VERSION "HNNBNNNYNNNNNNNNNNNNNNNNNNNNNNNNNNNNNNNNNN/4/%%%/4/'%**4NNN///"

NS_ :

BS_:

BU_: AWC BAP_Tester BMC_MLBevo BMS_MV BMS_NV CBC DCDC_800V_PAG DCDC_HV DCDC_HV_02 DCDC_IHEV FCU_MLBevo_FCEV Gateway Gateway_PAG Ladegeraet_2 Ladegeraet_Konzern LE1 LE2 LE_MLBevo Sub_Gateway TME

BO_ 881 BMS_CMC_02: 8 BMC_MLBevo
 SG_ BMS_CMC_02_MUX M  : 0|4@1+ (1,0) [0|15] ""  Sub_Gateway
 SG_ BMS_CMC_Zellspannung_081 m0  : 4|12@1+ (1,1000) [1000|5091] "Unit_MilliVolt"  Sub_Gateway
 SG_ BMS_CMC_Zellspannung_086 m1  : 4|12@1+ (1,1000) [1000|5091] "Unit_MilliVolt"  Sub_Gateway
 SG_ BMS_CMC_Zellspannung_091 m2  : 4|12@1+ (1,1000) [1000|5091] "Unit_MilliVolt"  Sub_Gateway
 SG_ BMS_CMC_Zellspannung_096 m3  : 4|12@1+ (1,1000) [1000|5091] "Unit_MilliVolt"  Sub_Gateway
 SG_ BMS_CMC_Zellspannung_101 m4  : 4|12@1+ (1,1000) [1000|5091] "Unit_MilliVolt"  Sub_Gateway
 SG_ BMS_CMC_Zellspannung_106 m5  : 4|12@1+ (1,1000) [1000|5091] "Unit_MilliVolt"  Sub_Gateway
 SG_ BMS_CMC_Zellspannung_111 m6  : 4|12@1+ (1,1000) [1000|5091] "Unit_MilliVolt"  Sub_Gateway
 SG_ BMS_CMC_Zellspannung_116 m7  : 4|12@1+ (1,1000) [1000|5091] "Unit_MilliVolt"  Sub_Gateway
 SG_ BMS_CMC_Zellspannung_121 m8  : 4|12@1+ (1,1000) [1000|5091] "Unit_MilliVolt"  Sub_Gateway
 SG_ BMS_CMC_Zellspannung_126 m9  : 4|12@1+ (1,1000) [1000|5091] "Unit_MilliVolt"  Sub_Gateway
 SG_ BMS_CMC_Zellspannung_131 m10  : 4|12@1+ (1,1000) [1000|5091] "Unit_MilliVolt"  Sub_Gateway
 SG_ BMS_CMC_Zellspannung_136 m11  : 4|12@1+ (1,1000) [1000|5091] "Unit_MilliVolt"  Sub_Gateway
 SG_ BMS_CMC_Zellspannung_141 m12  : 4|12@1+ (1,1000) [1000|5091] "Unit_MilliVolt"  Sub_Gateway
 SG_ BMS_CMC_Zellspannung_146 m13  : 4|12@1+ (1,1000) [1000|5091] "Unit_MilliVolt"  Sub_Gateway
 SG_ BMS_CMC_Zellspannung_151 m14  : 4|12@1+ (1,1000) [1000|5091] "Unit_MilliVolt"  Sub_Gateway
 SG_ BMS_CMC_Zellspannung_156 m15  : 4|12@1+ (1,1000) [1000|5091] "Unit_MilliVolt"  Sub_Gateway
 SG_ BMS_CMC_Zellspannung_082 m0  : 16|12@1+ (1,1000) [1000|5091] "Unit_MilliVolt"  Sub_Gateway
 SG_ BMS_CMC_Zellspannung_087 m1  : 16|12@1+ (1,1000) [1000|5091] "Unit_MilliVolt"  Sub_Gateway
 SG_ BMS_CMC_Zellspannung_092 m2  : 16|12@1+ (1,1000) [1000|5091] "Unit_MilliVolt"  Sub_Gateway
 SG_ BMS_CMC_Zellspannung_097 m3  : 16|12@1+ (1,1000) [1000|5091] "Unit_MilliVolt"  Sub_Gateway
 SG_ BMS_CMC_Zellspannung_102 m4  : 16|12@1+ (1,1000) [1000|5091] "Unit_MilliVolt"  Sub_Gateway
 SG_ BMS_CMC_Zellspannung_107 m5  : 16|12@1+ (1,1000) [1000|5091] "Unit_MilliVolt"  Sub_Gateway
 SG_ BMS_CMC_Zellspannung_112 m6  : 16|12@1+ (1,1000) [1000|5091] "Unit_MilliVolt"  Sub_Gateway
 SG_ BMS_CMC_Zellspannung_117 m7  : 16|12@1+ (1,1000) [1000|5091] "Unit_MilliVolt"  Sub_Gateway
 SG_ BMS_CMC_Zellspannung_122 m8  : 16|12@1+ (1,1000) [1000|5091] "Unit_MilliVolt"  Sub_Gateway
 SG_ BMS_CMC_Zellspannung_127 m9  : 16|12@1+ (1,1000) [1000|5091] "Unit_MilliVolt"  Sub_Gateway
 SG_ BMS_CMC_Zellspannung_132 m10  : 16|12@1+ (1,1000) [1000|5091] "Unit_MilliVolt"  Sub_Gateway
 SG_ BMS_CMC_Zellspannung_137 m11  : 16|12@1+ (1,1000) [1000|5091] "Unit_MilliVolt"  Sub_Gateway
 SG_ BMS_CMC_Zellspannung_142 m12  : 16|12@1+ (1,1000) [1000|5091] "Unit_MilliVolt"  Sub_Gateway
 SG_ BMS_CMC_Zellspannung_147 m13  : 16|12@1+ (1,1000) [1000|5091] "Unit_MilliVolt"  Sub_Gateway
 SG_ BMS_CMC_Zellspannung_152 m14  : 16|12@1+ (1,1000) [1000|5091] "Unit_MilliVolt"  Sub_Gateway
 SG_ BMS_CMC_Zellspannung_157 m15  : 16|12@1+ (1,1000) [1000|5091] "Unit_MilliVolt"  Sub_Gateway
 SG_ BMS_CMC_Zellspannung_083 m0  : 28|12@1+ (1,1000) [1000|5091] "Unit_MilliVolt"  Sub_Gateway
 SG_ BMS_CMC_Zellspannung_088 m1  : 28|12@1+ (1,1000) [1000|5091] "Unit_MilliVolt"  Sub_Gateway
 SG_ BMS_CMC_Zellspannung_093 m2  : 28|12@1+ (1,1000) [1000|5091] "Unit_MilliVolt"  Sub_Gateway
 SG_ BMS_CMC_Zellspannung_098 m3  : 28|12@1+ (1,1000) [1000|5091] "Unit_MilliVolt"  Sub_Gateway
 SG_ BMS_CMC_Zellspannung_103 m4  : 28|12@1+ (1,1000) [1000|5091] "Unit_MilliVolt"  Sub_Gateway
 SG_ BMS_CMC_Zellspannung_108 m5  : 28|12@1+ (1,1000) [1000|5091] "Unit_MilliVolt"  Sub_Gateway
 SG_ BMS_CMC_Zellspannung_113 m6  : 28|12@1+ (1,1000) [1000|5091] "Unit_MilliVolt"  Sub_Gateway
 SG_ BMS_CMC_Zellspannung_118 m7  : 28|12@1+ (1,1000) [1000|5091] "Unit_MilliVolt"  Sub_Gateway
 SG_ BMS_CMC_Zellspannung_123 m8  : 28|12@1+ (1,1000) [1000|5091] "Unit_MilliVolt"  Sub_Gateway
 SG_ BMS_CMC_Zellspannung_128 m9  : 28|12@1+ (1,1000) [1000|5091] "Unit_MilliVolt"  Sub_Gateway
 SG_ BMS_CMC_Zellspannung_133 m10  : 28|12@1+ (1,1000) [1000|5091] "Unit_MilliVolt"  Sub_Gateway
 SG_ BMS_CMC_Zellspannung_138 m11  : 28|12@1+ (1,1000) [1000|5091] "Unit_MilliVolt"  Sub_Gateway
 SG_ BMS_CMC_Zellspannung_143 m12  : 28|12@1+ (1,1000) [1000|5091] "Unit_MilliVolt"  Sub_Gateway
 SG_ BMS_CMC_Zellspannung_148 m13  : 28|12@1+ (1,1000) [1000|5091] "Unit_MilliVolt"  Sub_Gateway
 SG_ BMS_CMC_Zellspannung_153 m14  : 28|12@1+ (1,1000) [1000|5091] "Unit_MilliVolt"  Sub_Gateway
 SG_ BMS_CMC_Zellspannung_158 m15  : 28|12@1+ (1,1000) [1000|5091] "Unit_MilliVolt"  Sub_Gateway
 SG_ BMS_CMC_Zellspannung_084 m0  : 40|12@1+ (1,1000) [1000|5091] "Unit_MilliVolt"  Sub_Gateway
 SG_ BMS_CMC_Zellspannung_089 m1  : 40|12@1+ (1,1000) [1000|5091] "Unit_MilliVolt"  Sub_Gateway
 SG_ BMS_CMC_Zellspannung_094 m2  : 40|12@1+ (1,1000) [1000|5091] "Unit_MilliVolt"  Sub_Gateway
 SG_ BMS_CMC_Zellspannung_099 m3  : 40|12@1+ (1,1000) [1000|5091] "Unit_MilliVolt"  Sub_Gateway
 SG_ BMS_CMC_Zellspannung_104 m4  : 40|12@1+ (1,1000) [1000|5091] "Unit_MilliVolt"  Sub_Gateway
 SG_ BMS_CMC_Zellspannung_109 m5  : 40|12@1+ (1,1000) [1000|5091] "Unit_MilliVolt"  Sub_Gateway
 SG_ BMS_CMC_Zellspannung_114 m6  : 40|12@1+ (1,1000) [1000|5091] "Unit_MilliVolt"  Sub_Gateway
 SG_ BMS_CMC_Zellspannung_119 m7  : 40|12@1+ (1,1000) [1000|5091] "Unit_MilliVolt"  Sub_Gateway
 SG_ BMS_CMC_Zellspannung_124 m8  : 40|12@1+ (1,1000) [1000|5091] "Unit_MilliVolt"  Sub_Gateway
 SG_ BMS_CMC_Zellspannung_129 m9  : 40|12@1+ (1,1000) [1000|5091] "Unit_MilliVolt"  Sub_Gateway
 SG_ BMS_CMC_Zellspannung_134 m10  : 40|12@1+ (1,1000) [1000|5091] "Unit_MilliVolt"  Sub_Gateway
 SG_ BMS_CMC_Zellspannung_139 m11  : 40|12@1+ (1,1000) [1000|5091] "Unit_MilliVolt"  Sub_Gateway
 SG_ BMS_CMC_Zellspannung_144 m12  : 40|12@1+ (1,1000) [1000|5091] "Unit_MilliVolt"  Sub_Gateway
 SG_ BMS_CMC_Zellspannung_149 m13  : 40|12@1+ (1,1000) [1000|5091] "Unit_MilliVolt"  Sub_Gateway
 SG_ BMS_CMC_Zellspannung_154 m14  : 40|12@1+ (1,1000) [1000|5091] "Unit_MilliVolt"  Sub_Gateway
 SG_ BMS_CMC_Zellspannung_159 m15  : 40|12@1+ (1,1000) [1000|5091] "Unit_MilliVolt"  Sub_Gateway
 SG_ BMS_CMC_Zellspannung_085 m0  : 52|12@1+ (1,1000) [1000|5091] "Unit_MilliVolt"  Sub_Gateway
 SG_ BMS_CMC_Zellspannung_090 m1  : 52|12@1+ (1,1000) [1000|5091] "Unit_MilliVolt"  Sub_Gateway
 SG_ BMS_CMC_Zellspannung_095 m2  : 52|12@1+ (1,1000) [1000|5091] "Unit_MilliVolt"  Sub_Gateway
 SG_ BMS_CMC_Zellspannung_100 m3  : 52|12@1+ (1,1000) [1000|5091] "Unit_MilliVolt"  Sub_Gateway
 SG_ BMS_CMC_Zellspannung_105 m4  : 52|12@1+ (1,1000) [1000|5091] "Unit_MilliVolt"  Sub_Gateway
 SG_ BMS_CMC_Zellspannung_110 m5  : 52|12@1+ (1,1000) [1000|5091] "Unit_MilliVolt"  Sub_Gateway
 SG_ BMS_CMC_Zellspannung_115 m6  : 52|12@1+ (1,1000) [1000|5091] "Unit_MilliVolt"  Sub_Gateway
 SG_ BMS_CMC_Zellspannung_120 m7  : 52|12@1+ (1,1000) [1000|5091] "Unit_MilliVolt"  Sub_Gateway
 SG_ BMS_CMC_Zellspannung_125 m8  : 52|12@1+ (1,1000) [1000|5091] "Unit_MilliVolt"  Sub_Gateway
 SG_ BMS_CMC_Zellspannung_130 m9  : 52|12@1+ (1,1000) [1000|5091] "Unit_MilliVolt"  Sub_Gateway
 SG_ BMS_CMC_Zellspannung_135 m10  : 52|12@1+ (1,1000) [1000|5091] "Unit_MilliVolt"  Sub_Gateway
 SG_ BMS_CMC_Zellspannung_140 m11  : 52|12@1+ (1,1000) [1000|5091] "Unit_MilliVolt"  Sub_Gateway
 SG_ BMS_CMC_Zellspannung_145 m12  : 52|12@1+ (1,1000) [1000|5091] "Unit_MilliVolt"  Sub_Gateway
 SG_ BMS_CMC_Zellspannung_150 m13  : 52|12@1+ (1,1000) [1000|5091] "Unit_MilliVolt"  Sub_Gateway
 SG_ BMS_CMC_Zellspannung_155 m14  : 52|12@1+ (1,1000) [1000|5091] "Unit_MilliVolt"  Sub_Gateway
 SG_ BMS_CMC_Zellspannung_160 m15  : 52|12@1+ (1,1000) [1000|5091] "Unit_MilliVolt"  Sub_Gateway

BO_ 2463978713 BMS_CMC_03: 8 BMC_MLBevo
 SG_ BMS_CMC_03_MUX M  : 0|3@1+ (1,0) [0|7] ""  Sub_Gateway
 SG_ BMS_CMC_Temperatur_001 m0  : 8|8@1+ (0.5,-40) [-40.0|86.0] "Unit_DegreCelsi"  Sub_Gateway
 SG_ BMS_CMC_Temperatur_008 m1  : 8|8@1+ (0.5,-40) [-40.0|86.0] "Unit_DegreCelsi"  Sub_Gateway
 SG_ BMS_CMC_Temperatur_015 m2  : 8|8@1+ (0.5,-40) [-40.0|86.0] "Unit_DegreCelsi"  Sub_Gateway
 SG_ BMS_CMC_Temperatur_022 m3  : 8|8@1+ (0.5,-40) [-40.0|86.0] "Unit_DegreCelsi"  Sub_Gateway
 SG_ BMS_CMC_Temperatur_029 m4  : 8|8@1+ (0.5,-40) [-40.0|86.0] "Unit_DegreCelsi"  Sub_Gateway
 SG_ BMS_CMC_Temperatur_036 m5  : 8|8@1+ (0.5,-40) [-40.0|86.0] "Unit_DegreCelsi"  Sub_Gateway
 SG_ BMS_CMC_Temperatur_043 m6  : 8|8@1+ (0.5,-40) [-40.0|86.0] "Unit_DegreCelsi"  Sub_Gateway
 SG_ BMS_CMC_Temperatur_050 m7  : 8|8@1+ (0.5,-40) [-40.0|86.0] "Unit_DegreCelsi"  Sub_Gateway
 SG_ BMS_CMC_Temperatur_002 m0  : 16|8@1+ (0.5,-40) [-40.0|86.0] "Unit_DegreCelsi"  Sub_Gateway
 SG_ BMS_CMC_Temperatur_009 m1  : 16|8@1+ (0.5,-40) [-40.0|86.0] "Unit_DegreCelsi"  Sub_Gateway
 SG_ BMS_CMC_Temperatur_016 m2  : 16|8@1+ (0.5,-40) [-40.0|86.0] "Unit_DegreCelsi"  Sub_Gateway
 SG_ BMS_CMC_Temperatur_023 m3  : 16|8@1+ (0.5,-40) [-40.0|86.0] "Unit_DegreCelsi"  Sub_Gateway
 SG_ BMS_CMC_Temperatur_030 m4  : 16|8@1+ (0.5,-40) [-40.0|86.0] "Unit_DegreCelsi"  Sub_Gateway
 SG_ BMS_CMC_Temperatur_037 m5  : 16|8@1+ (0.5,-40) [-40.0|86.0] "Unit_DegreCelsi"  Sub_Gateway
 SG_ BMS_CMC_Temperatur_044 m6  : 16|8@1+ (0.5,-40) [-40.0|86.0] "Unit_DegreCelsi"  Sub_Gateway
 SG_ BMS_CMC_Temperatur_051 m7  : 16|8@1+ (0.5,-40) [-40.0|86.0] "Unit_DegreCelsi"  Sub_Gateway
 SG_ BMS_CMC_Temperatur_003 m0  : 24|8@1+ (0.5,-40) [-40.0|86.0] "Unit_DegreCelsi"  Sub_Gateway
 SG_ BMS_CMC_Temperatur_010 m1  : 24|8@1+ (0.5,-40) [-40.0|86.0] "Unit_DegreCelsi"  Sub_Gateway
 SG_ BMS_CMC_Temperatur_017 m2  : 24|8@1+ (0.5,-40) [-40.0|86.0] "Unit_DegreCelsi"  Sub_Gateway
 SG_ BMS_CMC_Temperatur_024 m3  : 24|8@1+ (0.5,-40) [-40.0|86.0] "Unit_DegreCelsi"  Sub_Gateway
 SG_ BMS_CMC_Temperatur_031 m4  : 24|8@1+ (0.5,-40) [-40.0|86.0] "Unit_DegreCelsi"  Sub_Gateway
 SG_ BMS_CMC_Temperatur_038 m5  : 24|8@1+ (0.5,-40) [-40.0|86.0] "Unit_DegreCelsi"  Sub_Gateway
 SG_ BMS_CMC_Temperatur_045 m6  : 24|8@1+ (0.5,-40) [-40.0|86.0] "Unit_DegreCelsi"  Sub_Gateway
 SG_ BMS_CMC_Temperatur_052 m7  : 24|8@1+ (0.5,-40) [-40.0|86.0] "Unit_DegreCelsi"  Sub_Gateway
 SG_ BMS_CMC_Temperatur_004 m0  : 32|8@1+ (0.5,-40) [-40.0|86.0] "Unit_DegreCelsi"  Sub_Gateway
 SG_ BMS_CMC_Temperatur_011 m1  : 32|8@1+ (0.5,-40) [-40.0|86.0] "Unit_DegreCelsi"  Sub_Gateway
 SG_ BMS_CMC_Temperatur_018 m2  : 32|8@1+ (0.5,-40) [-40.0|86.0] "Unit_DegreCelsi"  Sub_Gateway
 SG_ BMS_CMC_Temperatur_025 m3  : 32|8@1+ (0.5,-40) [-40.0|86.0] "Unit_DegreCelsi"  Sub_Gateway
 SG_ BMS_CMC_Temperatur_032 m4  : 32|8@1+ (0.5,-40) [-40.0|86.0] "Unit_DegreCelsi"  Sub_Gateway
 SG_ BMS_CMC_Temperatur_039 m5  : 32|8@1+ (0.5,-40) [-40.0|86.0] "Unit_DegreCelsi"  Sub_Gateway
 SG_ BMS_CMC_Temperatur_046 m6  : 32|8@1+ (0.5,-40) [-40.0|86.0] "Unit_DegreCelsi"  Sub_Gateway
 SG_ BMS_CMC_Temperatur_053 m7  : 32|8@1+ (0.5,-40) [-40.0|86.0] "Unit_DegreCelsi"  Sub_Gateway
 SG_ BMS_CMC_Temperatur_005 m0  : 40|8@1+ (0.5,-40) [-40.0|86.0] "Unit_DegreCelsi"  Sub_Gateway
 SG_ BMS_CMC_Temperatur_012 m1  : 40|8@1+ (0.5,-40) [-40.0|86.0] "Unit_DegreCelsi"  Sub_Gateway
 SG_ BMS_CMC_Temperatur_019 m2  : 40|8@1+ (0.5,-40) [-40.0|86.0] "Unit_DegreCelsi"  Sub_Gateway
 SG_ BMS_CMC_Temperatur_026 m3  : 40|8@1+ (0.5,-40) [-40.0|86.0] "Unit_DegreCelsi"  Sub_Gateway
 SG_ BMS_CMC_Temperatur_033 m4  : 40|8@1+ (0.5,-40) [-40.0|86.0] "Unit_DegreCelsi"  Sub_Gateway
 SG_ BMS_CMC_Temperatur_040 m5  : 40|8@1+ (0.5,-40) [-40.0|86.0] "Unit_DegreCelsi"  Sub_Gateway
 SG_ BMS_CMC_Temperatur_047 m6  : 40|8@1+ (0.5,-40) [-40.0|86.0] "Unit_DegreCelsi"  Sub_Gateway
 SG_ BMS_CMC_Temperatur_054 m7  : 40|8@1+ (0.5,-40) [-40.0|86.0] "Unit_DegreCelsi"  Sub_Gateway
 SG_ BMS_CMC_Temperatur_006 m0  : 48|8@1+ (0.5,-40) [-40.0|86.0] "Unit_DegreCelsi"  Sub_Gateway
 SG_ BMS_CMC_Temperatur_013 m1  : 48|8@1+ (0.5,-40) [-40.0|86.0] "Unit_DegreCelsi"  Sub_Gateway
 SG_ BMS_CMC_Temperatur_020 m2  : 48|8@1+ (0.5,-40) [-40.0|86.0] "Unit_DegreCelsi"  Sub_Gateway
 SG_ BMS_CMC_Temperatur_027 m3  : 48|8@1+ (0.5,-40) [-40.0|86.0] "Unit_DegreCelsi"  Sub_Gateway
 SG_ BMS_CMC_Temperatur_034 m4  : 48|8@1+ (0.5,-40) [-40.0|86.0] "Unit_DegreCelsi"  Sub_Gateway
 SG_ BMS_CMC_Temperatur_041 m5  : 48|8@1+ (0.5,-40) [-40.0|86.0] "Unit_DegreCelsi"  Sub_Gateway
 SG_ BMS_CMC_Temperatur_048 m6  : 48|8@1+ (0.5,-40) [-40.0|86.0] "Unit_DegreCelsi"  Sub_Gateway
 SG_ BMS_CMC_Temperatur_055 m7  : 48|8@1+ (0.5,-40) [-40.0|86.0] "Unit_DegreCelsi"  Sub_Gateway
 SG_ BMS_CMC_Temperatur_007 m0  : 56|8@1+ (0.5,-40) [-40.0|86.0] "Unit_DegreCelsi"  Sub_Gateway
 SG_ BMS_CMC_Temperatur_014 m1  : 56|8@1+ (0.5,-40) [-40.0|86.0] "Unit_DegreCelsi"  Sub_Gateway
 SG_ BMS_CMC_Temperatur_021 m2  : 56|8@1+ (0.5,-40) [-40.0|86.0] "Unit_DegreCelsi"  Sub_Gateway
 SG_ BMS_CMC_Temperatur_028 m3  : 56|8@1+ (0.5,-40) [-40.0|86.0] "Unit_DegreCelsi"  Sub_Gateway
 SG_ BMS_CMC_Temperatur_035 m4  : 56|8@1+ (0.5,-40) [-40.0|86.0] "Unit_DegreCelsi"  Sub_Gateway
 SG_ BMS_CMC_Temperatur_042 m5  : 56|8@1+ (0.5,-40) [-40.0|86.0] "Unit_DegreCelsi"  Sub_Gateway
 SG_ BMS_CMC_Temperatur_049 m6  : 56|8@1+ (0.5,-40) [-40.0|86.0] "Unit_DegreCelsi"  Sub_Gateway
 SG_ BMS_CMC_Temperatur_056 m7  : 56|8@1+ (0.5,-40) [-40.0|86.0] "Unit_DegreCelsi"  Sub_Gateway

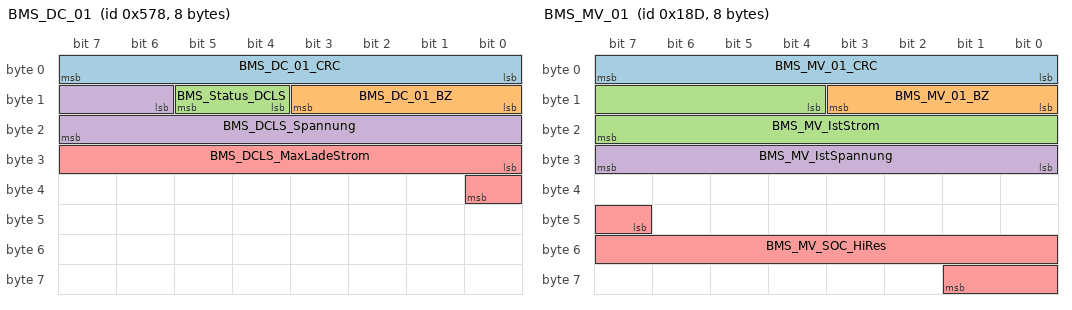
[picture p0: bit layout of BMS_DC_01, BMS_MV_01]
BO_ 1400 BMS_DC_01: 8 BMC_MLBevo
 SG_ BMS_DC_01_CRC : 0|8@1+ (1,0) [0|255] ""  Ladegeraet_Konzern
 SG_ BMS_DC_01_BZ : 8|4@1+ (1,0) [0|15] ""  Ladegeraet_Konzern
 SG_ BMS_Status_DCLS : 12|2@1+ (1.0,0.0) [0.0|3] ""  Ladegeraet_Konzern
 SG_ BMS_DCLS_Spannung : 14|10@1+ (1,0) [0|1021] "Unit_Volt"  Ladegeraet_Konzern
 SG_ BMS_DCLS_MaxLadeStrom : 24|9@1+ (1,0) [0|400] "Unit_Amper"  Ladegeraet_Konzern

BO_ 397 BMS_MV_01: 8 BMS_MV
 SG_ BMS_MV_01_CRC : 0|8@1+ (1,0) [0|255] ""  Gateway,Gateway_PAG
 SG_ BMS_MV_01_BZ : 8|4@1+ (1,0) [0|15] ""  Gateway,Gateway_PAG
 SG_ BMS_MV_IstStrom : 12|12@1+ (1,-2047) [-2047|2046] "Unit_Amper"  DCDC_IHEV,Gateway,Gateway_PAG
 SG_ BMS_MV_IstSpannung : 24|8@1+ (0.25,0) [0.00|63.25] "Unit_Volt"  DCDC_IHEV,Gateway,Gateway_PAG
 SG_ BMS_MV_SOC_HiRes : 47|11@1+ (0.05,0) [0.00|100.00] "Unit_PerCent"  Gateway,Gateway_PAG

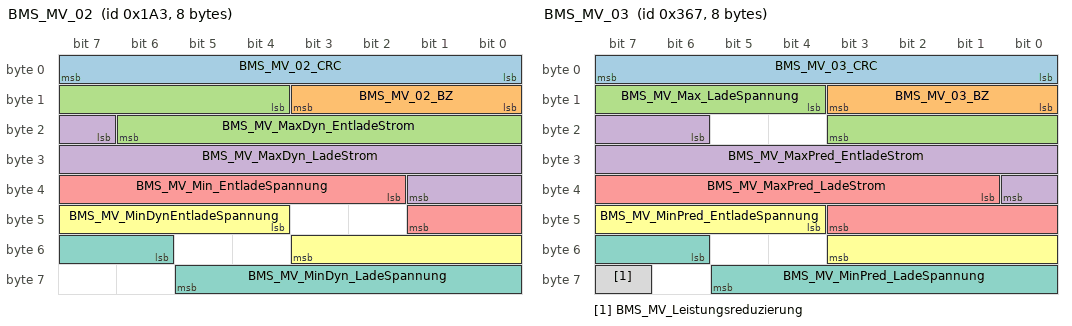
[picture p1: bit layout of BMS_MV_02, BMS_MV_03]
BO_ 419 BMS_MV_02: 8 BMS_MV
 SG_ BMS_MV_02_CRC : 0|8@1+ (1,0) [0|255] ""  Gateway,Gateway_PAG
 SG_ BMS_MV_02_BZ : 8|4@1+ (1,0) [0|15] ""  Gateway,Gateway_PAG
 SG_ BMS_MV_MaxDyn_EntladeStrom : 12|11@1+ (1,0) [0|2045] "Unit_Amper"  DCDC_IHEV,Gateway,Gateway_PAG
 SG_ BMS_MV_MaxDyn_LadeStrom : 23|11@1+ (1,0) [0|2045] "Unit_Amper"  Gateway,Gateway_PAG
 SG_ BMS_MV_Min_EntladeSpannung : 34|8@1+ (0.25,0) [0.00|63.25] "Unit_Volt"  Gateway,Gateway_PAG
 SG_ BMS_MV_MinDynEntladeSpannung : 44|8@1+ (0.25,0) [0.00|63.25] "Unit_Volt"  Gateway,Gateway_PAG
 SG_ BMS_MV_MinDyn_LadeSpannung : 54|8@1+ (0.25,0) [0.00|63.25] "Unit_Volt"  Gateway,Gateway_PAG

BO_ 871 BMS_MV_03: 8 BMS_MV
 SG_ BMS_MV_03_CRC : 0|8@1+ (1,0) [0|255] ""  Gateway,Gateway_PAG
 SG_ BMS_MV_03_BZ : 8|4@1+ (1,0) [0|15] ""  Gateway,Gateway_PAG
 SG_ BMS_MV_Max_LadeSpannung : 12|8@1+ (0.25,0) [0.00|63.25] "Unit_Volt"  Gateway,Gateway_PAG
 SG_ BMS_MV_MaxPred_EntladeStrom : 22|11@1+ (1,0) [0|2045] "Unit_Amper"  Gateway,Gateway_PAG
 SG_ BMS_MV_MaxPred_LadeStrom : 33|11@1+ (1,0) [0|2045] "Unit_Amper"  Gateway,Gateway_PAG
 SG_ BMS_MV_MinPred_EntladeSpannung : 44|8@1+ (0.25,0) [0.00|63.25] "Unit_Volt"  Gateway,Gateway_PAG
 SG_ BMS_MV_MinPred_LadeSpannung : 54|8@1+ (0.25,0) [0.00|63.25] "Unit_Volt"  Gateway,Gateway_PAG
 SG_ BMS_MV_Leistungsreduzierung : 63|1@1+ (1.0,0.0) [0.0|1] ""  Gateway,Gateway_PAG

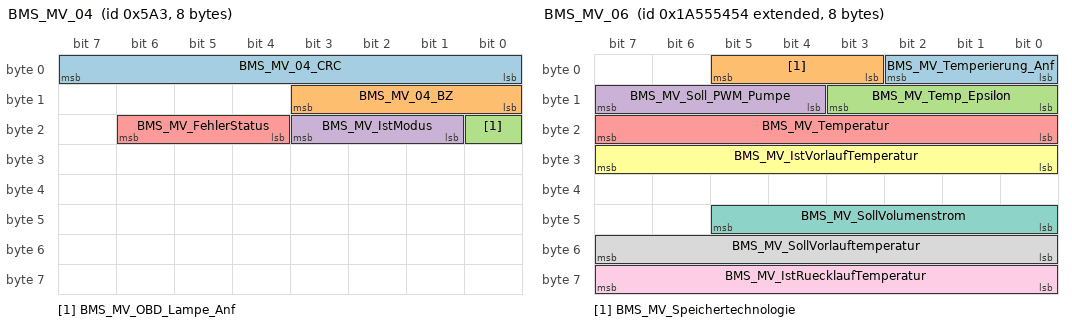
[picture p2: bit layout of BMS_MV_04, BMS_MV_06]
BO_ 1443 BMS_MV_04: 8 BMS_MV
 SG_ BMS_MV_04_CRC : 0|8@1+ (1,0) [0|255] ""  Gateway,Gateway_PAG
 SG_ BMS_MV_04_BZ : 8|4@1+ (1,0) [0|15] ""  Gateway,Gateway_PAG
 SG_ BMS_MV_OBD_Lampe_Anf : 16|1@1+ (1.0,0.0) [0.0|1] ""  Gateway,Gateway_PAG
 SG_ BMS_MV_IstModus : 17|3@1+ (1.0,0.0) [0.0|7] ""  DCDC_IHEV,Gateway,Gateway_PAG
 SG_ BMS_MV_FehlerStatus : 20|3@1+ (1.0,0.0) [0.0|7] ""  Gateway,Gateway_PAG

BO_ 2589283412 BMS_MV_06: 8 BMS_MV
 SG_ BMS_MV_Temperierung_Anf : 0|3@1+ (1.0,0.0) [0.0|7] ""  Gateway,Gateway_PAG,TME
 SG_ BMS_MV_Speichertechnologie : 3|3@1+ (1.0,0.0) [0.0|7] ""  Gateway,Gateway_PAG
 SG_ BMS_MV_Temp_Epsilon : 8|4@1+ (1,-15) [-15|0] "Unit_DegreCelsi"  Gateway,Gateway_PAG,TME
 SG_ BMS_MV_Soll_PWM_Pumpe : 12|4@1+ (10,0) [0|100] "Unit_PerCent"  Gateway,Gateway_PAG,TME
 SG_ BMS_MV_Temperatur : 16|8@1+ (0.5,-40) [-40.0|86.5] "Unit_DegreCelsi"  DCDC_IHEV,Gateway,Gateway_PAG,TME
 SG_ BMS_MV_IstVorlaufTemperatur : 24|8@1+ (0.5,-40) [-40.0|86.5] "Unit_DegreCelsi"  Gateway,Gateway_PAG,TME
 SG_ BMS_MV_SollVolumenstrom : 40|6@1+ (1,0) [0|61] ""  Gateway,Gateway_PAG,TME
 SG_ BMS_MV_SollVorlauftemperatur : 48|8@1+ (0.5,-40) [-40.0|86.5] "Unit_DegreCelsi"  Gateway,Gateway_PAG,TME
 SG_ BMS_MV_IstRuecklaufTemperatur : 56|8@1+ (0.5,-40) [-40.0|86.5] "Unit_DegreCelsi"  Gateway,Gateway_PAG,TME

BO_ 2589283608 BMS_MV_07: 8 BMS_MV
 SG_ BMS_MV_Energieinhalt : 12|11@1+ (1,0) [0|2045] "Unit_WattHour"  Gateway,Gateway_PAG
 SG_ BMS_MV_MaxEnergieinhalt : 32|11@1+ (1,0) [0|2045] "Unit_WattHour"  Gateway,Gateway_PAG

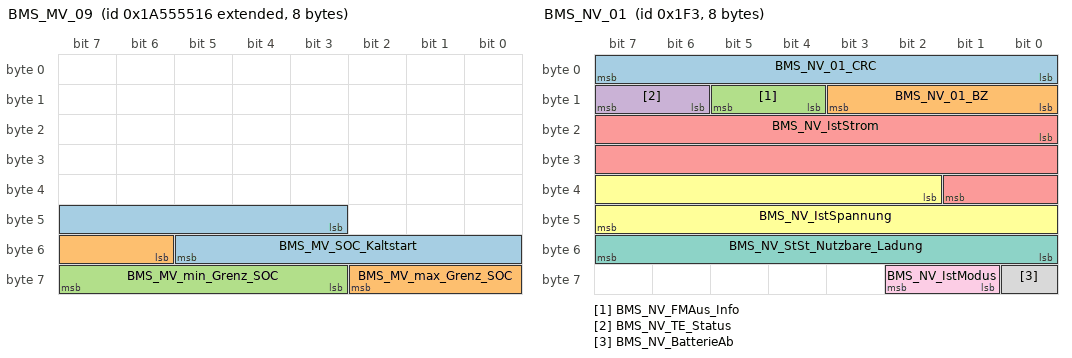
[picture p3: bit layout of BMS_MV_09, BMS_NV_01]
BO_ 2589283606 BMS_MV_09: 8 BMS_MV
 SG_ BMS_MV_SOC_Kaltstart : 43|11@1+ (0.05,0) [0.00|100.00] "Unit_PerCent"  Gateway,Gateway_PAG
 SG_ BMS_MV_max_Grenz_SOC : 54|5@1+ (1,70) [70|100] "Unit_PerCent"  Gateway,Gateway_PAG
 SG_ BMS_MV_min_Grenz_SOC : 59|5@1+ (1,0) [0|30] "Unit_PerCent"  Gateway,Gateway_PAG

BO_ 1021 BMS_MV_10: 8 BMS_MV
 SG_ BMS_MV_Pred_Entladeperformance : 50|7@1+ (1,0) [0|100] "Unit_PerCent"  Gateway,Gateway_PAG
 SG_ BMS_MV_Pred_Ladeperformance : 57|7@1+ (1,0) [0|100] "Unit_PerCent"  Gateway,Gateway_PAG

BO_ 499 BMS_NV_01: 8 BMS_NV
 SG_ BMS_NV_01_CRC : 0|8@1+ (1,0) [0|255] ""  Gateway,Gateway_PAG
 SG_ BMS_NV_01_BZ : 8|4@1+ (1,0) [0|15] ""  Gateway,Gateway_PAG
 SG_ BMS_NV_FMAus_Info : 12|2@1+ (1.0,0.0) [0.0|3] ""  Gateway,Gateway_PAG
 SG_ BMS_NV_TE_Status : 14|2@1+ (1.0,0.0) [0.0|3] ""  Gateway,Gateway_PAG
 SG_ BMS_NV_IstStrom : 16|18@1+ (0.01,-1300) [-1300.00|1300.00] "Unit_Amper"  Gateway,Gateway_PAG
 SG_ BMS_NV_IstSpannung : 34|14@1+ (0.001,4) [4.000|20.381] "Unit_Volt"  Gateway,Gateway_PAG
 SG_ BMS_NV_StSt_Nutzbare_Ladung : 48|8@1+ (50,0) [0|12650] "Unit_AmperSecon"  Gateway,Gateway_PAG
 SG_ BMS_NV_BatterieAb : 56|1@1+ (1.0,0.0) [0.0|1] ""  Gateway,Gateway_PAG
 SG_ BMS_NV_IstModus : 57|2@1+ (1.0,0.0) [0.0|3] ""  Gateway,Gateway_PAG

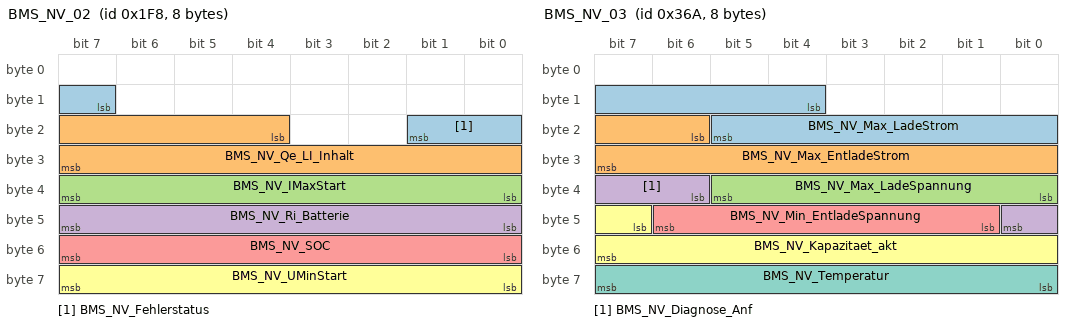
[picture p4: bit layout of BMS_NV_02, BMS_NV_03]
BO_ 504 BMS_NV_02: 8 BMS_NV
 SG_ BMS_NV_Fehlerstatus : 15|3@1+ (1.0,0.0) [0.0|7] ""  Gateway,Gateway_PAG
 SG_ BMS_NV_Qe_LI_Inhalt : 20|12@1+ (0.01,0) [0.00|40.00] "Unit_AmperHour"  Gateway,Gateway_PAG
 SG_ BMS_NV_IMaxStart : 32|8@1+ (4,1) [1|1013] "Unit_Amper"  Gateway,Gateway_PAG
 SG_ BMS_NV_Ri_Batterie : 40|8@1+ (0.2,0) [0.0|50.6] "Unit_MilliOhm"  Gateway,Gateway_PAG
 SG_ BMS_NV_SOC : 48|8@1+ (0.4,0) [0.0|100.0] "Unit_PerCent"  Gateway,Gateway_PAG
 SG_ BMS_NV_UMinStart : 56|8@1+ (0.05,2) [2.00|14.65] "Unit_Volt"  Gateway,Gateway_PAG

BO_ 874 BMS_NV_03: 8 BMS_NV
 SG_ BMS_NV_Max_LadeStrom : 12|10@1+ (1,0) [0|850] "Unit_Amper"  Gateway,Gateway_PAG
 SG_ BMS_NV_Max_EntladeStrom : 22|10@1+ (1,0) [0|850] "Unit_Amper"  Gateway,Gateway_PAG
 SG_ BMS_NV_Max_LadeSpannung : 32|6@1+ (0.1,11) [11.0|17.1] "Unit_Volt"  Gateway,Gateway_PAG
 SG_ BMS_NV_Diagnose_Anf : 38|3@1+ (1.0,0.0) [0.0|7] ""  Gateway,Gateway_PAG
 SG_ BMS_NV_Min_EntladeSpannung : 41|6@1+ (0.1,8) [8.0|14.1] "Unit_Volt"  Gateway,Gateway_PAG
 SG_ BMS_NV_Kapazitaet_akt : 47|9@1+ (0.1,0) [0.0|40.0] "Unit_AmperHour"  Gateway,Gateway_PAG
 SG_ BMS_NV_Temperatur : 56|8@1+ (1,-55) [-55|127] "Unit_DegreCelsi"  Gateway,Gateway_PAG

BO_ 2463978664 BMS_NV_04: 8 BMS_NV
 SG_ BMS_NV_Polspannung : 55|9@1+ (0.01,10.5) [10.50|15.59] "Unit_Volt"  Gateway,Gateway_PAG

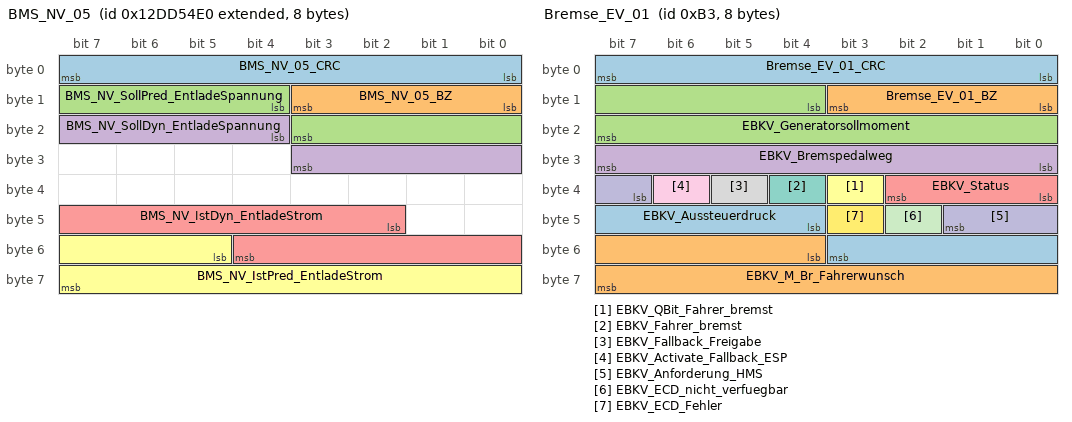
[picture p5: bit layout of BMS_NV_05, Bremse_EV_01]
BO_ 2463978720 BMS_NV_05: 8 BMS_NV
 SG_ BMS_NV_05_CRC : 0|8@1+ (1,0) [0|255] ""  Gateway,Gateway_PAG
 SG_ BMS_NV_05_BZ : 8|4@1+ (1,0) [0|15] ""  Gateway,Gateway_PAG
 SG_ BMS_NV_SollPred_EntladeSpannung : 12|8@1+ (0.05,4) [4.00|16.65] "Unit_Volt"  Gateway,Gateway_PAG
 SG_ BMS_NV_SollDyn_EntladeSpannung : 20|8@1+ (0.05,4) [4.00|16.65] "Unit_Volt"  Gateway,Gateway_PAG
 SG_ BMS_NV_IstDyn_EntladeStrom : 42|11@1+ (1,0) [0|2045] "Unit_Amper"  Gateway,Gateway_PAG
 SG_ BMS_NV_IstPred_EntladeStrom : 53|11@1+ (1,0) [0|2045] "Unit_Amper"  Gateway,Gateway_PAG

BO_ 179 Bremse_EV_01: 8 Gateway
 SG_ Bremse_EV_01_CRC : 0|8@1+ (1,0) [0|255] ""  Sub_Gateway
 SG_ Bremse_EV_01_BZ : 8|4@1+ (1,0) [0|15] ""  Sub_Gateway
 SG_ EBKV_Generatorsollmoment : 12|12@1+ (1.5,0) [0.0|6120.0] "Unit_NewtoMeter"  Sub_Gateway
 SG_ EBKV_Bremspedalweg : 24|8@1+ (0.4,-0.4) [0.0|101.2] "Unit_PerCent"  Sub_Gateway
 SG_ EBKV_Status : 32|3@1+ (1.0,0.0) [0.0|7] ""  Sub_Gateway
 SG_ EBKV_QBit_Fahrer_bremst : 35|1@1+ (1.0,0.0) [0.0|1] ""  Sub_Gateway
 SG_ EBKV_Fahrer_bremst : 36|1@1+ (1.0,0.0) [0.0|1] ""  Sub_Gateway
 SG_ EBKV_Fallback_Freigabe : 37|1@1+ (1.0,0.0) [0.0|1] ""  Sub_Gateway
 SG_ EBKV_Activate_Fallback_ESP : 38|1@1+ (1.0,0.0) [0.0|1] ""  Sub_Gateway
 SG_ EBKV_Anforderung_HMS : 39|3@1+ (1.0,0.0) [0.0|7] ""  Sub_Gateway
 SG_ EBKV_ECD_nicht_verfuegbar : 42|1@1+ (1.0,0.0) [0.0|1] ""  Sub_Gateway
 SG_ EBKV_ECD_Fehler : 43|1@1+ (1.0,0.0) [0.0|1] ""  Sub_Gateway
 SG_ EBKV_Aussteuerdruck : 44|8@1+ (1,0) [0|250] "Unit_Bar"  Sub_Gateway
 SG_ EBKV_M_Br_Fahrerwunsch : 52|12@1+ (4,0) [0|16372] "Unit_NewtoMeter"  Sub_Gateway

BO_ 2617236992 CCP_BMS_CRO_01: 8 Vector__XXX
 SG_ CCP_BMS_CRO_01_Data : 0|64@1+ (1,0) [0|1] ""  BMC_MLBevo

BO_ 2617236993 CCP_BMS_DTO_01: 8 BMC_MLBevo
 SG_ CCP_BMS_DTO_01_Data : 0|64@1+ (1,0) [0|1] ""  Vector__XXX

BO_ 2617130752 CCP_DCDC_HV_02_CRO_01: 8 Vector__XXX
 SG_ CCP_DCDC_HV_02_CRO_01_Data : 0|64@1+ (1.0,0.0) [0.0|18446744073709551615] ""  DCDC_HV_02

BO_ 2617130753 CCP_DCDC_HV_02_DTO_01: 8 DCDC_HV_02
 SG_ CCP_DCDC_HV_02_DTO_01_Data : 0|64@1+ (1.0,0.0) [0.0|18446744073709551615] ""  Vector__XXX

BO_ 2617194240 CCP_Ladegeraet_2_CRO_01: 8 Vector__XXX
 SG_ CCP_Ladegeraet_2_CRO_01_Data : 0|64@1+ (1.0,0.0) [0.0|18446744073709551615] ""  Ladegeraet_2

BO_ 2617194241 CCP_Ladegeraet_2_DTO_01: 8 Ladegeraet_2
 SG_ CCP_Ladegeraet_2_DTO_01_Data : 0|64@1+ (1.0,0.0) [0.0|18446744073709551615] ""  Vector__XXX

BO_ 2617124352 CCP_Ladegeraet_CRO_01: 8 Vector__XXX
 SG_ CCP_Ladegeraet_CRO_01_Data : 0|64@1+ (1.0,0.0) [0.0|18446744073709551615] ""  Ladegeraet_Konzern

BO_ 2617124353 CCP_Ladegeraet_DTO_01: 8 Ladegeraet_Konzern
 SG_ CCP_Ladegeraet_DTO_01_Data : 0|64@1+ (1.0,0.0) [0.0|18446744073709551615] ""  Vector__XXX

BO_ 901 Charisma_01: 8 Gateway
 SG_ CHA_Ziel_FahrPr_AGA : 0|4@1+ (1.0,0.0) [0.0|15] ""  Sub_Gateway
 SG_ CHA_Ziel_FahrPr_ESP : 4|4@1+ (1.0,0.0) [0.0|15] ""  Sub_Gateway
 SG_ CHA_Ziel_FahrPr_Freilauf : 8|4@1+ (1.0,0.0) [0.0|15] ""  Sub_Gateway
 SG_ CHA_Fahrer_Umschaltung : 14|1@1+ (1.0,0.0) [0.0|1] ""  Sub_Gateway
 SG_ CHA_Fahrer_Umschaltung_BMA : 15|1@1+ (1.0,0.0) [0.0|1] ""  Sub_Gateway
 SG_ CHA_Ziel_FahrPr_MO : 16|4@1+ (1.0,0.0) [0.0|15] ""  Sub_Gateway
 SG_ CHA_Ziel_FahrPr_GE : 20|4@1+ (1.0,0.0) [0.0|15] ""  Sub_Gateway
 SG_ CHA_Ziel_FahrPr_ALR : 24|4@1+ (1.0,0.0) [0.0|15] ""  Sub_Gateway
 SG_ CHA_Ziel_FahrPr_MO_BZS : 28|4@1+ (1.0,0.0) [0.0|15] ""  Sub_Gateway,TME
 SG_ CHA_Ziel_FahrPr_DR : 32|4@1+ (1.0,0.0) [0.0|15] ""  Sub_Gateway
 SG_ CHA_Ziel_FahrPr_VAQ : 36|4@1+ (1.0,0.0) [0.0|15] ""  Sub_Gateway
 SG_ CHA_Ziel_FahrPr_AFS : 40|4@1+ (1.0,0.0) [0.0|15] ""  Sub_Gateway
 SG_ CHA_Ziel_FahrPr_PreCrash : 44|4@1+ (1.0,0.0) [0.0|15] ""  Sub_Gateway
 SG_ CHA_Ziel_FahrPr_EPS : 48|4@1+ (1.0,0.0) [0.0|15] ""  Sub_Gateway
 SG_ CHA_Ziel_FahrPr_ACC : 52|4@1+ (1.0,0.0) [0.0|15] ""  Sub_Gateway
 SG_ CHA_Ziel_FahrPr_SAK : 56|4@1+ (1.0,0.0) [0.0|15] ""  Sub_Gateway
 SG_ CHA_Ziel_FahrPr_MO_StSt : 60|4@1+ (1.0,0.0) [0.0|15] ""  Sub_Gateway

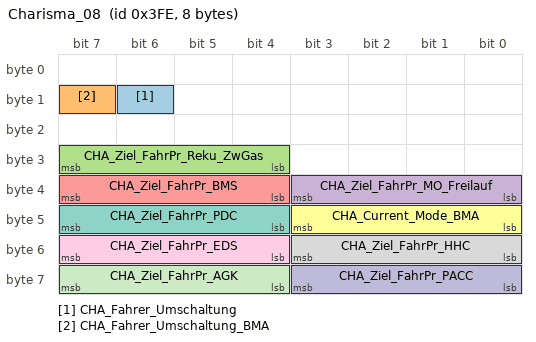
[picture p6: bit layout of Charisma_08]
BO_ 1022 Charisma_08: 8 Gateway
 SG_ CHA_Fahrer_Umschaltung : 14|1@1+ (1.0,0.0) [0.0|1] ""  Vector__XXX
 SG_ CHA_Fahrer_Umschaltung_BMA : 15|1@1+ (1.0,0.0) [0.0|1] ""  Vector__XXX
 SG_ CHA_Ziel_FahrPr_Reku_ZwGas : 28|4@1+ (1.0,0.0) [0.0|15] ""  Vector__XXX
 SG_ CHA_Ziel_FahrPr_MO_Freilauf : 32|4@1+ (1.0,0.0) [0.0|15] ""  Vector__XXX
 SG_ CHA_Ziel_FahrPr_BMS : 36|4@1+ (1.0,0.0) [0.0|15] ""  BMC_MLBevo
 SG_ CHA_Current_Mode_BMA : 40|4@1+ (1.0,0.0) [0.0|15] ""  Vector__XXX
 SG_ CHA_Ziel_FahrPr_PDC : 44|4@1+ (1.0,0.0) [0.0|15] ""  Vector__XXX
 SG_ CHA_Ziel_FahrPr_HHC : 48|4@1+ (1.0,0.0) [0.0|15] ""  Vector__XXX
 SG_ CHA_Ziel_FahrPr_EDS : 52|4@1+ (1.0,0.0) [0.0|15] ""  Vector__XXX
 SG_ CHA_Ziel_FahrPr_PACC : 56|4@1+ (1.0,0.0) [0.0|15] ""  Vector__XXX
 SG_ CHA_Ziel_FahrPr_AGK : 60|4@1+ (1.0,0.0) [0.0|15] ""  Vector__XXX

BO_ 2589283686 DC_MV_CALID_CVN: 8 DCDC_IHEV
 SG_ DC_MV_CALID_CVN_MUX M  : 0|2@1+ (1,0) [0|3] "Unit_None"  BMS_MV,Gateway,Gateway_PAG
 SG_ DC_MV_CVN_VLD : 7|1@1+ (1.0,0.0) [0.0|1] ""  BMS_MV,Gateway,Gateway_PAG
 SG_ DC_MV_CALID_Index_01 m0  : 8|8@1+ (1.0,0.0) [0.0|255] ""  BMS_MV,Gateway,Gateway_PAG
 SG_ DC_MV_CALID_Index_05 m1  : 8|8@1+ (1.0,0.0) [0.0|255] ""  BMS_MV,Gateway,Gateway_PAG
 SG_ DC_MV_CALID_Index_09 m2  : 8|8@1+ (1.0,0.0) [0.0|255] ""  BMS_MV,Gateway,Gateway_PAG
 SG_ DC_MV_CALID_Index_13 m3  : 8|8@1+ (1.0,0.0) [0.0|255] ""  BMS_MV,Gateway,Gateway_PAG
 SG_ DC_MV_CALID_Index_02 m0  : 16|8@1+ (1.0,0.0) [0.0|255] ""  BMS_MV,Gateway,Gateway_PAG
 SG_ DC_MV_CALID_Index_06 m1  : 16|8@1+ (1.0,0.0) [0.0|255] ""  BMS_MV,Gateway,Gateway_PAG
 SG_ DC_MV_CALID_Index_10 m2  : 16|8@1+ (1.0,0.0) [0.0|255] ""  BMS_MV,Gateway,Gateway_PAG
 SG_ DC_MV_CALID_Index_14 m3  : 16|8@1+ (1.0,0.0) [0.0|255] ""  BMS_MV,Gateway,Gateway_PAG
 SG_ DC_MV_CALID_Index_03 m0  : 24|8@1+ (1.0,0.0) [0.0|255] ""  BMS_MV,Gateway,Gateway_PAG
 SG_ DC_MV_CALID_Index_07 m1  : 24|8@1+ (1.0,0.0) [0.0|255] ""  BMS_MV,Gateway,Gateway_PAG
 SG_ DC_MV_CALID_Index_11 m2  : 24|8@1+ (1.0,0.0) [0.0|255] ""  BMS_MV,Gateway,Gateway_PAG
 SG_ DC_MV_CALID_Index_15 m3  : 24|8@1+ (1.0,0.0) [0.0|255] ""  BMS_MV,Gateway,Gateway_PAG
 SG_ DC_MV_CALID_Index_04 m0  : 32|8@1+ (1.0,0.0) [0.0|255] ""  BMS_MV,Gateway,Gateway_PAG
 SG_ DC_MV_CALID_Index_08 m1  : 32|8@1+ (1.0,0.0) [0.0|255] ""  BMS_MV,Gateway,Gateway_PAG
 SG_ DC_MV_CALID_Index_12 m2  : 32|8@1+ (1.0,0.0) [0.0|255] ""  BMS_MV,Gateway,Gateway_PAG
 SG_ DC_MV_CALID_Index_16 m3  : 32|8@1+ (1.0,0.0) [0.0|255] ""  BMS_MV,Gateway,Gateway_PAG
 SG_ DC_MV_CVN_Byte_1 m0  : 40|8@1+ (1.0,0.0) [0.0|255] ""  BMS_MV,Gateway,Gateway_PAG
 SG_ DC_MV_CVN_Byte_2 m1  : 40|8@1+ (1.0,0.0) [0.0|255] ""  BMS_MV,Gateway,Gateway_PAG
 SG_ DC_MV_CVN_Byte_3 m2  : 40|8@1+ (1.0,0.0) [0.0|255] ""  BMS_MV,Gateway,Gateway_PAG
 SG_ DC_MV_CVN_Byte_4 m3  : 40|8@1+ (1.0,0.0) [0.0|255] ""  BMS_MV,Gateway,Gateway_PAG

BO_ 2589283393 DC_MV_Komponentenfehler: 8 DCDC_IHEV
 SG_ DC_MV_Komponentenfehler_01 : 0|2@1+ (1.0,0.0) [0.0|3] ""  BMS_MV,Gateway,Gateway_PAG
 SG_ DC_MV_Komponentenfehler_02 : 2|2@1+ (1.0,0.0) [0.0|3] ""  BMS_MV,Gateway,Gateway_PAG
 SG_ DC_MV_Komponentenfehler_03 : 4|2@1+ (1.0,0.0) [0.0|3] ""  BMS_MV,Gateway,Gateway_PAG
 SG_ DC_MV_Komponentenfehler_04 : 6|2@1+ (1.0,0.0) [0.0|3] ""  BMS_MV,Gateway,Gateway_PAG
 SG_ DC_MV_Komponentenfehler_05 : 8|2@1+ (1.0,0.0) [0.0|3] ""  BMS_MV,Gateway,Gateway_PAG
 SG_ DC_MV_Komponentenfehler_06 : 10|2@1+ (1.0,0.0) [0.0|3] ""  BMS_MV,Gateway,Gateway_PAG
 SG_ DC_MV_Komponentenfehler_07 : 12|2@1+ (1.0,0.0) [0.0|3] ""  BMS_MV,Gateway,Gateway_PAG
 SG_ DC_MV_Komponentenfehler_08 : 14|2@1+ (1.0,0.0) [0.0|3] ""  BMS_MV,Gateway,Gateway_PAG
 SG_ DC_MV_Komponentenfehler_09 : 16|2@1+ (1.0,0.0) [0.0|3] ""  BMS_MV,Gateway,Gateway_PAG
 SG_ DC_MV_Komponentenfehler_10 : 18|2@1+ (1.0,0.0) [0.0|3] ""  BMS_MV,Gateway,Gateway_PAG
 SG_ DC_MV_Komponentenfehler_11 : 20|2@1+ (1.0,0.0) [0.0|3] ""  BMS_MV,Gateway,Gateway_PAG
 SG_ DC_MV_Komponentenfehler_12 : 22|2@1+ (1.0,0.0) [0.0|3] ""  BMS_MV,Gateway,Gateway_PAG
 SG_ DC_MV_Komponentenfehler_13 : 24|2@1+ (1.0,0.0) [0.0|3] ""  BMS_MV,Gateway,Gateway_PAG
 SG_ DC_MV_Komponentenfehler_14 : 26|2@1+ (1.0,0.0) [0.0|3] ""  BMS_MV,Gateway,Gateway_PAG
 SG_ DC_MV_Komponentenfehler_15 : 28|2@1+ (1.0,0.0) [0.0|3] ""  BMS_MV,Gateway,Gateway_PAG
 SG_ DC_MV_Komponentenfehler_16 : 30|2@1+ (1.0,0.0) [0.0|3] ""  BMS_MV,Gateway,Gateway_PAG
 SG_ DC_MV_Komponentenfehler_17 : 32|2@1+ (1.0,0.0) [0.0|3] ""  BMS_MV,Gateway,Gateway_PAG
 SG_ DC_MV_Komponentenfehler_18 : 34|2@1+ (1.0,0.0) [0.0|3] ""  BMS_MV,Gateway,Gateway_PAG
 SG_ DC_MV_Komponentenfehler_19 : 36|2@1+ (1.0,0.0) [0.0|3] ""  BMS_MV,Gateway,Gateway_PAG
 SG_ DC_MV_Komponentenfehler_20 : 38|2@1+ (1.0,0.0) [0.0|3] ""  BMS_MV,Gateway,Gateway_PAG
 SG_ DC_MV_Komponentenfehler_21 : 40|2@1+ (1.0,0.0) [0.0|3] ""  BMS_MV,Gateway,Gateway_PAG
 SG_ DC_MV_Komponentenfehler_22 : 42|2@1+ (1.0,0.0) [0.0|3] ""  BMS_MV,Gateway,Gateway_PAG
 SG_ DC_MV_Komponentenfehler_23 : 44|2@1+ (1.0,0.0) [0.0|3] ""  BMS_MV,Gateway,Gateway_PAG
 SG_ DC_MV_Komponentenfehler_24 : 46|2@1+ (1.0,0.0) [0.0|3] ""  BMS_MV,Gateway,Gateway_PAG
 SG_ DC_MV_Komponentenfehler_25 : 48|2@1+ (1.0,0.0) [0.0|3] ""  BMS_MV,Gateway,Gateway_PAG
 SG_ DC_MV_Komponentenfehler_26 : 50|2@1+ (1.0,0.0) [0.0|3] ""  BMS_MV,Gateway,Gateway_PAG
 SG_ DC_MV_Komponentenfehler_27 : 52|2@1+ (1.0,0.0) [0.0|3] ""  BMS_MV,Gateway,Gateway_PAG
 SG_ DC_MV_Komponentenfehler_28 : 54|2@1+ (1.0,0.0) [0.0|3] ""  BMS_MV,Gateway,Gateway_PAG
 SG_ DC_MV_Komponentenfehler_29 : 56|2@1+ (1.0,0.0) [0.0|3] ""  BMS_MV,Gateway,Gateway_PAG
 SG_ DC_MV_Komponentenfehler_30 : 58|2@1+ (1.0,0.0) [0.0|3] ""  BMS_MV,Gateway,Gateway_PAG
 SG_ DC_MV_Komponentenfehler_31 : 60|2@1+ (1.0,0.0) [0.0|3] ""  BMS_MV,Gateway,Gateway_PAG
 SG_ DC_MV_Komponentenfehler_VLD : 63|1@1+ (1.0,0.0) [0.0|1] ""  BMS_MV,Gateway,Gateway_PAG

BO_ 2589283855 DC_MV_Komponentenfehler_02: 8 DCDC_IHEV
 SG_ DC_MV_Komponentenfehler_32 : 0|2@1+ (1.0,0.0) [0.0|3] ""  BMS_MV
 SG_ DC_MV_Komponentenfehler_33 : 2|2@1+ (1.0,0.0) [0.0|3] ""  BMS_MV
 SG_ DC_MV_Komponentenfehler_34 : 4|2@1+ (1.0,0.0) [0.0|3] ""  BMS_MV
 SG_ DC_MV_Komponentenfehler_35 : 6|2@1+ (1.0,0.0) [0.0|3] ""  BMS_MV
 SG_ DC_MV_Komponentenfehler_36 : 8|2@1+ (1.0,0.0) [0.0|3] ""  BMS_MV
 SG_ DC_MV_Komponentenfehler_37 : 10|2@1+ (1.0,0.0) [0.0|3] ""  BMS_MV
 SG_ DC_MV_Komponentenfehler_38 : 12|2@1+ (1.0,0.0) [0.0|3] ""  BMS_MV
 SG_ DC_MV_Komponentenfehler_39 : 14|2@1+ (1.0,0.0) [0.0|3] ""  BMS_MV
 SG_ DC_MV_Komponentenfehler_40 : 16|2@1+ (1.0,0.0) [0.0|3] ""  BMS_MV
 SG_ DC_MV_Komponentenfehler_41 : 18|2@1+ (1.0,0.0) [0.0|3] ""  BMS_MV
 SG_ DC_MV_Komponentenfehler_42 : 20|2@1+ (1.0,0.0) [0.0|3] ""  BMS_MV
 SG_ DC_MV_Komponentenfehler_43 : 22|2@1+ (1.0,0.0) [0.0|3] ""  BMS_MV
 SG_ DC_MV_Komponentenfehler_44 : 24|2@1+ (1.0,0.0) [0.0|3] ""  BMS_MV
 SG_ DC_MV_Komponentenfehler_45 : 26|2@1+ (1.0,0.0) [0.0|3] ""  BMS_MV
 SG_ DC_MV_Komponentenfehler_46 : 28|2@1+ (1.0,0.0) [0.0|3] ""  BMS_MV
 SG_ DC_MV_Komponentenfehler_47 : 30|2@1+ (1.0,0.0) [0.0|3] ""  BMS_MV
 SG_ DC_MV_Komponentenfehler_48 : 32|2@1+ (1.0,0.0) [0.0|3] ""  BMS_MV
 SG_ DC_MV_Komponentenfehler_49 : 34|2@1+ (1.0,0.0) [0.0|3] ""  BMS_MV
 SG_ DC_MV_Komponentenfehler_50 : 36|2@1+ (1.0,0.0) [0.0|3] ""  BMS_MV
 SG_ DC_MV_Komponentenfehler_51 : 38|2@1+ (1.0,0.0) [0.0|3] ""  BMS_MV
 SG_ DC_MV_Komponentenfehler_52 : 40|2@1+ (1.0,0.0) [0.0|3] ""  BMS_MV
 SG_ DC_MV_Komponentenfehler_53 : 42|2@1+ (1.0,0.0) [0.0|3] ""  BMS_MV
 SG_ DC_MV_Komponentenfehler_54 : 44|2@1+ (1.0,0.0) [0.0|3] ""  BMS_MV
 SG_ DC_MV_Komponentenfehler_55 : 46|2@1+ (1.0,0.0) [0.0|3] ""  BMS_MV
 SG_ DC_MV_Komponentenfehler_56 : 48|2@1+ (1.0,0.0) [0.0|3] ""  BMS_MV
 SG_ DC_MV_Komponentenfehler_57 : 50|2@1+ (1.0,0.0) [0.0|3] ""  BMS_MV
 SG_ DC_MV_Komponentenfehler_58 : 52|2@1+ (1.0,0.0) [0.0|3] ""  BMS_MV
 SG_ DC_MV_Komponentenfehler_59 : 54|2@1+ (1.0,0.0) [0.0|3] ""  BMS_MV
 SG_ DC_MV_Komponentenfehler_60 : 56|2@1+ (1.0,0.0) [0.0|3] ""  BMS_MV
 SG_ DC_MV_Komponentenfehler_61 : 58|2@1+ (1.0,0.0) [0.0|3] ""  BMS_MV
 SG_ DC_MV_Komponentenfehler_62 : 60|2@1+ (1.0,0.0) [0.0|3] ""  BMS_MV

BO_ 2589283856 DC_MV_Komponentenfehler_03: 8 DCDC_IHEV
 SG_ DC_MV_Komponentenfehler_63 : 0|2@1+ (1.0,0.0) [0.0|3] ""  BMS_MV
 SG_ DC_MV_Komponentenfehler_64 : 2|2@1+ (1.0,0.0) [0.0|3] ""  BMS_MV
 SG_ DC_MV_Komponentenfehler_65 : 4|2@1+ (1.0,0.0) [0.0|3] ""  BMS_MV
 SG_ DC_MV_Komponentenfehler_66 : 6|2@1+ (1.0,0.0) [0.0|3] ""  BMS_MV
 SG_ DC_MV_Komponentenfehler_67 : 8|2@1+ (1.0,0.0) [0.0|3] ""  BMS_MV
 SG_ DC_MV_Komponentenfehler_68 : 10|2@1+ (1.0,0.0) [0.0|3] ""  BMS_MV
 SG_ DC_MV_Komponentenfehler_69 : 12|2@1+ (1.0,0.0) [0.0|3] ""  BMS_MV
 SG_ DC_MV_Komponentenfehler_70 : 14|2@1+ (1.0,0.0) [0.0|3] ""  BMS_MV
 SG_ DC_MV_Komponentenfehler_71 : 16|2@1+ (1.0,0.0) [0.0|3] ""  BMS_MV
 SG_ DC_MV_Komponentenfehler_72 : 18|2@1+ (1.0,0.0) [0.0|3] ""  BMS_MV
 SG_ DC_MV_Komponentenfehler_73 : 20|2@1+ (1.0,0.0) [0.0|3] ""  BMS_MV
 SG_ DC_MV_Komponentenfehler_74 : 22|2@1+ (1.0,0.0) [0.0|3] ""  BMS_MV
 SG_ DC_MV_Komponentenfehler_75 : 24|2@1+ (1.0,0.0) [0.0|3] ""  BMS_MV
 SG_ DC_MV_Komponentenfehler_76 : 26|2@1+ (1.0,0.0) [0.0|3] ""  BMS_MV
 SG_ DC_MV_Komponentenfehler_77 : 28|2@1+ (1.0,0.0) [0.0|3] ""  BMS_MV
 SG_ DC_MV_Komponentenfehler_78 : 30|2@1+ (1.0,0.0) [0.0|3] ""  BMS_MV
 SG_ DC_MV_Komponentenfehler_79 : 32|2@1+ (1.0,0.0) [0.0|3] ""  BMS_MV
 SG_ DC_MV_Komponentenfehler_80 : 34|2@1+ (1.0,0.0) [0.0|3] ""  BMS_MV
 SG_ DC_MV_Komponentenfehler_81 : 36|2@1+ (1.0,0.0) [0.0|3] ""  BMS_MV
 SG_ DC_MV_Komponentenfehler_82 : 38|2@1+ (1.0,0.0) [0.0|3] ""  BMS_MV
 SG_ DC_MV_Komponentenfehler_83 : 40|2@1+ (1.0,0.0) [0.0|3] ""  BMS_MV
 SG_ DC_MV_Komponentenfehler_84 : 42|2@1+ (1.0,0.0) [0.0|3] ""  BMS_MV
 SG_ DC_MV_Komponentenfehler_85 : 44|2@1+ (1.0,0.0) [0.0|3] ""  BMS_MV
 SG_ DC_MV_Komponentenfehler_86 : 46|2@1+ (1.0,0.0) [0.0|3] ""  BMS_MV
 SG_ DC_MV_Komponentenfehler_87 : 48|2@1+ (1.0,0.0) [0.0|3] ""  BMS_MV
 SG_ DC_MV_Komponentenfehler_88 : 50|2@1+ (1.0,0.0) [0.0|3] ""  BMS_MV
 SG_ DC_MV_Komponentenfehler_89 : 52|2@1+ (1.0,0.0) [0.0|3] ""  BMS_MV
 SG_ DC_MV_Komponentenfehler_90 : 54|2@1+ (1.0,0.0) [0.0|3] ""  BMS_MV
 SG_ DC_MV_Komponentenfehler_91 : 56|2@1+ (1.0,0.0) [0.0|3] ""  BMS_MV
 SG_ DC_MV_Komponentenfehler_92 : 58|2@1+ (1.0,0.0) [0.0|3] ""  BMS_MV
 SG_ DC_MV_Komponentenfehler_93 : 60|2@1+ (1.0,0.0) [0.0|3] ""  BMS_MV

BO_ 2589283857 DC_MV_Komponentenfehler_04: 8 DCDC_IHEV
 SG_ DC_MV_Komponentenfehler_94 : 0|2@1+ (1.0,0.0) [0.0|3] ""  BMS_MV
 SG_ DC_MV_Komponentenfehler_95 : 2|2@1+ (1.0,0.0) [0.0|3] ""  BMS_MV
 SG_ DC_MV_Komponentenfehler_96 : 4|2@1+ (1.0,0.0) [0.0|3] ""  BMS_MV
 SG_ DC_MV_Komponentenfehler_97 : 6|2@1+ (1.0,0.0) [0.0|3] ""  BMS_MV
 SG_ DC_MV_Komponentenfehler_98 : 8|2@1+ (1.0,0.0) [0.0|3] ""  BMS_MV
 SG_ DC_MV_Komponentenfehler_99 : 10|2@1+ (1.0,0.0) [0.0|3] ""  BMS_MV
 SG_ DC_MV_Komponentenfehler_100 : 12|2@1+ (1.0,0.0) [0.0|3] ""  BMS_MV
 SG_ DC_MV_Komponentenfehler_101 : 14|2@1+ (1.0,0.0) [0.0|3] ""  BMS_MV
 SG_ DC_MV_Komponentenfehler_102 : 16|2@1+ (1.0,0.0) [0.0|3] ""  BMS_MV
 SG_ DC_MV_Komponentenfehler_103 : 18|2@1+ (1.0,0.0) [0.0|3] ""  BMS_MV
 SG_ DC_MV_Komponentenfehler_104 : 20|2@1+ (1.0,0.0) [0.0|3] ""  BMS_MV
 SG_ DC_MV_Komponentenfehler_105 : 22|2@1+ (1.0,0.0) [0.0|3] ""  BMS_MV
 SG_ DC_MV_Komponentenfehler_106 : 24|2@1+ (1.0,0.0) [0.0|3] ""  BMS_MV
 SG_ DC_MV_Komponentenfehler_107 : 26|2@1+ (1.0,0.0) [0.0|3] ""  BMS_MV
 SG_ DC_MV_Komponentenfehler_108 : 28|2@1+ (1.0,0.0) [0.0|3] ""  BMS_MV
 SG_ DC_MV_Komponentenfehler_109 : 30|2@1+ (1.0,0.0) [0.0|3] ""  BMS_MV
 SG_ DC_MV_Komponentenfehler_110 : 32|2@1+ (1.0,0.0) [0.0|3] ""  BMS_MV
 SG_ DC_MV_Komponentenfehler_111 : 34|2@1+ (1.0,0.0) [0.0|3] ""  BMS_MV
 SG_ DC_MV_Komponentenfehler_112 : 36|2@1+ (1.0,0.0) [0.0|3] ""  BMS_MV
 SG_ DC_MV_Komponentenfehler_113 : 38|2@1+ (1.0,0.0) [0.0|3] ""  BMS_MV
 SG_ DC_MV_Komponentenfehler_114 : 40|2@1+ (1.0,0.0) [0.0|3] ""  BMS_MV
 SG_ DC_MV_Komponentenfehler_115 : 42|2@1+ (1.0,0.0) [0.0|3] ""  BMS_MV
 SG_ DC_MV_Komponentenfehler_116 : 44|2@1+ (1.0,0.0) [0.0|3] ""  BMS_MV
 SG_ DC_MV_Komponentenfehler_117 : 46|2@1+ (1.0,0.0) [0.0|3] ""  BMS_MV
 SG_ DC_MV_Komponentenfehler_118 : 48|2@1+ (1.0,0.0) [0.0|3] ""  BMS_MV
 SG_ DC_MV_Komponentenfehler_119 : 50|2@1+ (1.0,0.0) [0.0|3] ""  BMS_MV
 SG_ DC_MV_Komponentenfehler_120 : 52|2@1+ (1.0,0.0) [0.0|3] ""  BMS_MV
 SG_ DC_MV_Komponentenfehler_121 : 54|2@1+ (1.0,0.0) [0.0|3] ""  BMS_MV
 SG_ DC_MV_Komponentenfehler_122 : 56|2@1+ (1.0,0.0) [0.0|3] ""  BMS_MV
 SG_ DC_MV_Komponentenfehler_123 : 58|2@1+ (1.0,0.0) [0.0|3] ""  BMS_MV
 SG_ DC_MV_Komponentenfehler_124 : 60|2@1+ (1.0,0.0) [0.0|3] ""  BMS_MV

BO_ 2589283858 DC_MV_Komponentenfehler_05: 8 DCDC_IHEV
 SG_ DC_MV_Komponentenfehler_125 : 0|2@1+ (1.0,0.0) [0.0|3] ""  BMS_MV
 SG_ DC_MV_Komponentenfehler_126 : 2|2@1+ (1.0,0.0) [0.0|3] ""  BMS_MV
 SG_ DC_MV_Komponentenfehler_127 : 4|2@1+ (1.0,0.0) [0.0|3] ""  BMS_MV
 SG_ DC_MV_Komponentenfehler_128 : 6|2@1+ (1.0,0.0) [0.0|3] ""  BMS_MV
 SG_ DC_MV_Komponentenfehler_129 : 8|2@1+ (1.0,0.0) [0.0|3] ""  BMS_MV
 SG_ DC_MV_Komponentenfehler_130 : 10|2@1+ (1.0,0.0) [0.0|3] ""  BMS_MV
 SG_ DC_MV_Komponentenfehler_131 : 12|2@1+ (1.0,0.0) [0.0|3] ""  BMS_MV
 SG_ DC_MV_Komponentenfehler_132 : 14|2@1+ (1.0,0.0) [0.0|3] ""  BMS_MV
 SG_ DC_MV_Komponentenfehler_133 : 16|2@1+ (1.0,0.0) [0.0|3] ""  BMS_MV
 SG_ DC_MV_Komponentenfehler_134 : 18|2@1+ (1.0,0.0) [0.0|3] ""  BMS_MV
 SG_ DC_MV_Komponentenfehler_135 : 20|2@1+ (1.0,0.0) [0.0|3] ""  BMS_MV
 SG_ DC_MV_Komponentenfehler_136 : 22|2@1+ (1.0,0.0) [0.0|3] ""  BMS_MV
 SG_ DC_MV_Komponentenfehler_137 : 24|2@1+ (1.0,0.0) [0.0|3] ""  BMS_MV
 SG_ DC_MV_Komponentenfehler_138 : 26|2@1+ (1.0,0.0) [0.0|3] ""  BMS_MV
 SG_ DC_MV_Komponentenfehler_139 : 28|2@1+ (1.0,0.0) [0.0|3] ""  BMS_MV
 SG_ DC_MV_Komponentenfehler_140 : 30|2@1+ (1.0,0.0) [0.0|3] ""  BMS_MV
 SG_ DC_MV_Komponentenfehler_141 : 32|2@1+ (1.0,0.0) [0.0|3] ""  BMS_MV
 SG_ DC_MV_Komponentenfehler_142 : 34|2@1+ (1.0,0.0) [0.0|3] ""  BMS_MV
 SG_ DC_MV_Komponentenfehler_143 : 36|2@1+ (1.0,0.0) [0.0|3] ""  BMS_MV
 SG_ DC_MV_Komponentenfehler_144 : 38|2@1+ (1.0,0.0) [0.0|3] ""  BMS_MV
 SG_ DC_MV_Komponentenfehler_145 : 40|2@1+ (1.0,0.0) [0.0|3] ""  BMS_MV

BO_TX_BU_ 179 :Gateway,Gateway_PAG;
BO_TX_BU_ 901 :Gateway,Gateway_PAG;
BO_TX_BU_ 1022 :Gateway,Gateway_PAG;

CM_ BO_ 179 "Schnittstelle EBKV - Motor";
CM_ BO_ 901 "ab MQB ohne CHK und mit geänderter Sendeart";

CM_ SG_ 881 BMS_CMC_02_MUX "Multiplexer der Botschaft BMS_CMC_02 zur Übertragung der Zellspannungen für RTM";
CM_ SG_ 881 BMS_CMC_Zellspannung_081 "Einzelzellspannung zur Übertragung per RTM";
CM_ SG_ 881 BMS_CMC_Zellspannung_082 "Einzelzellspannung zur Übertragung per RTM";
CM_ SG_ 881 BMS_CMC_Zellspannung_083 "Einzelzellspannung zur Übertragung per RTM";
CM_ SG_ 881 BMS_CMC_Zellspannung_084 "Einzelzellspannung zur Übertragung per RTM";
CM_ SG_ 881 BMS_CMC_Zellspannung_085 "Einzelzellspannung zur Übertragung per RTM";
CM_ SG_ 881 BMS_CMC_Zellspannung_086 "Einzelzellspannung zur Übertragung per RTM";
CM_ SG_ 881 BMS_CMC_Zellspannung_087 "Einzelzellspannung zur Übertragung per RTM";
CM_ SG_ 881 BMS_CMC_Zellspannung_088 "Einzelzellspannung zur Übertragung per RTM";
CM_ SG_ 881 BMS_CMC_Zellspannung_089 "Einzelzellspannung zur Übertragung per RTM";
CM_ SG_ 881 BMS_CMC_Zellspannung_090 "Einzelzellspannung zur Übertragung per RTM";
CM_ SG_ 881 BMS_CMC_Zellspannung_091 "Einzelzellspannung zur Übertragung per RTM";
CM_ SG_ 881 BMS_CMC_Zellspannung_092 "Einzelzellspannung zur Übertragung per RTM";
CM_ SG_ 881 BMS_CMC_Zellspannung_093 "Einzelzellspannung zur Übertragung per RTM";
CM_ SG_ 881 BMS_CMC_Zellspannung_094 "Einzelzellspannung zur Übertragung per RTM";
CM_ SG_ 881 BMS_CMC_Zellspannung_095 "Einzelzellspannung zur Übertragung per RTM";
CM_ SG_ 881 BMS_CMC_Zellspannung_096 "Einzelzellspannung zur Übertragung per RTM";
CM_ SG_ 881 BMS_CMC_Zellspannung_097 "Einzelzellspannung zur Übertragung per RTM";
CM_ SG_ 881 BMS_CMC_Zellspannung_098 "Einzelzellspannung zur Übertragung per RTM";
CM_ SG_ 881 BMS_CMC_Zellspannung_099 "Einzelzellspannung zur Übertragung per RTM";
CM_ SG_ 881 BMS_CMC_Zellspannung_100 "Einzelzellspannung zur Übertragung per RTM";
CM_ SG_ 881 BMS_CMC_Zellspannung_101 "Einzelzellspannung zur Übertragung per RTM";
CM_ SG_ 881 BMS_CMC_Zellspannung_102 "Einzelzellspannung zur Übertragung per RTM";
CM_ SG_ 881 BMS_CMC_Zellspannung_103 "Einzelzellspannung zur Übertragung per RTM";
CM_ SG_ 881 BMS_CMC_Zellspannung_104 "Einzelzellspannung zur Übertragung per RTM";
CM_ SG_ 881 BMS_CMC_Zellspannung_105 "Einzelzellspannung zur Übertragung per RTM";
CM_ SG_ 881 BMS_CMC_Zellspannung_106 "Einzelzellspannung zur Übertragung per RTM";
CM_ SG_ 881 BMS_CMC_Zellspannung_107 "Einzelzellspannung zur Übertragung per RTM";
CM_ SG_ 881 BMS_CMC_Zellspannung_108 "Einzelzellspannung zur Übertragung per RTM";
CM_ SG_ 881 BMS_CMC_Zellspannung_109 "Einzelzellspannung zur Übertragung per RTM";
CM_ SG_ 881 BMS_CMC_Zellspannung_110 "Einzelzellspannung zur Übertragung per RTM";
CM_ SG_ 881 BMS_CMC_Zellspannung_111 "Einzelzellspannung zur Übertragung per RTM";
CM_ SG_ 881 BMS_CMC_Zellspannung_112 "Einzelzellspannung zur Übertragung per RTM";
CM_ SG_ 881 BMS_CMC_Zellspannung_113 "Einzelzellspannung zur Übertragung per RTM";
CM_ SG_ 881 BMS_CMC_Zellspannung_114 "Einzelzellspannung zur Übertragung per RTM";
CM_ SG_ 881 BMS_CMC_Zellspannung_115 "Einzelzellspannung zur Übertragung per RTM";
CM_ SG_ 881 BMS_CMC_Zellspannung_116 "Einzelzellspannung zur Übertragung per RTM";
CM_ SG_ 881 BMS_CMC_Zellspannung_117 "Einzelzellspannung zur Übertragung per RTM";
CM_ SG_ 881 BMS_CMC_Zellspannung_118 "Einzelzellspannung zur Übertragung per RTM";
CM_ SG_ 881 BMS_CMC_Zellspannung_119 "Einzelzellspannung zur Übertragung per RTM";
CM_ SG_ 881 BMS_CMC_Zellspannung_120 "Einzelzellspannung zur Übertragung per RTM";
CM_ SG_ 881 BMS_CMC_Zellspannung_121 "Einzelzellspannung zur Übertragung per RTM";
CM_ SG_ 881 BMS_CMC_Zellspannung_122 "Einzelzellspannung zur Übertragung per RTM";
CM_ SG_ 881 BMS_CMC_Zellspannung_123 "Einzelzellspannung zur Übertragung per RTM";
CM_ SG_ 881 BMS_CMC_Zellspannung_124 "Einzelzellspannung zur Übertragung per RTM";
CM_ SG_ 881 BMS_CMC_Zellspannung_125 "Einzelzellspannung zur Übertragung per RTM";
CM_ SG_ 881 BMS_CMC_Zellspannung_126 "Einzelzellspannung zur Übertragung per RTM";
CM_ SG_ 881 BMS_CMC_Zellspannung_127 "Einzelzellspannung zur Übertragung per RTM";
CM_ SG_ 881 BMS_CMC_Zellspannung_128 "Einzelzellspannung zur Übertragung per RTM";
CM_ SG_ 881 BMS_CMC_Zellspannung_129 "Einzelzellspannung zur Übertragung per RTM";
CM_ SG_ 881 BMS_CMC_Zellspannung_130 "Einzelzellspannung zur Übertragung per RTM";
CM_ SG_ 881 BMS_CMC_Zellspannung_131 "Einzelzellspannung zur Übertragung per RTM";
CM_ SG_ 881 BMS_CMC_Zellspannung_132 "Einzelzellspannung zur Übertragung per RTM";
CM_ SG_ 881 BMS_CMC_Zellspannung_133 "Einzelzellspannung zur Übertragung per RTM";
CM_ SG_ 881 BMS_CMC_Zellspannung_134 "Einzelzellspannung zur Übertragung per RTM";
CM_ SG_ 881 BMS_CMC_Zellspannung_135 "Einzelzellspannung zur Übertragung per RTM";
CM_ SG_ 881 BMS_CMC_Zellspannung_136 "Einzelzellspannung zur Übertragung per RTM";
CM_ SG_ 881 BMS_CMC_Zellspannung_137 "Einzelzellspannung zur Übertragung per RTM";
CM_ SG_ 881 BMS_CMC_Zellspannung_138 "Einzelzellspannung zur Übertragung per RTM";
CM_ SG_ 881 BMS_CMC_Zellspannung_139 "Einzelzellspannung zur Übertragung per RTM";
CM_ SG_ 881 BMS_CMC_Zellspannung_140 "Einzelzellspannung zur Übertragung per RTM";
CM_ SG_ 881 BMS_CMC_Zellspannung_141 "Einzelzellspannung zur Übertragung per RTM";
CM_ SG_ 881 BMS_CMC_Zellspannung_142 "Einzelzellspannung zur Übertragung per RTM";
CM_ SG_ 881 BMS_CMC_Zellspannung_143 "Einzelzellspannung zur Übertragung per RTM";
CM_ SG_ 881 BMS_CMC_Zellspannung_144 "Einzelzellspannung zur Übertragung per RTM";
CM_ SG_ 881 BMS_CMC_Zellspannung_145 "Einzelzellspannung zur Übertragung per RTM";
CM_ SG_ 881 BMS_CMC_Zellspannung_146 "Einzelzellspannung zur Übertragung per RTM";
CM_ SG_ 881 BMS_CMC_Zellspannung_147 "Einzelzellspannung zur Übertragung per RTM";
CM_ SG_ 881 BMS_CMC_Zellspannung_148 "Einzelzellspannung zur Übertragung per RTM";
CM_ SG_ 881 BMS_CMC_Zellspannung_149 "Einzelzellspannung zur Übertragung per RTM";
CM_ SG_ 881 BMS_CMC_Zellspannung_150 "Einzelzellspannung zur Übertragung per RTM";
CM_ SG_ 881 BMS_CMC_Zellspannung_151 "Einzelzellspannung zur Übertragung per RTM";
CM_ SG_ 881 BMS_CMC_Zellspannung_152 "Einzelzellspannung zur Übertragung per RTM";
CM_ SG_ 881 BMS_CMC_Zellspannung_153 "Einzelzellspannung zur Übertragung per RTM";
CM_ SG_ 881 BMS_CMC_Zellspannung_154 "Einzelzellspannung zur Übertragung per RTM";
CM_ SG_ 881 BMS_CMC_Zellspannung_155 "Einzelzellspannung zur Übertragung per RTM";
CM_ SG_ 881 BMS_CMC_Zellspannung_156 "Einzelzellspannung zur Übertragung per RTM";
CM_ SG_ 881 BMS_CMC_Zellspannung_157 "Einzelzellspannung zur Übertragung per RTM";
CM_ SG_ 881 BMS_CMC_Zellspannung_158 "Einzelzellspannung zur Übertragung per RTM";
CM_ SG_ 881 BMS_CMC_Zellspannung_159 "Einzelzellspannung zur Übertragung per RTM";
CM_ SG_ 881 BMS_CMC_Zellspannung_160 "Einzelzellspannung zur Übertragung per RTM";

CM_ SG_ 2463978713 BMS_CMC_03_MUX "Multiplexer der Botschaft BMS_CMC_03 zur Übertragung der Zelltemperaturen für RTM";
CM_ SG_ 2463978713 BMS_CMC_Temperatur_001 "Temperatur Zellmodul für die Übertragung per RTM";
CM_ SG_ 2463978713 BMS_CMC_Temperatur_002 "Temperatur Zellmodul für die Übertragung per RTM";
CM_ SG_ 2463978713 BMS_CMC_Temperatur_003 "Temperatur Zellmodul für die Übertragung per RTM";
CM_ SG_ 2463978713 BMS_CMC_Temperatur_004 "Temperatur Zellmodul für die Übertragung per RTM";
CM_ SG_ 2463978713 BMS_CMC_Temperatur_005 "Temperatur Zellmodul für die Übertragung per RTM";
CM_ SG_ 2463978713 BMS_CMC_Temperatur_006 "Temperatur Zellmodul für die Übertragung per RTM";
CM_ SG_ 2463978713 BMS_CMC_Temperatur_007 "Temperatur Zellmodul für die Übertragung per RTM";
CM_ SG_ 2463978713 BMS_CMC_Temperatur_008 "Temperatur Zellmodul für die Übertragung per RTM";
CM_ SG_ 2463978713 BMS_CMC_Temperatur_009 "Temperatur Zellmodul für die Übertragung per RTM";
CM_ SG_ 2463978713 BMS_CMC_Temperatur_010 "Temperatur Zellmodul für die Übertragung per RTM";
CM_ SG_ 2463978713 BMS_CMC_Temperatur_011 "Temperatur Zellmodul für die Übertragung per RTM";
CM_ SG_ 2463978713 BMS_CMC_Temperatur_012 "Temperatur Zellmodul für die Übertragung per RTM";
CM_ SG_ 2463978713 BMS_CMC_Temperatur_013 "Temperatur Zellmodul für die Übertragung per RTM";
CM_ SG_ 2463978713 BMS_CMC_Temperatur_014 "Temperatur Zellmodul für die Übertragung per RTM";
CM_ SG_ 2463978713 BMS_CMC_Temperatur_015 "Temperatur Zellmodul für die Übertragung per RTM";
CM_ SG_ 2463978713 BMS_CMC_Temperatur_016 "Temperatur Zellmodul für die Übertragung per RTM";
CM_ SG_ 2463978713 BMS_CMC_Temperatur_017 "Temperatur Zellmodul für die Übertragung per RTM";
CM_ SG_ 2463978713 BMS_CMC_Temperatur_018 "Temperatur Zellmodul für die Übertragung per RTM";
CM_ SG_ 2463978713 BMS_CMC_Temperatur_019 "Temperatur Zellmodul für die Übertragung per RTM";
CM_ SG_ 2463978713 BMS_CMC_Temperatur_020 "Temperatur Zellmodul für die Übertragung per RTM";
CM_ SG_ 2463978713 BMS_CMC_Temperatur_021 "Temperatur Zellmodul für die Übertragung per RTM";
CM_ SG_ 2463978713 BMS_CMC_Temperatur_022 "Temperatur Zellmodul für die Übertragung per RTM";
CM_ SG_ 2463978713 BMS_CMC_Temperatur_023 "Temperatur Zellmodul für die Übertragung per RTM";
CM_ SG_ 2463978713 BMS_CMC_Temperatur_024 "Temperatur Zellmodul für die Übertragung per RTM";
CM_ SG_ 2463978713 BMS_CMC_Temperatur_025 "Temperatur Zellmodul für die Übertragung per RTM";
CM_ SG_ 2463978713 BMS_CMC_Temperatur_026 "Temperatur Zellmodul für die Übertragung per RTM";
CM_ SG_ 2463978713 BMS_CMC_Temperatur_027 "Temperatur Zellmodul für die Übertragung per RTM";
CM_ SG_ 2463978713 BMS_CMC_Temperatur_028 "Temperatur Zellmodul für die Übertragung per RTM";
CM_ SG_ 2463978713 BMS_CMC_Temperatur_029 "Temperatur Zellmodul für die Übertragung per RTM";
CM_ SG_ 2463978713 BMS_CMC_Temperatur_030 "Temperatur Zellmodul für die Übertragung per RTM";
CM_ SG_ 2463978713 BMS_CMC_Temperatur_031 "Temperatur Zellmodul für die Übertragung per RTM";
CM_ SG_ 2463978713 BMS_CMC_Temperatur_032 "Temperatur Zellmodul für die Übertragung per RTM";
CM_ SG_ 2463978713 BMS_CMC_Temperatur_033 "Temperatur Zellmodul für die Übertragung per RTM";
CM_ SG_ 2463978713 BMS_CMC_Temperatur_034 "Temperatur Zellmodul für die Übertragung per RTM";
CM_ SG_ 2463978713 BMS_CMC_Temperatur_035 "Temperatur Zellmodul für die Übertragung per RTM";
CM_ SG_ 2463978713 BMS_CMC_Temperatur_036 "Temperatur Zellmodul für die Übertragung per RTM";
CM_ SG_ 2463978713 BMS_CMC_Temperatur_037 "Temperatur Zellmodul für die Übertragung per RTM";
CM_ SG_ 2463978713 BMS_CMC_Temperatur_038 "Temperatur Zellmodul für die Übertragung per RTM";
CM_ SG_ 2463978713 BMS_CMC_Temperatur_039 "Temperatur Zellmodul für die Übertragung per RTM";
CM_ SG_ 2463978713 BMS_CMC_Temperatur_040 "Temperatur Zellmodul für die Übertragung per RTM";
CM_ SG_ 2463978713 BMS_CMC_Temperatur_041 "Temperatur Zellmodul für die Übertragung per RTM";
CM_ SG_ 2463978713 BMS_CMC_Temperatur_042 "Temperatur Zellmodul für die Übertragung per RTM";
CM_ SG_ 2463978713 BMS_CMC_Temperatur_043 "Temperatur Zellmodul für die Übertragung per RTM";
CM_ SG_ 2463978713 BMS_CMC_Temperatur_044 "Temperatur Zellmodul für die Übertragung per RTM";
CM_ SG_ 2463978713 BMS_CMC_Temperatur_045 "Temperatur Zellmodul für die Übertragung per RTM";
CM_ SG_ 2463978713 BMS_CMC_Temperatur_046 "Temperatur Zellmodul für die Übertragung per RTM";
CM_ SG_ 2463978713 BMS_CMC_Temperatur_047 "Temperatur Zellmodul für die Übertragung per RTM";
CM_ SG_ 2463978713 BMS_CMC_Temperatur_048 "Temperatur Zellmodul für die Übertragung per RTM";
CM_ SG_ 2463978713 BMS_CMC_Temperatur_049 "Temperatur Zellmodul für die Übertragung per RTM";
CM_ SG_ 2463978713 BMS_CMC_Temperatur_050 "Temperatur Zellmodul für die Übertragung per RTM";
CM_ SG_ 2463978713 BMS_CMC_Temperatur_051 "Temperatur Zellmodul für die Übertragung per RTM";
CM_ SG_ 2463978713 BMS_CMC_Temperatur_052 "Temperatur Zellmodul für die Übertragung per RTM";
CM_ SG_ 2463978713 BMS_CMC_Temperatur_053 "Temperatur Zellmodul für die Übertragung per RTM";
CM_ SG_ 2463978713 BMS_CMC_Temperatur_054 "Temperatur Zellmodul für die Übertragung per RTM";
CM_ SG_ 2463978713 BMS_CMC_Temperatur_055 "Temperatur Zellmodul für die Übertragung per RTM";
CM_ SG_ 2463978713 BMS_CMC_Temperatur_056 "Temperatur Zellmodul für die Übertragung per RTM";

CM_ SG_ 1400 BMS_DC_01_CRC "Für MLB:
'Berechnung siehe Lastenheft 'Kommunikationsabsicherung für FlexRay und CAN''

Ab MQB und MLBevo:
'Berechnung siehe Lastenheft 'End-to-End Kommunikationsabsicherung''

Endwerte siehe Begleitdokument 'S-PDU Kennungsfolgen'";
CM_ SG_ 1400 BMS_DCLS_MaxLadeStrom "maximaler zulässiger DC-Ladestrom";
CM_ SG_ 1400 BMS_DCLS_Spannung "DC-Spannung der Ladesäule.
Messung zwischen den DC HV-Leitungen.";
CM_ SG_ 1400 BMS_Status_DCLS "Status der Spannungsüberwachung an der DC-Ladeschnittstelle";

CM_ SG_ 397 BMS_MV_01_BZ "4bit Botschaftszähler, wird mit jeder Sendebotschaft inkrementiert";
CM_ SG_ 397 BMS_MV_01_CRC "Für MLB:
Berechnung siehe Lastenheft 'Kommunikationsabsicherung für FlexRay und CAN'
Ab MQB und MLBevo:
Berechnung siehe Lastenheft 'End-to-End Kommunikationsabsicherung'

Endwerte siehe Begleitdokument 'S-PDU Kennungsfolgen'";
CM_ SG_ 397 BMS_MV_IstSpannung "actual voltage of the battery / Momentanwert: Batteriespannung";
CM_ SG_ 397 BMS_MV_IstStrom "Momentanwert: Batteriestrom
Stromrichtung: ein Ladestrom wird mit positiven, ein Entladestrom mit negativen Werten angegeben";
CM_ SG_ 397 BMS_MV_SOC_HiRes "State of Charge / aktueller Ladezustand der Batterie (höhere Auflösung)";

CM_ SG_ 419 BMS_MV_02_BZ "4bit Botschaftszähler, wird mit jeder Sendebotschaft inkrementiert";
CM_ SG_ 419 BMS_MV_02_CRC "Für MLB:
Berechnung siehe Lastenheft 'Kommunikationsabsicherung für FlexRay und CAN'
Ab MQB und MLBevo:
Berechnung siehe Lastenheft 'End-to-End Kommunikationsabsicherung'

Endwerte siehe Begleitdokument 'S-PDU Kennungsfolgen'";
CM_ SG_ 419 BMS_MV_MaxDyn_EntladeStrom "max current (discharge)
maximal zulässiger Entladestrom (zwingend einzuhaltender Grenzwert); Wert ist für eine Dauer von z.B. 1s garantiert";
CM_ SG_ 419 BMS_MV_MaxDyn_LadeStrom "max current (charge)
maximal zulässiger Ladestrom (zwingend einzuhaltender Grenzwert); Wert ist für eine Dauer von z.B.  1s garantiert";
CM_ SG_ 419 BMS_MV_Min_EntladeSpannung "min. voltage / minimal erlaubte Batteriespannung (zwingend einzuhaltender Grenzwert)";
CM_ SG_ 419 BMS_MV_MinDyn_LadeSpannung "min. voltage during charge with current MaxDyn_LadeStrom resp. iChMax / rechnerischer Wert: minimales, für eine Dauer von z.B. 1s garantiertes Spannungsniveau, das unter Belastung mit MaxDyn_LadeStrom bzw. iChMax nicht unterschritten werden würde";
CM_ SG_ 419 BMS_MV_MinDynEntladeSpannung "min. voltage during discharge with current MaxDyn_EntladeStrom resp. iDisChMax / rechnerischer Wert: minimales, für eine Dauer von ~1s garantiertes Spannungsniveau, das unter Belastung mit MaxDyn_EntladeStrom bzw. iDisChMax nicht unterschritten werden wür";

CM_ SG_ 871 BMS_MV_03_BZ "4bit Botschaftszähler, wird mit jeder Sendebotschaft inkrementiert";
CM_ SG_ 871 BMS_MV_03_CRC "Für MLB:
Berechnung siehe Lastenheft 'Kommunikationsabsicherung für FlexRay und CAN'
Ab MQB und MLBevo:
Berechnung siehe Lastenheft 'End-to-End Kommunikationsabsicherung'

Endwerte siehe Begleitdokument 'S-PDU Kennungsfolgen'";
CM_ SG_ 871 BMS_MV_Leistungsreduzierung "Signalisierung der Performanceeinschränkung der 48V Batterie aufgrund hoher Temperatur";
CM_ SG_ 871 BMS_MV_Max_LadeSpannung "max. voltage / maximal erlaubte Batteriespannung (zwingend einzuhaltender Grenzwert)";
CM_ SG_ 871 BMS_MV_MaxPred_EntladeStrom "dynamic el. limit, max. current (discharge) for the specified time (e.g. 10s): and the voltage limit (only for prediction)
rechnerischer Wert: quasistationärer, für eine Dauer von z.B. 10s garantierter maximaler Entladestrom";
CM_ SG_ 871 BMS_MV_MaxPred_LadeStrom "dynamic el. limit, max. current (charge) for the specified time (e.g. 10s), and the voltage limit (only for prediction) 
rechnerischer Wert: quasistationärer, für eine Dauer von z.B. 10s garantierter maximaler Ladestrom";
CM_ SG_ 871 BMS_MV_MinPred_EntladeSpannung "static el. limit, min. battery voltage (e.g. 10s) during current MaxPred_EntladeStrom resp iDisChPredMax / rechnerischer Wert: minimales, für eine Dauer von z.B.  10s garantiertes Spannungsniveau, das unter Belastung mit MaxPred_EntladeStrom bzw. iDisChPr";
CM_ SG_ 871 BMS_MV_MinPred_LadeSpannung "static el. limit, min. battery voltage (e.g. 10s) during current MaxPred_LadeStrom resp. iChPredMax / rechnerischer Wert: minimales, für eine Dauer von z.B. 10s garantiertes Spannungsniveau, das unter Belastung mit MaxPred_LadeStrom bzw. iChPredMax nicht ";

CM_ SG_ 1443 BMS_MV_04_BZ "4bit Botschaftszähler, wird mit jeder Sendebotschaft inkrementiert";
CM_ SG_ 1443 BMS_MV_04_CRC "Für MLB:
Berechnung siehe Lastenheft 'Kommunikationsabsicherung für FlexRay und CAN'
Ab MQB und MLBevo:
Berechnung siehe Lastenheft 'End-to-End Kommunikationsabsicherung'

Endwerte siehe Begleitdokument 'S-PDU Kennungsfolgen'";
CM_ SG_ 1443 BMS_MV_FehlerStatus "aktueller Fehlerstatus der Batterie";
CM_ SG_ 1443 BMS_MV_IstModus "actual state of the battery / momentaner Status der Batterie
0: Standby; Kommunikation aktiv
1: Hauptschütze geschlossen / MV-Netz aktiviert / normaler Fahrbetrieb
5: interner Batteriefehler / angeforderter Modus kann nicht eingestellt werden
7: Initi";
CM_ SG_ 1443 BMS_MV_OBD_Lampe_Anf "Anforderung MIL (MalfunctionIndicationLamp) von BMS (Motorsteuergerät reicht diese Info an Kombi weiter).";

CM_ SG_ 2589283412 BMS_MV_IstRuecklaufTemperatur "Aktuelle Ruecklauftemperatur der Batterie

Abweichender individueller Init-Wert = 254 (Standardkodierung = 254)";
CM_ SG_ 2589283412 BMS_MV_IstVorlaufTemperatur "Aktuelle Vorlauftemperatur der Batterie

Abweichender individueller Init-Wert = 254 (Standardkodierung = 254)";
CM_ SG_ 2589283412 BMS_MV_Soll_PWM_Pumpe "Fehlende Beschreibung (Import)";
CM_ SG_ 2589283412 BMS_MV_SollVolumenstrom "Mindestanforderung des Soll Volumenstrom für Kühlkreislauf Batterie";
CM_ SG_ 2589283412 BMS_MV_SollVorlauftemperatur "Soll_Vorlauftemperatur_Kühlmedium in °C

Abweichender individueller Init-Wert = 254 (Standardkodierung = 254)";
CM_ SG_ 2589283412 BMS_MV_Speichertechnologie "Speichertechnologie des MV-Speichers. Zuordnung zur Technologie in MV FLAH.";
CM_ SG_ 2589283412 BMS_MV_Temp_Epsilon "Das Signal beschreibt die Differenz zwischen Batterie Soll-Temperatur und Batterie Ist-Temperatur.";
CM_ SG_ 2589283412 BMS_MV_Temperatur "battery temperature / Momentanwert: Temperatur der Traktionsbatterie

Abweichender individueller Init-Wert = 254 (Standardkodierung = 254)";
CM_ SG_ 2589283412 BMS_MV_Temperierung_Anf "Temperierungsbedarf der HV-Batterie";

CM_ SG_ 2589283608 BMS_MV_Energieinhalt "aktuell nutzbarer Energieinhalt der MV-Batterie
(bezogen auf ein definiertes mittleres Belastungsprofil)";
CM_ SG_ 2589283608 BMS_MV_MaxEnergieinhalt "maximaler nutzbarer Energieinhalt der MV-Batterie (bezogen auf Last KBI_RWDS_Lastprofil bei SOC=100%)
Abhängig von KBI_RWDS_Lastprofil";

CM_ SG_ 2589283606 BMS_MV_max_Grenz_SOC "oberer Grenz SOC - Betriebsstrategie";
CM_ SG_ 2589283606 BMS_MV_min_Grenz_SOC "unterer Grenz-SOC - Tiefentladeschutz";
CM_ SG_ 2589283606 BMS_MV_SOC_Kaltstart "Abhängig von der notwendigen Kaltstartleistung berechneter SOC Wert.";

CM_ SG_ 1021 BMS_MV_Pred_Entladeperformance "Indikator Stromintegral in Entladerichtung. 
0%     = Start abrampen Peak-Entladestromgrenze auf Dauer-Entladestromgrenze.
100% = Voller Peak-Entladestrom verfügbar";
CM_ SG_ 1021 BMS_MV_Pred_Ladeperformance "Indikator Stromintegral in Laderichtung. 
0%     = Start abrampen Peak-Ladestromgrenze auf Dauer-Ladestromgrenze.
100% = Voller Peak-Ladestrom verfügbar";

CM_ SG_ 499 BMS_NV_01_BZ "-";
CM_ SG_ 499 BMS_NV_01_CRC "Berechnung siehe Lastenheft 'End-to-End Kommunikationsabsicherung'";
CM_ SG_ 499 BMS_NV_BatterieAb "Detektion einer Verbindungsunterbrechung von oder zur Batterie bzw. Funktion der Batterie ist nicht gegeben
- Polunterbrechung
- Bolzen- oder Massekabelunterbrechung
- interne Unterbechung
Funktion bei geschlossenem Trennelement";
CM_ SG_ 499 BMS_NV_FMAus_Info "Freilauf Informationssignal zum Freilaufkoordinator. 
Gilt nur für die Freilauf Phase. Verwendung im MicroHybrid.";
CM_ SG_ 499 BMS_NV_IstModus "actual state of the battery / momentaner Status der Batterie
Standby; Kommunikation aktiv
Hauptschütz geschlossen / NV-Netz aktiviert / normaler Fahrbetrieb
interner Batteriefehler / angeforderter Modus kann nicht eingestellt werdenInitialisierung";
CM_ SG_ 499 BMS_NV_IstSpannung "actual voltage of the battery / Momentanwert: Batteriespannung";
CM_ SG_ 499 BMS_NV_IstStrom "Ausgabe des aktuell gemessenen Stroms des 12V Zusatzspeichers.
negative Werte: Entladestrom bezogen auf den Energiespeicher
positive Werte: Ladestrom bezogen auf den Energiespeicher";
CM_ SG_ 499 BMS_NV_StSt_Nutzbare_Ladung "Energie aus dem Zusatzspeicher, welche für die StartStopp-Funktion in den Stopp-Phasen genutzt wird. Wird berücksichtig zur Bildung des Signals BEM_StartStopp_Info";
CM_ SG_ 499 BMS_NV_TE_Status "Garantierte Unterstützung des Zusatzspeichers. Nur bei garantierter Bordnetztstützung des Zusatzspeichers kann in Freilauf-Motor-Aus Phase übergegangen werden. Geht der Zustand von 'Trennelement_geschlossen_Mindestzeit' auf 'Trennelement_geschlossen' blei";

CM_ SG_ 504 BMS_NV_Fehlerstatus "aktueller Fehlerstatus der Batterie";
CM_ SG_ 504 BMS_NV_IMaxStart "Aktuell gemessenes Stromdelta bei aktuellem Spannungseinbruch";
CM_ SG_ 504 BMS_NV_Qe_LI_Inhalt "Bei größer 0 ist ein RSG Start mit den vorgegebenen Strom und Spannungsgrenzen noch möglich";
CM_ SG_ 504 BMS_NV_Ri_Batterie "Innenwiderstand in Entladerichtung";
CM_ SG_ 504 BMS_NV_SOC "State of Charge / aktueller Ladezustand der Batterie";
CM_ SG_ 504 BMS_NV_UMinStart "Aktuell gemessener Spannungseinbruch (Minimalwert der Spannung) des letzten Motorstarts ";

CM_ SG_ 874 BMS_NV_Diagnose_Anf "Wunsch zur Diagnose des Trennelements und Anforderung von Prüfpulsen für BZE";
CM_ SG_ 874 BMS_NV_Kapazitaet_akt "Gesamtenergiekapazitaet der NV-Batterie unter Berücksichtigung der Alterung";
CM_ SG_ 874 BMS_NV_Max_EntladeStrom "maximal zulässiger Entladestrom";
CM_ SG_ 874 BMS_NV_Max_LadeSpannung "max. voltage / maximal erlaubte Batteriespannung (zwingend einzuhaltender Grenzwert)";
CM_ SG_ 874 BMS_NV_Max_LadeStrom "maximal zulässiger Ladestrom";
CM_ SG_ 874 BMS_NV_Min_EntladeSpannung "min. voltage / minimal erlaubte Batteriespannung (zwingend einzuhaltender Grenzwert)";
CM_ SG_ 874 BMS_NV_Temperatur "battery temperature / Momentanwert: Temperatur der Batterie";

CM_ SG_ 2463978664 BMS_NV_Polspannung "Spannung gemessen unmittelbar vor den Polen des Speichers";

CM_ SG_ 2463978720 BMS_NV_05_BZ "4bit Botschaftszähler, wird mit jeder Sendebotschaft inkrementiert";
CM_ SG_ 2463978720 BMS_NV_05_CRC "Für MLB:
Berechnung siehe Lastenheft 'Kommunikationsabsicherung für FlexRay und CAN'
Ab MQB und MLBevo:
Berechnung siehe Lastenheft 'End-to-End Kommunikationsabsicherung'

Endwerte siehe Begleitdokument 'S-PDU Kennungsfolgen'";
CM_ SG_ 2463978720 BMS_NV_IstDyn_EntladeStrom "dynamic el. limit, max. current (discharge) for the specified time (e.g. 1s): under consideration of voltage limit (BMS_NV_SollDyn_EntladeSpannung) //
rechnerischer Wert: quasistationärer, für eine Dauer von z.B. 1s garantierter maximaler Entladestrom un";
CM_ SG_ 2463978720 BMS_NV_IstPred_EntladeStrom "prediction el. limit, max. current (discharge) for the specified time (e.g. 18s): under consideration of voltage limit (BMS_NV_SollPred_EntladeSpannung) //
rechnerischer Wert: quasistationärer, für eine Dauer von z.B. 18s garantierter maximaler Entladest";
CM_ SG_ 2463978720 BMS_NV_SollDyn_EntladeSpannung "min. voltage during discharge with current BMS_NV_IstDyn_EntladeStrom // fester Wert: für eine Dauer von ~1s garantiertes Spannungsniveau, das unter Belastung mit BMS_NV_IstDyn_EntladeStrom nicht unterschritten werden würde.";
CM_ SG_ 2463978720 BMS_NV_SollPred_EntladeSpannung "min. voltage during discharge with current BMS_NV_IstPred_EntladeStrom // fester Wert: für eine Dauer von ~18s garantiertes Spannungsniveau, das unter Belastung mit BMS_NV_IstPred_EntladeStrom nicht unterschritten werden würde.";

CM_ SG_ 179 Bremse_EV_01_BZ "Botschaftszähler
Botschaft asynchron geroutet. Zählerwert kann springen.";
CM_ SG_ 179 Bremse_EV_01_CRC "Für MLB:
'Berechnung siehe Lastenheft 'Kommunikationsabsicherung für FlexRay und CAN''

Ab MQB und MLBevo:
'Berechnung siehe Lastenheft 'End-to-End Kommunikationsabsicherung''

Endwerte siehe Begleitdokument 'S-PDU Kennungsfolgen'";
CM_ SG_ 179 EBKV_Activate_Fallback_ESP "Das Signal aktiviert im ESC die Rückfallebene.";
CM_ SG_ 179 EBKV_Anforderung_HMS "Anforderung an dem Haltemanager vom EBKV";
CM_ SG_ 179 EBKV_Aussteuerdruck "Das Signal übermittelt seitens des EBKVs frühzeitig den aktuellen, Fahrsituations-abhängig-variablen Brems-Vordruck an das ESC, bei dem die maximale Bremskraftunterstützung des EBVK erreicht ist. 
Über diesen übermittelten Druck-Wert erkennt das ESC den ";
CM_ SG_ 179 EBKV_Bremspedalweg "Bremspedalwert in Prozent. Der Wert ist Nullpunkt-abgeglichen.
Bremspedalweg von der EBKV eingelesen.";
CM_ SG_ 179 EBKV_ECD_Fehler "EBKV hat die Radbremsmomentenschnittstelle zum MSG aufgrund eines Fehlers für den Zündungslauf abgeschaltet. Mit Fehlerspeichereintrag im EBKV.";
CM_ SG_ 179 EBKV_ECD_nicht_verfuegbar "EBKV kann das vom MSG geforderte Radbremsmoment aktuell  nicht umsetzen (z.B. Netzwerkmanagement-Betriebe - KL15 Aus; ggf. Diagnosezustände, ...). Ohne Fehlereintrag im EBKV, im Zündungslauf reversibel.";
CM_ SG_ 179 EBKV_Fahrer_bremst "Fahrer will bremsen (Eintreterkennung).
Wird benötigt, um ACC oder GRA abzuschalten.";
CM_ SG_ 179 EBKV_Fallback_Freigabe "Das Signal erteilt die Freigabe auf das Signal EBKV_Activate_FallBack_ESP";
CM_ SG_ 179 EBKV_Generatorsollmoment "Sollwert für Modifikation des verfügbaren Generatormoments";
CM_ SG_ 179 EBKV_M_Br_Fahrerwunsch "Fahrer-Gesamt-Wunschbremsmoment (bezogen auf Radebene der Primärachse)";
CM_ SG_ 179 EBKV_QBit_Fahrer_bremst "
";
CM_ SG_ 179 EBKV_Status "Status der eBKV";

CM_ SG_ 901 CHA_Fahrer_Umschaltung "Die manuelle Umschaltung durch den Fahrer soll signalisiert werden, um zu automatischen Umschaltungen (z.B. Retries) differenzieren zu können.";
CM_ SG_ 901 CHA_Fahrer_Umschaltung_BMA "Die manuelle Umschaltung der Betriebsmodusauswahl durch den Fahrer soll signalisiert werden, um zu automatischen Umschaltungen (z.B. Retries) differenzieren zu können.";
CM_ SG_ 901 CHA_Ziel_FahrPr_ACC "MQB
Anforderung Ziel-Fahrprogramm ACC";
CM_ SG_ 901 CHA_Ziel_FahrPr_AFS "Anforderung Ziel-Fahrprogramm AFS";
CM_ SG_ 901 CHA_Ziel_FahrPr_AGA "Anforderung Ziel-Fahrprogramm AGA/SAK2 (Aussensound)";
CM_ SG_ 901 CHA_Ziel_FahrPr_ALR "Anforderung Ziel-Fahrprogramm Allrad";
CM_ SG_ 901 CHA_Ziel_FahrPr_DR "Anforderung Ziel-Fahrprogramm Dämpfer";
CM_ SG_ 901 CHA_Ziel_FahrPr_EPS "Anforderung Ziel-Fahrprogramm Elektrische Lenkhilfe";
CM_ SG_ 901 CHA_Ziel_FahrPr_ESP "Anforderung Ziel-Fahrprogramm ESP";
CM_ SG_ 901 CHA_Ziel_FahrPr_Freilauf "Anforderung Ziel-Fahrprogramm Funktion Freilauf";
CM_ SG_ 901 CHA_Ziel_FahrPr_GE "Anforderung Ziel-Fahrprogramm Getriebe";
CM_ SG_ 901 CHA_Ziel_FahrPr_MO "Anforderung Ziel-Fahrprogramm Motor";
CM_ SG_ 901 CHA_Ziel_FahrPr_MO_BZS "Anforderung Zielfahrprogramm Motor-Betriebszusände";
CM_ SG_ 901 CHA_Ziel_FahrPr_MO_StSt "Anforderung Ziel-Fahrprogramm Funktion Motor Start-Stopp";
CM_ SG_ 901 CHA_Ziel_FahrPr_PreCrash "Anforderung Ziel-Fahrprogramm PreCrash";
CM_ SG_ 901 CHA_Ziel_FahrPr_SAK "Anforderung Ziel-Fahrprogramm Soundaktuator";
CM_ SG_ 901 CHA_Ziel_FahrPr_VAQ "Anforderung Ziel-Fahrprogramm VAQ";

CM_ SG_ 1022 CHA_Current_Mode_BMA "Aktuell eingestellter Charisma Betriebsmodus";
CM_ SG_ 1022 CHA_Fahrer_Umschaltung "Die manuelle Umschaltung durch den Fahrer soll signalisiert werden, um zu automatischen Umschaltungen (z.B. Retries) differenzieren zu können.";
CM_ SG_ 1022 CHA_Fahrer_Umschaltung_BMA "Die manuelle Umschaltung der Betriebsmodusauswahl durch den Fahrer soll signalisiert werden, um zu automatischen Umschaltungen (z.B. Retries) differenzieren zu können.";
CM_ SG_ 1022 CHA_Ziel_FahrPr_AGK "Signal zur Ansteuerung des Teilnehmers Abgasklappen durch den Charisma-Koordinator über das Motor-SG";
CM_ SG_ 1022 CHA_Ziel_FahrPr_BMS "Anforderung Ziel-Fahrprogramm BMS (nähere Spezifikation siehe Charisma-LH PAG)";
CM_ SG_ 1022 CHA_Ziel_FahrPr_EDS "Anforderung Ziel-Fahrprogramm Elektronische Differentialsperre";
CM_ SG_ 1022 CHA_Ziel_FahrPr_HHC "Anforderung Ziel-Fahrprogramm Hill Hold Control";
CM_ SG_ 1022 CHA_Ziel_FahrPr_MO_Freilauf "Anforderung Ziel-Fahrprogramm Funktion Freilauf Motor aus";
CM_ SG_ 1022 CHA_Ziel_FahrPr_PACC "Anforderung Ziel-Fahrprogramm InnoDrive (PACCh)";
CM_ SG_ 1022 CHA_Ziel_FahrPr_PDC "Signal zur Ansteuerung des PDC/PLA durch den Charisma-Koordinator";
CM_ SG_ 1022 CHA_Ziel_FahrPr_Reku_ZwGas "Anforderung Ziel-Fahrprogramm für Rekuperation oder Zwischengas";

CM_ SG_ 2589283686 DC_MV_CALID_CVN_MUX "Alle CALID-Indizes bilden zusammen die CALID";
CM_ SG_ 2589283686 DC_MV_CALID_Index_01 "Software-Calibration-Identification (CALID) im ASCII-Zeichenformat; 
für Ausgabe an das Generic Scan-Tool für OBD in NAR

0x30 entspricht ASCII '0'";
CM_ SG_ 2589283686 DC_MV_CALID_Index_02 "Software-Calibration-Identification (CALID) im ASCII-Zeichenformat; 
für Ausgabe an das Generic Scan-Tool für OBD in NAR

0x30 entspricht ASCII '0'";
CM_ SG_ 2589283686 DC_MV_CALID_Index_03 "Software-Calibration-Identification (CALID) im ASCII-Zeichenformat; 
für Ausgabe an das Generic Scan-Tool für OBD in NAR

0x30 entspricht ASCII '0'";
CM_ SG_ 2589283686 DC_MV_CALID_Index_04 "Software-Calibration-Identification (CALID) im ASCII-Zeichenformat; 
für Ausgabe an das Generic Scan-Tool für OBD in NAR

0x30 entspricht ASCII '0'";
CM_ SG_ 2589283686 DC_MV_CALID_Index_05 "Software-Calibration-Identification (CALID) im ASCII-Zeichenformat; 
für Ausgabe an das Generic Scan-Tool für OBD in NAR

0x30 entspricht ASCII '0'";
CM_ SG_ 2589283686 DC_MV_CALID_Index_06 "Software-Calibration-Identification (CALID) im ASCII-Zeichenformat; 
für Ausgabe an das Generic Scan-Tool für OBD in NAR

0x30 entspricht ASCII '0'";
CM_ SG_ 2589283686 DC_MV_CALID_Index_07 "Software-Calibration-Identification (CALID) im ASCII-Zeichenformat; 
für Ausgabe an das Generic Scan-Tool für OBD in NAR

0x30 entspricht ASCII '0'";
CM_ SG_ 2589283686 DC_MV_CALID_Index_08 "Software-Calibration-Identification (CALID) im ASCII-Zeichenformat; 
für Ausgabe an das Generic Scan-Tool für OBD in NAR

0x30 entspricht ASCII '0'";
CM_ SG_ 2589283686 DC_MV_CALID_Index_09 "Software-Calibration-Identification (CALID) im ASCII-Zeichenformat; 
für Ausgabe an das Generic Scan-Tool für OBD in NAR

0x30 entspricht ASCII '0'";
CM_ SG_ 2589283686 DC_MV_CALID_Index_10 "Software-Calibration-Identification (CALID) im ASCII-Zeichenformat; 
für Ausgabe an das Generic Scan-Tool für OBD in NAR

0x30 entspricht ASCII '0'";
CM_ SG_ 2589283686 DC_MV_CALID_Index_11 "Software-Calibration-Identification (CALID) im ASCII-Zeichenformat; 
für Ausgabe an das Generic Scan-Tool für OBD in NAR

0x30 entspricht ASCII '0'";
CM_ SG_ 2589283686 DC_MV_CALID_Index_12 "Software-Calibration-Identification (CALID) im ASCII-Zeichenformat; 
für Ausgabe an das Generic Scan-Tool für OBD in NAR

0x30 entspricht ASCII '0'";
CM_ SG_ 2589283686 DC_MV_CALID_Index_13 "Software-Calibration-Identification (CALID) im ASCII-Zeichenformat; 
für Ausgabe an das Generic Scan-Tool für OBD in NAR

0x30 entspricht ASCII '0'";
CM_ SG_ 2589283686 DC_MV_CALID_Index_14 "Software-Calibration-Identification (CALID) im ASCII-Zeichenformat; 
für Ausgabe an das Generic Scan-Tool für OBD in NAR

0x30 entspricht ASCII '0'";
CM_ SG_ 2589283686 DC_MV_CALID_Index_15 "Software-Calibration-Identification (CALID) im ASCII-Zeichenformat; 
für Ausgabe an das Generic Scan-Tool für OBD in NAR

0x30 entspricht ASCII '0'";
CM_ SG_ 2589283686 DC_MV_CALID_Index_16 "Software-Calibration-Identification (CALID) im ASCII-Zeichenformat; 
für Ausgabe an das Generic Scan-Tool für OBD in NAR

0x30 entspricht ASCII '0'";
CM_ SG_ 2589283686 DC_MV_CVN_Byte_1 "Calibration Verification Number (CVN bzw. Checksumme) des SW- und Datenstandes; 
für Ausgabe an das Generic Scan-Tool für OBD in NAR";
CM_ SG_ 2589283686 DC_MV_CVN_Byte_2 "Calibration Verification Number (CVN bzw. Checksumme) des SW- und Datenstandes; 
für Ausgabe an das Generic Scan-Tool für OBD in NAR";
CM_ SG_ 2589283686 DC_MV_CVN_Byte_3 "Calibration Verification Number (CVN bzw. Checksumme) des SW- und Datenstandes; 
für Ausgabe an das Generic Scan-Tool für OBD in NAR";
CM_ SG_ 2589283686 DC_MV_CVN_Byte_4 "Calibration Verification Number (CVN bzw. Checksumme) des SW- und Datenstandes; 
für Ausgabe an das Generic Scan-Tool für OBD in NAR";
CM_ SG_ 2589283686 DC_MV_CVN_VLD "Valid-Bit der Calibration-Verification-Number (CVN bzw. Checksumme)";

CM_ SG_ 2589283393 DC_MV_Komponentenfehler_01 "Übertragung OBD relevanter Fehlerpfade vom Secondary zum Primary Steuergerät. 
Zuordnung der generischen Komponentenfehler muss zwischen Sender und Empfänger abgestimmt werden.";
CM_ SG_ 2589283393 DC_MV_Komponentenfehler_02 "Übertragung OBD relevanter Fehlerpfade vom Secondary zum Primary Steuergerät. 
Zuordnung der generischen Komponentenfehler muss zwischen Sender und Empfänger abgestimmt werden.";
CM_ SG_ 2589283393 DC_MV_Komponentenfehler_03 "Übertragung OBD relevanter Fehlerpfade vom Secondary zum Primary Steuergerät. 
Zuordnung der generischen Komponentenfehler muss zwischen Sender und Empfänger abgestimmt werden.";
CM_ SG_ 2589283393 DC_MV_Komponentenfehler_04 "Übertragung OBD relevanter Fehlerpfade vom Secondary zum Primary Steuergerät. 
Zuordnung der generischen Komponentenfehler muss zwischen Sender und Empfänger abgestimmt werden.";
CM_ SG_ 2589283393 DC_MV_Komponentenfehler_05 "Übertragung OBD relevanter Fehlerpfade vom Secondary zum Primary Steuergerät. 
Zuordnung der generischen Komponentenfehler muss zwischen Sender und Empfänger abgestimmt werden.";
CM_ SG_ 2589283393 DC_MV_Komponentenfehler_06 "Übertragung OBD relevanter Fehlerpfade vom Secondary zum Primary Steuergerät. 
Zuordnung der generischen Komponentenfehler muss zwischen Sender und Empfänger abgestimmt werden.";
CM_ SG_ 2589283393 DC_MV_Komponentenfehler_07 "Übertragung OBD relevanter Fehlerpfade vom Secondary zum Primary Steuergerät. 
Zuordnung der generischen Komponentenfehler muss zwischen Sender und Empfänger abgestimmt werden.";
CM_ SG_ 2589283393 DC_MV_Komponentenfehler_08 "Übertragung OBD relevanter Fehlerpfade vom Secondary zum Primary Steuergerät. 
Zuordnung der generischen Komponentenfehler muss zwischen Sender und Empfänger abgestimmt werden.";
CM_ SG_ 2589283393 DC_MV_Komponentenfehler_09 "Übertragung OBD relevanter Fehlerpfade vom Secondary zum Primary Steuergerät. 
Zuordnung der generischen Komponentenfehler muss zwischen Sender und Empfänger abgestimmt werden.";
CM_ SG_ 2589283393 DC_MV_Komponentenfehler_10 "Übertragung OBD relevanter Fehlerpfade vom Secondary zum Primary Steuergerät. 
Zuordnung der generischen Komponentenfehler muss zwischen Sender und Empfänger abgestimmt werden.";
CM_ SG_ 2589283393 DC_MV_Komponentenfehler_11 "Übertragung OBD relevanter Fehlerpfade vom Secondary zum Primary Steuergerät. 
Zuordnung der generischen Komponentenfehler muss zwischen Sender und Empfänger abgestimmt werden.";
CM_ SG_ 2589283393 DC_MV_Komponentenfehler_12 "Übertragung OBD relevanter Fehlerpfade vom Secondary zum Primary Steuergerät. 
Zuordnung der generischen Komponentenfehler muss zwischen Sender und Empfänger abgestimmt werden.";
CM_ SG_ 2589283393 DC_MV_Komponentenfehler_13 "Übertragung OBD relevanter Fehlerpfade vom Secondary zum Primary Steuergerät. 
Zuordnung der generischen Komponentenfehler muss zwischen Sender und Empfänger abgestimmt werden.";
CM_ SG_ 2589283393 DC_MV_Komponentenfehler_14 "Übertragung OBD relevanter Fehlerpfade vom Secondary zum Primary Steuergerät. 
Zuordnung der generischen Komponentenfehler muss zwischen Sender und Empfänger abgestimmt werden.";
CM_ SG_ 2589283393 DC_MV_Komponentenfehler_15 "Übertragung OBD relevanter Fehlerpfade vom Secondary zum Primary Steuergerät. 
Zuordnung der generischen Komponentenfehler muss zwischen Sender und Empfänger abgestimmt werden.";
CM_ SG_ 2589283393 DC_MV_Komponentenfehler_16 "Übertragung OBD relevanter Fehlerpfade vom Secondary zum Primary Steuergerät. 
Zuordnung der generischen Komponentenfehler muss zwischen Sender und Empfänger abgestimmt werden.";
CM_ SG_ 2589283393 DC_MV_Komponentenfehler_17 "Übertragung OBD relevanter Fehlerpfade vom Secondary zum Primary Steuergerät. 
Zuordnung der generischen Komponentenfehler muss zwischen Sender und Empfänger abgestimmt werden.";
CM_ SG_ 2589283393 DC_MV_Komponentenfehler_18 "Übertragung OBD relevanter Fehlerpfade vom Secondary zum Primary Steuergerät. 
Zuordnung der generischen Komponentenfehler muss zwischen Sender und Empfänger abgestimmt werden.";
CM_ SG_ 2589283393 DC_MV_Komponentenfehler_19 "Übertragung OBD relevanter Fehlerpfade vom Secondary zum Primary Steuergerät. 
Zuordnung der generischen Komponentenfehler muss zwischen Sender und Empfänger abgestimmt werden.";
CM_ SG_ 2589283393 DC_MV_Komponentenfehler_20 "Übertragung OBD relevanter Fehlerpfade vom Secondary zum Primary Steuergerät. 
Zuordnung der generischen Komponentenfehler muss zwischen Sender und Empfänger abgestimmt werden.";
CM_ SG_ 2589283393 DC_MV_Komponentenfehler_21 "Übertragung OBD relevanter Fehlerpfade vom Secondary zum Primary Steuergerät. 
Zuordnung der generischen Komponentenfehler muss zwischen Sender und Empfänger abgestimmt werden.";
CM_ SG_ 2589283393 DC_MV_Komponentenfehler_22 "Übertragung OBD relevanter Fehlerpfade vom Secondary zum Primary Steuergerät. 
Zuordnung der generischen Komponentenfehler muss zwischen Sender und Empfänger abgestimmt werden.";
CM_ SG_ 2589283393 DC_MV_Komponentenfehler_23 "Übertragung OBD relevanter Fehlerpfade vom Secondary zum Primary Steuergerät. 
Zuordnung der generischen Komponentenfehler muss zwischen Sender und Empfänger abgestimmt werden.";
CM_ SG_ 2589283393 DC_MV_Komponentenfehler_24 "Übertragung OBD relevanter Fehlerpfade vom Secondary zum Primary Steuergerät. 
Zuordnung der generischen Komponentenfehler muss zwischen Sender und Empfänger abgestimmt werden.";
CM_ SG_ 2589283393 DC_MV_Komponentenfehler_25 "Übertragung OBD relevanter Fehlerpfade vom Secondary zum Primary Steuergerät. 
Zuordnung der generischen Komponentenfehler muss zwischen Sender und Empfänger abgestimmt werden.";
CM_ SG_ 2589283393 DC_MV_Komponentenfehler_26 "Übertragung OBD relevanter Fehlerpfade vom Secondary zum Primary Steuergerät. 
Zuordnung der generischen Komponentenfehler muss zwischen Sender und Empfänger abgestimmt werden.";
CM_ SG_ 2589283393 DC_MV_Komponentenfehler_27 "Übertragung OBD relevanter Fehlerpfade vom Secondary zum Primary Steuergerät. 
Zuordnung der generischen Komponentenfehler muss zwischen Sender und Empfänger abgestimmt werden.";
CM_ SG_ 2589283393 DC_MV_Komponentenfehler_28 "Übertragung OBD relevanter Fehlerpfade vom Secondary zum Primary Steuergerät. 
Zuordnung der generischen Komponentenfehler muss zwischen Sender und Empfänger abgestimmt werden.";
CM_ SG_ 2589283393 DC_MV_Komponentenfehler_29 "Übertragung OBD relevanter Fehlerpfade vom Secondary zum Primary Steuergerät. 
Zuordnung der generischen Komponentenfehler muss zwischen Sender und Empfänger abgestimmt werden.";
CM_ SG_ 2589283393 DC_MV_Komponentenfehler_30 "Übertragung OBD relevanter Fehlerpfade vom Secondary zum Primary Steuergerät. 
Zuordnung der generischen Komponentenfehler muss zwischen Sender und Empfänger abgestimmt werden.";
CM_ SG_ 2589283393 DC_MV_Komponentenfehler_31 "Übertragung OBD relevanter Fehlerpfade vom Secondary zum Primary Steuergerät. 
Zuordnung der generischen Komponentenfehler muss zwischen Sender und Empfänger abgestimmt werden.";
CM_ SG_ 2589283393 DC_MV_Komponentenfehler_VLD "Valid-Bit der OBD-Komponentenfehler. Das Bit wird beim Fehlerspeicher löschen zurückgenommen und erst wieder gesetzt, wenn der Fehlerspeicher vollständig gelöscht wurde. Der Primary-OBD-ECU soll damit mitgeteilt werden, ob sie den Inhalten der Komponenten";

CM_ SG_ 2589283855 DC_MV_Komponentenfehler_32 "Übertragung OBD relevanter Fehlerpfade vom Secondary zum Primary Steuergerät.
Zuordnung der generischen Komponentenfehler muss zwischen Sender und Empfänger abgestimmt werden.";
CM_ SG_ 2589283855 DC_MV_Komponentenfehler_33 "Übertragung OBD relevanter Fehlerpfade vom Secondary zum Primary Steuergerät.
Zuordnung der generischen Komponentenfehler muss zwischen Sender und Empfänger abgestimmt werden.";
CM_ SG_ 2589283855 DC_MV_Komponentenfehler_34 "Übertragung OBD relevanter Fehlerpfade vom Secondary zum Primary Steuergerät.
Zuordnung der generischen Komponentenfehler muss zwischen Sender und Empfänger abgestimmt werden.";
CM_ SG_ 2589283855 DC_MV_Komponentenfehler_35 "Übertragung OBD relevanter Fehlerpfade vom Secondary zum Primary Steuergerät.
Zuordnung der generischen Komponentenfehler muss zwischen Sender und Empfänger abgestimmt werden.";
CM_ SG_ 2589283855 DC_MV_Komponentenfehler_36 "Übertragung OBD relevanter Fehlerpfade vom Secondary zum Primary Steuergerät.
Zuordnung der generischen Komponentenfehler muss zwischen Sender und Empfänger abgestimmt werden.";
CM_ SG_ 2589283855 DC_MV_Komponentenfehler_37 "Übertragung OBD relevanter Fehlerpfade vom Secondary zum Primary Steuergerät.
Zuordnung der generischen Komponentenfehler muss zwischen Sender und Empfänger abgestimmt werden.";
CM_ SG_ 2589283855 DC_MV_Komponentenfehler_38 "Übertragung OBD relevanter Fehlerpfade vom Secondary zum Primary Steuergerät.
Zuordnung der generischen Komponentenfehler muss zwischen Sender und Empfänger abgestimmt werden.";
CM_ SG_ 2589283855 DC_MV_Komponentenfehler_39 "Übertragung OBD relevanter Fehlerpfade vom Secondary zum Primary Steuergerät.
Zuordnung der generischen Komponentenfehler muss zwischen Sender und Empfänger abgestimmt werden.";
CM_ SG_ 2589283855 DC_MV_Komponentenfehler_40 "Übertragung OBD relevanter Fehlerpfade vom Secondary zum Primary Steuergerät.
Zuordnung der generischen Komponentenfehler muss zwischen Sender und Empfänger abgestimmt werden.";
CM_ SG_ 2589283855 DC_MV_Komponentenfehler_41 "Übertragung OBD relevanter Fehlerpfade vom Secondary zum Primary Steuergerät.
Zuordnung der generischen Komponentenfehler muss zwischen Sender und Empfänger abgestimmt werden.";
CM_ SG_ 2589283855 DC_MV_Komponentenfehler_42 "Übertragung OBD relevanter Fehlerpfade vom Secondary zum Primary Steuergerät.
Zuordnung der generischen Komponentenfehler muss zwischen Sender und Empfänger abgestimmt werden.";
CM_ SG_ 2589283855 DC_MV_Komponentenfehler_43 "Übertragung OBD relevanter Fehlerpfade vom Secondary zum Primary Steuergerät.
Zuordnung der generischen Komponentenfehler muss zwischen Sender und Empfänger abgestimmt werden.";
CM_ SG_ 2589283855 DC_MV_Komponentenfehler_44 "Übertragung OBD relevanter Fehlerpfade vom Secondary zum Primary Steuergerät.
Zuordnung der generischen Komponentenfehler muss zwischen Sender und Empfänger abgestimmt werden.";
CM_ SG_ 2589283855 DC_MV_Komponentenfehler_45 "Übertragung OBD relevanter Fehlerpfade vom Secondary zum Primary Steuergerät.
Zuordnung der generischen Komponentenfehler muss zwischen Sender und Empfänger abgestimmt werden.";
CM_ SG_ 2589283855 DC_MV_Komponentenfehler_46 "Übertragung OBD relevanter Fehlerpfade vom Secondary zum Primary Steuergerät.
Zuordnung der generischen Komponentenfehler muss zwischen Sender und Empfänger abgestimmt werden.";
CM_ SG_ 2589283855 DC_MV_Komponentenfehler_47 "Übertragung OBD relevanter Fehlerpfade vom Secondary zum Primary Steuergerät.
Zuordnung der generischen Komponentenfehler muss zwischen Sender und Empfänger abgestimmt werden.";
CM_ SG_ 2589283855 DC_MV_Komponentenfehler_48 "Übertragung OBD relevanter Fehlerpfade vom Secondary zum Primary Steuergerät.
Zuordnung der generischen Komponentenfehler muss zwischen Sender und Empfänger abgestimmt werden.";
CM_ SG_ 2589283855 DC_MV_Komponentenfehler_49 "Übertragung OBD relevanter Fehlerpfade vom Secondary zum Primary Steuergerät.
Zuordnung der generischen Komponentenfehler muss zwischen Sender und Empfänger abgestimmt werden.";
CM_ SG_ 2589283855 DC_MV_Komponentenfehler_50 "Übertragung OBD relevanter Fehlerpfade vom Secondary zum Primary Steuergerät.
Zuordnung der generischen Komponentenfehler muss zwischen Sender und Empfänger abgestimmt werden.";
CM_ SG_ 2589283855 DC_MV_Komponentenfehler_51 "Übertragung OBD relevanter Fehlerpfade vom Secondary zum Primary Steuergerät.
Zuordnung der generischen Komponentenfehler muss zwischen Sender und Empfänger abgestimmt werden.";
CM_ SG_ 2589283855 DC_MV_Komponentenfehler_52 "Übertragung OBD relevanter Fehlerpfade vom Secondary zum Primary Steuergerät.
Zuordnung der generischen Komponentenfehler muss zwischen Sender und Empfänger abgestimmt werden.";
CM_ SG_ 2589283855 DC_MV_Komponentenfehler_53 "Übertragung OBD relevanter Fehlerpfade vom Secondary zum Primary Steuergerät.
Zuordnung der generischen Komponentenfehler muss zwischen Sender und Empfänger abgestimmt werden.";
CM_ SG_ 2589283855 DC_MV_Komponentenfehler_54 "Übertragung OBD relevanter Fehlerpfade vom Secondary zum Primary Steuergerät.
Zuordnung der generischen Komponentenfehler muss zwischen Sender und Empfänger abgestimmt werden.";
CM_ SG_ 2589283855 DC_MV_Komponentenfehler_55 "Übertragung OBD relevanter Fehlerpfade vom Secondary zum Primary Steuergerät.
Zuordnung der generischen Komponentenfehler muss zwischen Sender und Empfänger abgestimmt werden.";
CM_ SG_ 2589283855 DC_MV_Komponentenfehler_56 "Übertragung OBD relevanter Fehlerpfade vom Secondary zum Primary Steuergerät.
Zuordnung der generischen Komponentenfehler muss zwischen Sender und Empfänger abgestimmt werden.";
CM_ SG_ 2589283855 DC_MV_Komponentenfehler_57 "Übertragung OBD relevanter Fehlerpfade vom Secondary zum Primary Steuergerät.
Zuordnung der generischen Komponentenfehler muss zwischen Sender und Empfänger abgestimmt werden.";
CM_ SG_ 2589283855 DC_MV_Komponentenfehler_58 "Übertragung OBD relevanter Fehlerpfade vom Secondary zum Primary Steuergerät.
Zuordnung der generischen Komponentenfehler muss zwischen Sender und Empfänger abgestimmt werden.";
CM_ SG_ 2589283855 DC_MV_Komponentenfehler_59 "Übertragung OBD relevanter Fehlerpfade vom Secondary zum Primary Steuergerät.
Zuordnung der generischen Komponentenfehler muss zwischen Sender und Empfänger abgestimmt werden.";
CM_ SG_ 2589283855 DC_MV_Komponentenfehler_60 "Übertragung OBD relevanter Fehlerpfade vom Secondary zum Primary Steuergerät.
Zuordnung der generischen Komponentenfehler muss zwischen Sender und Empfänger abgestimmt werden.";
CM_ SG_ 2589283855 DC_MV_Komponentenfehler_61 "Übertragung OBD relevanter Fehlerpfade vom Secondary zum Primary Steuergerät.
Zuordnung der generischen Komponentenfehler muss zwischen Sender und Empfänger abgestimmt werden.";
CM_ SG_ 2589283855 DC_MV_Komponentenfehler_62 "Übertragung OBD relevanter Fehlerpfade vom Secondary zum Primary Steuergerät.
Zuordnung der generischen Komponentenfehler muss zwischen Sender und Empfänger abgestimmt werden.";

CM_ SG_ 2589283856 DC_MV_Komponentenfehler_63 "Übertragung OBD relevanter Fehlerpfade vom Secondary zum Primary Steuergerät.
Zuordnung der generischen Komponentenfehler muss zwischen Sender und Empfänger abgestimmt werden.";
CM_ SG_ 2589283856 DC_MV_Komponentenfehler_64 "Übertragung OBD relevanter Fehlerpfade vom Secondary zum Primary Steuergerät.
Zuordnung der generischen Komponentenfehler muss zwischen Sender und Empfänger abgestimmt werden.";
CM_ SG_ 2589283856 DC_MV_Komponentenfehler_65 "Übertragung OBD relevanter Fehlerpfade vom Secondary zum Primary Steuergerät.
Zuordnung der generischen Komponentenfehler muss zwischen Sender und Empfänger abgestimmt werden.";
CM_ SG_ 2589283856 DC_MV_Komponentenfehler_66 "Übertragung OBD relevanter Fehlerpfade vom Secondary zum Primary Steuergerät.
Zuordnung der generischen Komponentenfehler muss zwischen Sender und Empfänger abgestimmt werden.";
CM_ SG_ 2589283856 DC_MV_Komponentenfehler_67 "Übertragung OBD relevanter Fehlerpfade vom Secondary zum Primary Steuergerät.
Zuordnung der generischen Komponentenfehler muss zwischen Sender und Empfänger abgestimmt werden.";
CM_ SG_ 2589283856 DC_MV_Komponentenfehler_68 "Übertragung OBD relevanter Fehlerpfade vom Secondary zum Primary Steuergerät.
Zuordnung der generischen Komponentenfehler muss zwischen Sender und Empfänger abgestimmt werden.";
CM_ SG_ 2589283856 DC_MV_Komponentenfehler_69 "Übertragung OBD relevanter Fehlerpfade vom Secondary zum Primary Steuergerät.
Zuordnung der generischen Komponentenfehler muss zwischen Sender und Empfänger abgestimmt werden.";
CM_ SG_ 2589283856 DC_MV_Komponentenfehler_70 "Übertragung OBD relevanter Fehlerpfade vom Secondary zum Primary Steuergerät.
Zuordnung der generischen Komponentenfehler muss zwischen Sender und Empfänger abgestimmt werden.";
CM_ SG_ 2589283856 DC_MV_Komponentenfehler_71 "Übertragung OBD relevanter Fehlerpfade vom Secondary zum Primary Steuergerät.
Zuordnung der generischen Komponentenfehler muss zwischen Sender und Empfänger abgestimmt werden.";
CM_ SG_ 2589283856 DC_MV_Komponentenfehler_72 "Übertragung OBD relevanter Fehlerpfade vom Secondary zum Primary Steuergerät.
Zuordnung der generischen Komponentenfehler muss zwischen Sender und Empfänger abgestimmt werden.";
CM_ SG_ 2589283856 DC_MV_Komponentenfehler_73 "Übertragung OBD relevanter Fehlerpfade vom Secondary zum Primary Steuergerät.
Zuordnung der generischen Komponentenfehler muss zwischen Sender und Empfänger abgestimmt werden.";
CM_ SG_ 2589283856 DC_MV_Komponentenfehler_74 "Übertragung OBD relevanter Fehlerpfade vom Secondary zum Primary Steuergerät.
Zuordnung der generischen Komponentenfehler muss zwischen Sender und Empfänger abgestimmt werden.";
CM_ SG_ 2589283856 DC_MV_Komponentenfehler_75 "Übertragung OBD relevanter Fehlerpfade vom Secondary zum Primary Steuergerät.
Zuordnung der generischen Komponentenfehler muss zwischen Sender und Empfänger abgestimmt werden.";
CM_ SG_ 2589283856 DC_MV_Komponentenfehler_76 "Übertragung OBD relevanter Fehlerpfade vom Secondary zum Primary Steuergerät.
Zuordnung der generischen Komponentenfehler muss zwischen Sender und Empfänger abgestimmt werden.";
CM_ SG_ 2589283856 DC_MV_Komponentenfehler_77 "Übertragung OBD relevanter Fehlerpfade vom Secondary zum Primary Steuergerät.
Zuordnung der generischen Komponentenfehler muss zwischen Sender und Empfänger abgestimmt werden.";
CM_ SG_ 2589283856 DC_MV_Komponentenfehler_78 "Übertragung OBD relevanter Fehlerpfade vom Secondary zum Primary Steuergerät.
Zuordnung der generischen Komponentenfehler muss zwischen Sender und Empfänger abgestimmt werden.";
CM_ SG_ 2589283856 DC_MV_Komponentenfehler_79 "Übertragung OBD relevanter Fehlerpfade vom Secondary zum Primary Steuergerät.
Zuordnung der generischen Komponentenfehler muss zwischen Sender und Empfänger abgestimmt werden.";
CM_ SG_ 2589283856 DC_MV_Komponentenfehler_80 "Übertragung OBD relevanter Fehlerpfade vom Secondary zum Primary Steuergerät.
Zuordnung der generischen Komponentenfehler muss zwischen Sender und Empfänger abgestimmt werden.";
CM_ SG_ 2589283856 DC_MV_Komponentenfehler_81 "Übertragung OBD relevanter Fehlerpfade vom Secondary zum Primary Steuergerät.
Zuordnung der generischen Komponentenfehler muss zwischen Sender und Empfänger abgestimmt werden.";
CM_ SG_ 2589283856 DC_MV_Komponentenfehler_82 "Übertragung OBD relevanter Fehlerpfade vom Secondary zum Primary Steuergerät.
Zuordnung der generischen Komponentenfehler muss zwischen Sender und Empfänger abgestimmt werden.";
CM_ SG_ 2589283856 DC_MV_Komponentenfehler_83 "Übertragung OBD relevanter Fehlerpfade vom Secondary zum Primary Steuergerät.
Zuordnung der generischen Komponentenfehler muss zwischen Sender und Empfänger abgestimmt werden.";
CM_ SG_ 2589283856 DC_MV_Komponentenfehler_84 "Übertragung OBD relevanter Fehlerpfade vom Secondary zum Primary Steuergerät.
Zuordnung der generischen Komponentenfehler muss zwischen Sender und Empfänger abgestimmt werden.";
CM_ SG_ 2589283856 DC_MV_Komponentenfehler_85 "Übertragung OBD relevanter Fehlerpfade vom Secondary zum Primary Steuergerät.
Zuordnung der generischen Komponentenfehler muss zwischen Sender und Empfänger abgestimmt werden.";
CM_ SG_ 2589283856 DC_MV_Komponentenfehler_86 "Übertragung OBD relevanter Fehlerpfade vom Secondary zum Primary Steuergerät.
Zuordnung der generischen Komponentenfehler muss zwischen Sender und Empfänger abgestimmt werden.";
CM_ SG_ 2589283856 DC_MV_Komponentenfehler_87 "Übertragung OBD relevanter Fehlerpfade vom Secondary zum Primary Steuergerät.
Zuordnung der generischen Komponentenfehler muss zwischen Sender und Empfänger abgestimmt werden.";
CM_ SG_ 2589283856 DC_MV_Komponentenfehler_88 "Übertragung OBD relevanter Fehlerpfade vom Secondary zum Primary Steuergerät.
Zuordnung der generischen Komponentenfehler muss zwischen Sender und Empfänger abgestimmt werden.";
CM_ SG_ 2589283856 DC_MV_Komponentenfehler_89 "Übertragung OBD relevanter Fehlerpfade vom Secondary zum Primary Steuergerät.
Zuordnung der generischen Komponentenfehler muss zwischen Sender und Empfänger abgestimmt werden.";
CM_ SG_ 2589283856 DC_MV_Komponentenfehler_90 "Übertragung OBD relevanter Fehlerpfade vom Secondary zum Primary Steuergerät.
Zuordnung der generischen Komponentenfehler muss zwischen Sender und Empfänger abgestimmt werden.";
CM_ SG_ 2589283856 DC_MV_Komponentenfehler_91 "Übertragung OBD relevanter Fehlerpfade vom Secondary zum Primary Steuergerät.
Zuordnung der generischen Komponentenfehler muss zwischen Sender und Empfänger abgestimmt werden.";
CM_ SG_ 2589283856 DC_MV_Komponentenfehler_92 "Übertragung OBD relevanter Fehlerpfade vom Secondary zum Primary Steuergerät.
Zuordnung der generischen Komponentenfehler muss zwischen Sender und Empfänger abgestimmt werden.";
CM_ SG_ 2589283856 DC_MV_Komponentenfehler_93 "Übertragung OBD relevanter Fehlerpfade vom Secondary zum Primary Steuergerät.
Zuordnung der generischen Komponentenfehler muss zwischen Sender und Empfänger abgestimmt werden.";

CM_ SG_ 2589283857 DC_MV_Komponentenfehler_100 "Übertragung OBD relevanter Fehlerpfade vom Secondary zum Primary Steuergerät.
Zuordnung der generischen Komponentenfehler muss zwischen Sender und Empfänger abgestimmt werden.";
CM_ SG_ 2589283857 DC_MV_Komponentenfehler_101 "Übertragung OBD relevanter Fehlerpfade vom Secondary zum Primary Steuergerät.
Zuordnung der generischen Komponentenfehler muss zwischen Sender und Empfänger abgestimmt werden.";
CM_ SG_ 2589283857 DC_MV_Komponentenfehler_102 "Übertragung OBD relevanter Fehlerpfade vom Secondary zum Primary Steuergerät.
Zuordnung der generischen Komponentenfehler muss zwischen Sender und Empfänger abgestimmt werden.";
CM_ SG_ 2589283857 DC_MV_Komponentenfehler_103 "Übertragung OBD relevanter Fehlerpfade vom Secondary zum Primary Steuergerät.
Zuordnung der generischen Komponentenfehler muss zwischen Sender und Empfänger abgestimmt werden.";
CM_ SG_ 2589283857 DC_MV_Komponentenfehler_104 "Übertragung OBD relevanter Fehlerpfade vom Secondary zum Primary Steuergerät.
Zuordnung der generischen Komponentenfehler muss zwischen Sender und Empfänger abgestimmt werden.";
CM_ SG_ 2589283857 DC_MV_Komponentenfehler_105 "Übertragung OBD relevanter Fehlerpfade vom Secondary zum Primary Steuergerät.
Zuordnung der generischen Komponentenfehler muss zwischen Sender und Empfänger abgestimmt werden.";
CM_ SG_ 2589283857 DC_MV_Komponentenfehler_106 "Übertragung OBD relevanter Fehlerpfade vom Secondary zum Primary Steuergerät.
Zuordnung der generischen Komponentenfehler muss zwischen Sender und Empfänger abgestimmt werden.";
CM_ SG_ 2589283857 DC_MV_Komponentenfehler_107 "Übertragung OBD relevanter Fehlerpfade vom Secondary zum Primary Steuergerät.
Zuordnung der generischen Komponentenfehler muss zwischen Sender und Empfänger abgestimmt werden.";
CM_ SG_ 2589283857 DC_MV_Komponentenfehler_108 "Übertragung OBD relevanter Fehlerpfade vom Secondary zum Primary Steuergerät.
Zuordnung der generischen Komponentenfehler muss zwischen Sender und Empfänger abgestimmt werden.";
CM_ SG_ 2589283857 DC_MV_Komponentenfehler_109 "Übertragung OBD relevanter Fehlerpfade vom Secondary zum Primary Steuergerät.
Zuordnung der generischen Komponentenfehler muss zwischen Sender und Empfänger abgestimmt werden.";
CM_ SG_ 2589283857 DC_MV_Komponentenfehler_110 "Übertragung OBD relevanter Fehlerpfade vom Secondary zum Primary Steuergerät.
Zuordnung der generischen Komponentenfehler muss zwischen Sender und Empfänger abgestimmt werden.";
CM_ SG_ 2589283857 DC_MV_Komponentenfehler_111 "Übertragung OBD relevanter Fehlerpfade vom Secondary zum Primary Steuergerät.
Zuordnung der generischen Komponentenfehler muss zwischen Sender und Empfänger abgestimmt werden.";
CM_ SG_ 2589283857 DC_MV_Komponentenfehler_112 "Übertragung OBD relevanter Fehlerpfade vom Secondary zum Primary Steuergerät.
Zuordnung der generischen Komponentenfehler muss zwischen Sender und Empfänger abgestimmt werden.";
CM_ SG_ 2589283857 DC_MV_Komponentenfehler_113 "Übertragung OBD relevanter Fehlerpfade vom Secondary zum Primary Steuergerät.
Zuordnung der generischen Komponentenfehler muss zwischen Sender und Empfänger abgestimmt werden.";
CM_ SG_ 2589283857 DC_MV_Komponentenfehler_114 "Übertragung OBD relevanter Fehlerpfade vom Secondary zum Primary Steuergerät.
Zuordnung der generischen Komponentenfehler muss zwischen Sender und Empfänger abgestimmt werden.";
CM_ SG_ 2589283857 DC_MV_Komponentenfehler_115 "Übertragung OBD relevanter Fehlerpfade vom Secondary zum Primary Steuergerät.
Zuordnung der generischen Komponentenfehler muss zwischen Sender und Empfänger abgestimmt werden.";
CM_ SG_ 2589283857 DC_MV_Komponentenfehler_116 "Übertragung OBD relevanter Fehlerpfade vom Secondary zum Primary Steuergerät.
Zuordnung der generischen Komponentenfehler muss zwischen Sender und Empfänger abgestimmt werden.";
CM_ SG_ 2589283857 DC_MV_Komponentenfehler_117 "Übertragung OBD relevanter Fehlerpfade vom Secondary zum Primary Steuergerät.
Zuordnung der generischen Komponentenfehler muss zwischen Sender und Empfänger abgestimmt werden.";
CM_ SG_ 2589283857 DC_MV_Komponentenfehler_118 "Übertragung OBD relevanter Fehlerpfade vom Secondary zum Primary Steuergerät.
Zuordnung der generischen Komponentenfehler muss zwischen Sender und Empfänger abgestimmt werden.";
CM_ SG_ 2589283857 DC_MV_Komponentenfehler_119 "Übertragung OBD relevanter Fehlerpfade vom Secondary zum Primary Steuergerät.
Zuordnung der generischen Komponentenfehler muss zwischen Sender und Empfänger abgestimmt werden.";
CM_ SG_ 2589283857 DC_MV_Komponentenfehler_120 "Übertragung OBD relevanter Fehlerpfade vom Secondary zum Primary Steuergerät.
Zuordnung der generischen Komponentenfehler muss zwischen Sender und Empfänger abgestimmt werden.";
CM_ SG_ 2589283857 DC_MV_Komponentenfehler_121 "Übertragung OBD relevanter Fehlerpfade vom Secondary zum Primary Steuergerät.
Zuordnung der generischen Komponentenfehler muss zwischen Sender und Empfänger abgestimmt werden.";
CM_ SG_ 2589283857 DC_MV_Komponentenfehler_122 "Übertragung OBD relevanter Fehlerpfade vom Secondary zum Primary Steuergerät.
Zuordnung der generischen Komponentenfehler muss zwischen Sender und Empfänger abgestimmt werden.";
CM_ SG_ 2589283857 DC_MV_Komponentenfehler_123 "Übertragung OBD relevanter Fehlerpfade vom Secondary zum Primary Steuergerät.
Zuordnung der generischen Komponentenfehler muss zwischen Sender und Empfänger abgestimmt werden.";
CM_ SG_ 2589283857 DC_MV_Komponentenfehler_124 "Übertragung OBD relevanter Fehlerpfade vom Secondary zum Primary Steuergerät.
Zuordnung der generischen Komponentenfehler muss zwischen Sender und Empfänger abgestimmt werden.";
CM_ SG_ 2589283857 DC_MV_Komponentenfehler_94 "Übertragung OBD relevanter Fehlerpfade vom Secondary zum Primary Steuergerät.
Zuordnung der generischen Komponentenfehler muss zwischen Sender und Empfänger abgestimmt werden.";
CM_ SG_ 2589283857 DC_MV_Komponentenfehler_95 "Übertragung OBD relevanter Fehlerpfade vom Secondary zum Primary Steuergerät.
Zuordnung der generischen Komponentenfehler muss zwischen Sender und Empfänger abgestimmt werden.";
CM_ SG_ 2589283857 DC_MV_Komponentenfehler_96 "Übertragung OBD relevanter Fehlerpfade vom Secondary zum Primary Steuergerät.
Zuordnung der generischen Komponentenfehler muss zwischen Sender und Empfänger abgestimmt werden.";
CM_ SG_ 2589283857 DC_MV_Komponentenfehler_97 "Übertragung OBD relevanter Fehlerpfade vom Secondary zum Primary Steuergerät.
Zuordnung der generischen Komponentenfehler muss zwischen Sender und Empfänger abgestimmt werden.";
CM_ SG_ 2589283857 DC_MV_Komponentenfehler_98 "Übertragung OBD relevanter Fehlerpfade vom Secondary zum Primary Steuergerät.
Zuordnung der generischen Komponentenfehler muss zwischen Sender und Empfänger abgestimmt werden.";
CM_ SG_ 2589283857 DC_MV_Komponentenfehler_99 "Übertragung OBD relevanter Fehlerpfade vom Secondary zum Primary Steuergerät.
Zuordnung der generischen Komponentenfehler muss zwischen Sender und Empfänger abgestimmt werden.";

CM_ SG_ 2589283858 DC_MV_Komponentenfehler_125 "Übertragung OBD relevanter Fehlerpfade vom Secondary zum Primary Steuergerät.
Zuordnung der generischen Komponentenfehler muss zwischen Sender und Empfänger abgestimmt werden.";
CM_ SG_ 2589283858 DC_MV_Komponentenfehler_126 "Übertragung OBD relevanter Fehlerpfade vom Secondary zum Primary Steuergerät.
Zuordnung der generischen Komponentenfehler muss zwischen Sender und Empfänger abgestimmt werden.";
CM_ SG_ 2589283858 DC_MV_Komponentenfehler_127 "Übertragung OBD relevanter Fehlerpfade vom Secondary zum Primary Steuergerät.
Zuordnung der generischen Komponentenfehler muss zwischen Sender und Empfänger abgestimmt werden.";
CM_ SG_ 2589283858 DC_MV_Komponentenfehler_128 "Übertragung OBD relevanter Fehlerpfade vom Secondary zum Primary Steuergerät.
Zuordnung der generischen Komponentenfehler muss zwischen Sender und Empfänger abgestimmt werden.";
CM_ SG_ 2589283858 DC_MV_Komponentenfehler_129 "Übertragung OBD relevanter Fehlerpfade vom Secondary zum Primary Steuergerät.
Zuordnung der generischen Komponentenfehler muss zwischen Sender und Empfänger abgestimmt werden.";
CM_ SG_ 2589283858 DC_MV_Komponentenfehler_130 "Übertragung OBD relevanter Fehlerpfade vom Secondary zum Primary Steuergerät.
Zuordnung der generischen Komponentenfehler muss zwischen Sender und Empfänger abgestimmt werden.";
CM_ SG_ 2589283858 DC_MV_Komponentenfehler_131 "Übertragung OBD relevanter Fehlerpfade vom Secondary zum Primary Steuergerät.
Zuordnung der generischen Komponentenfehler muss zwischen Sender und Empfänger abgestimmt werden.";
CM_ SG_ 2589283858 DC_MV_Komponentenfehler_132 "Übertragung OBD relevanter Fehlerpfade vom Secondary zum Primary Steuergerät.
Zuordnung der generischen Komponentenfehler muss zwischen Sender und Empfänger abgestimmt werden.";
CM_ SG_ 2589283858 DC_MV_Komponentenfehler_133 "Übertragung OBD relevanter Fehlerpfade vom Secondary zum Primary Steuergerät.
Zuordnung der generischen Komponentenfehler muss zwischen Sender und Empfänger abgestimmt werden.";
CM_ SG_ 2589283858 DC_MV_Komponentenfehler_134 "Übertragung OBD relevanter Fehlerpfade vom Secondary zum Primary Steuergerät.
Zuordnung der generischen Komponentenfehler muss zwischen Sender und Empfänger abgestimmt werden.";
CM_ SG_ 2589283858 DC_MV_Komponentenfehler_135 "Übertragung OBD relevanter Fehlerpfade vom Secondary zum Primary Steuergerät.
Zuordnung der generischen Komponentenfehler muss zwischen Sender und Empfänger abgestimmt werden.";
CM_ SG_ 2589283858 DC_MV_Komponentenfehler_136 "Übertragung OBD relevanter Fehlerpfade vom Secondary zum Primary Steuergerät.
Zuordnung der generischen Komponentenfehler muss zwischen Sender und Empfänger abgestimmt werden.";
CM_ SG_ 2589283858 DC_MV_Komponentenfehler_137 "Übertragung OBD relevanter Fehlerpfade vom Secondary zum Primary Steuergerät.
Zuordnung der generischen Komponentenfehler muss zwischen Sender und Empfänger abgestimmt werden.";
CM_ SG_ 2589283858 DC_MV_Komponentenfehler_138 "Übertragung OBD relevanter Fehlerpfade vom Secondary zum Primary Steuergerät.
Zuordnung der generischen Komponentenfehler muss zwischen Sender und Empfänger abgestimmt werden.";
CM_ SG_ 2589283858 DC_MV_Komponentenfehler_139 "Übertragung OBD relevanter Fehlerpfade vom Secondary zum Primary Steuergerät.
Zuordnung der generischen Komponentenfehler muss zwischen Sender und Empfänger abgestimmt werden.";
CM_ SG_ 2589283858 DC_MV_Komponentenfehler_140 "Übertragung OBD relevanter Fehlerpfade vom Secondary zum Primary Steuergerät.
Zuordnung der generischen Komponentenfehler muss zwischen Sender und Empfänger abgestimmt werden.";
CM_ SG_ 2589283858 DC_MV_Komponentenfehler_141 "Übertragung OBD relevanter Fehlerpfade vom Secondary zum Primary Steuergerät.
Zuordnung der generischen Komponentenfehler muss zwischen Sender und Empfänger abgestimmt werden.";
CM_ SG_ 2589283858 DC_MV_Komponentenfehler_142 "Übertragung OBD relevanter Fehlerpfade vom Secondary zum Primary Steuergerät.
Zuordnung der generischen Komponentenfehler muss zwischen Sender und Empfänger abgestimmt werden.";
CM_ SG_ 2589283858 DC_MV_Komponentenfehler_143 "Übertragung OBD relevanter Fehlerpfade vom Secondary zum Primary Steuergerät.
Zuordnung der generischen Komponentenfehler muss zwischen Sender und Empfänger abgestimmt werden.";
CM_ SG_ 2589283858 DC_MV_Komponentenfehler_144 "Übertragung OBD relevanter Fehlerpfade vom Secondary zum Primary Steuergerät.
Zuordnung der generischen Komponentenfehler muss zwischen Sender und Empfänger abgestimmt werden.";
CM_ SG_ 2589283858 DC_MV_Komponentenfehler_145 "Übertragung OBD relevanter Fehlerpfade vom Secondary zum Primary Steuergerät.
Zuordnung der generischen Komponentenfehler muss zwischen Sender und Empfänger abgestimmt werden.";
BA_DEF_ BO_  "DiagRequest" ENUM "No", "Yes";
BA_DEF_ BO_  "DiagResponse" ENUM "No", "Yes";
BA_DEF_ BO_  "DiagState" ENUM "No", "Yes";
BA_DEF_ BO_  "GenMsgChkConstant" HEX 0 4095;
BA_DEF_ BO_  "GenMsgCycleTime" INT 0 65535;
BA_DEF_ BO_  "GenMsgCycleTimeFast" INT 0 65535;
BA_DEF_ BO_  "GenMsgDelayTime" INT 0 100000;
BA_DEF_ BO_  "GenMsgILSupport" ENUM "No", "Yes";
BA_DEF_ BO_  "GenMsgNrOfRepetition" INT 0 100;
BA_DEF_ BO_  "GenMsgPDUConstants" STRING;
BA_DEF_ BO_  "GenMsgSendType" ENUM "Cyclic", "not_used", "not_used", "not_used", "not_used", "not_used", "not_used", "IfActive", "NoMsgSendType";
BA_DEF_ BO_  "GenMsgStartDelayTime" INT 0 100000;
BA_DEF_ BO_  "NmMessage" ENUM "No", "Yes";
BA_DEF_ BO_  "NmhMessage" ENUM "No", "Yes";
BA_DEF_ BO_  "MsgType" ENUM "Application", "NM ", "NMH", "TP2.0", "ISO-TP ", "BAP", "EID", "KS", "XCP_PRE_CONFIGURED", "XCP_RUNTIME_CONFIGURED";
BA_DEF_ BO_  "VAGTP20_API" HEX 0 255;
BA_DEF_ BO_  "VAGTP20_DynConnection" ENUM "No", "Yes";
BA_DEF_ BO_  "VAGTP20_DynSetup" ENUM "No", "Yes";
BA_DEF_ BO_  "VAGTP20_StatConnection" ENUM "No", "Yes";
BA_DEF_ SG_  "GenSigActiveRepetitions" INT -2147483648 2147483647;
BA_DEF_ SG_  "GenSigInactiveValue" INT -2147483648 2147483647;
BA_DEF_ SG_  "GenSigSendType" ENUM "Cyclic", "OnWrite", "OnWriteWithRepetition", "OnChange", "OnChangeWithRepetition", "IfActive", "IfActiveWithRepetition", "NoSigSendType", "OnChangeAndIfActive", "OnChangeAndIfActiveWithRepetition";
BA_DEF_ SG_  "GenSigStartValue" INT -2147483648 2147483647;
BA_DEF_ SG_  "NWM-WakeupAllowed" ENUM "No", "Yes";
BA_DEF_ SG_  "GenSigFuncType" ENUM "NoFunction", "MsgCounter", "CRC-8", "XOR", "XOR-2", "DatedBit", "SW-Kl15", "CHK", "Constant", "Protocol", "CRC-8-SAE_J1850", "CRC-32", "DataLength", "DataID", "MsgCounter16", "SOK-Signatur", "Cluster";
BA_DEF_ SG_  "GenSigSwitchedByIgnition" ENUM "No", "Yes";
BA_DEF_ SG_  "Fehlerwert" HEX 0 2147483647;
BA_DEF_ SG_  "GenSigMissingSourceValue" HEX 0 2147483647;
BA_DEF_DEF_  "DiagRequest" "No";
BA_DEF_DEF_  "DiagResponse" "No";
BA_DEF_DEF_  "DiagState" "No";
BA_DEF_DEF_  "GenMsgChkConstant" 0;
BA_DEF_DEF_  "GenMsgCycleTime" 0;
BA_DEF_DEF_  "GenMsgCycleTimeFast" 0;
BA_DEF_DEF_  "GenMsgDelayTime" 0;
BA_DEF_DEF_  "GenMsgILSupport" "No";
BA_DEF_DEF_  "GenMsgNrOfRepetition" 0;
BA_DEF_DEF_  "GenMsgPDUConstants" "";
BA_DEF_DEF_  "GenMsgSendType" "NoMsgSendType";
BA_DEF_DEF_  "GenMsgStartDelayTime" 0;
BA_DEF_DEF_  "NmMessage" "No";
BA_DEF_DEF_  "NmhMessage" "No";
BA_DEF_DEF_  "MsgType" "Application";
BA_DEF_DEF_  "VAGTP20_API" 0;
BA_DEF_DEF_  "VAGTP20_DynConnection" "No";
BA_DEF_DEF_  "VAGTP20_DynSetup" "No";
BA_DEF_DEF_  "VAGTP20_StatConnection" "No";
BA_DEF_DEF_  "GenSigActiveRepetitions" 0;
BA_DEF_DEF_  "GenSigInactiveValue" 0;
BA_DEF_DEF_  "GenSigSendType" "NoSigSendType";
BA_DEF_DEF_  "GenSigStartValue" 0;
BA_DEF_DEF_  "NWM-WakeupAllowed" "No";
BA_DEF_DEF_  "GenSigFuncType" "NoFunction";
BA_DEF_DEF_  "GenSigSwitchedByIgnition" "Yes";
BA_DEF_DEF_  "Fehlerwert" 0;
BA_DEF_DEF_  "GenSigMissingSourceValue" 0;
BA_ "GenMsgCycleTime" BO_ 881 60;
BA_ "GenMsgILSupport" BO_ 881 1;
BA_ "GenMsgSendType" BO_ 881 0;
BA_ "GenMsgCycleTime" BO_ 2463978713 120;
BA_ "GenMsgILSupport" BO_ 2463978713 1;
BA_ "GenMsgSendType" BO_ 2463978713 0;
BA_ "GenMsgChkConstant" BO_ 1400 72;
BA_ "GenMsgCycleTime" BO_ 1400 1000;
BA_ "GenMsgCycleTimeFast" BO_ 1400 100;
BA_ "GenMsgILSupport" BO_ 1400 1;
BA_ "GenMsgPDUConstants" BO_ 1400 "0x48,0x48,0x48,0x48,0x48,0x48,0x48,0x48,0x48,0x48,0x48,0x48,0x48,0x48,0x48,0x48";
BA_ "GenMsgSendType" BO_ 1400 0;
BA_ "GenMsgCycleTime" BO_ 397 10;
BA_ "GenMsgILSupport" BO_ 397 1;
BA_ "GenMsgPDUConstants" BO_ 397 "0x9c,0xcc,0xe1,0x4c,0xc9,0x39,0xe3,0x53,0x78,0x33,0x15,0x49,0x55,0x0a,0x62,0x83";
BA_ "GenMsgSendType" BO_ 397 0;
BA_ "GenMsgCycleTime" BO_ 419 20;
BA_ "GenMsgILSupport" BO_ 419 1;
BA_ "GenMsgPDUConstants" BO_ 419 "0x4a,0x06,0x0a,0x36,0xf8,0xd3,0x60,0x79,0xaa,0xd2,0x2e,0x89,0xa3,0x76,0x5f,0x45";
BA_ "GenMsgSendType" BO_ 419 0;
BA_ "GenMsgCycleTime" BO_ 871 100;
BA_ "GenMsgILSupport" BO_ 871 1;
BA_ "GenMsgPDUConstants" BO_ 871 "0xa1,0xb0,0xdb,0x69,0x9c,0xef,0xbd,0x08,0xdd,0xcc,0x1b,0x05,0xce,0x20,0xe1,0x48";
BA_ "GenMsgSendType" BO_ 871 0;
BA_ "GenMsgCycleTime" BO_ 1443 500;
BA_ "GenMsgDelayTime" BO_ 1443 20;
BA_ "GenMsgILSupport" BO_ 1443 1;
BA_ "GenMsgPDUConstants" BO_ 1443 "0x0a,0xd3,0xaa,0x89,0x5f,0xc4,0x27,0x2d,0xfb,0xa0,0x47,0x1e,0x28,0xa8,0x44,0x5c";
BA_ "GenMsgSendType" BO_ 1443 0;
BA_ "GenMsgCycleTime" BO_ 2589283412 500;
BA_ "GenMsgILSupport" BO_ 2589283412 1;
BA_ "GenMsgSendType" BO_ 2589283412 0;
BA_ "GenMsgCycleTime" BO_ 2589283608 500;
BA_ "GenMsgILSupport" BO_ 2589283608 1;
BA_ "GenMsgSendType" BO_ 2589283608 0;
BA_ "GenMsgCycleTime" BO_ 2589283606 1000;
BA_ "GenMsgILSupport" BO_ 2589283606 1;
BA_ "GenMsgSendType" BO_ 2589283606 0;
BA_ "GenMsgCycleTime" BO_ 1021 100;
BA_ "GenMsgILSupport" BO_ 1021 1;
BA_ "GenMsgSendType" BO_ 1021 0;
BA_ "GenMsgCycleTime" BO_ 499 100;
BA_ "GenMsgDelayTime" BO_ 499 10;
BA_ "GenMsgILSupport" BO_ 499 1;
BA_ "GenMsgPDUConstants" BO_ 499 "0xc4,0x1e,0x9c,0xae,0x59,0xcc,0x66,0x99,0xe1,0x87,0xe8,0x4c,0x65,0x4a,0xc9,0xde";
BA_ "GenMsgSendType" BO_ 499 0;
BA_ "GenMsgCycleTime" BO_ 504 100;
BA_ "GenMsgDelayTime" BO_ 504 10;
BA_ "GenMsgILSupport" BO_ 504 1;
BA_ "GenMsgSendType" BO_ 504 0;
BA_ "GenMsgCycleTime" BO_ 874 500;
BA_ "GenMsgILSupport" BO_ 874 1;
BA_ "GenMsgSendType" BO_ 874 0;
BA_ "GenMsgCycleTime" BO_ 2463978664 100;
BA_ "GenMsgILSupport" BO_ 2463978664 1;
BA_ "GenMsgSendType" BO_ 2463978664 0;
BA_ "GenMsgCycleTime" BO_ 2463978720 100;
BA_ "GenMsgILSupport" BO_ 2463978720 1;
BA_ "GenMsgPDUConstants" BO_ 2463978720 "0xd0,0x4d,0x22,0xae,0x8a,0x67,0xf4,0x35,0x15,0x2a,0xb8,0x4e,0xcc,0x07,0xad,0xa2";
BA_ "GenMsgSendType" BO_ 2463978720 0;
BA_ "GenMsgChkConstant" BO_ 179 65;
BA_ "GenMsgCycleTime" BO_ 179 1000;
BA_ "GenMsgILSupport" BO_ 179 1;
BA_ "GenMsgPDUConstants" BO_ 179 "0x41,0x41,0x41,0x41,0x41,0x41,0x41,0x41,0x41,0x41,0x41,0x41,0x41,0x41,0x41,0x41";
BA_ "GenMsgSendType" BO_ 179 0;
BA_ "MsgType" BO_ 2617236992 6;
BA_ "MsgType" BO_ 2617236993 6;
BA_ "MsgType" BO_ 2617130752 6;
BA_ "MsgType" BO_ 2617130753 6;
BA_ "MsgType" BO_ 2617194240 6;
BA_ "MsgType" BO_ 2617194241 6;
BA_ "MsgType" BO_ 2617124352 6;
BA_ "MsgType" BO_ 2617124353 6;
BA_ "GenMsgCycleTime" BO_ 901 1000;
BA_ "GenMsgDelayTime" BO_ 901 50;
BA_ "GenMsgILSupport" BO_ 901 1;
BA_ "GenMsgSendType" BO_ 901 0;
BA_ "GenMsgStartDelayTime" BO_ 901 50;
BA_ "GenMsgCycleTime" BO_ 1022 1000;
BA_ "GenMsgDelayTime" BO_ 1022 50;
BA_ "GenMsgILSupport" BO_ 1022 1;
BA_ "GenMsgSendType" BO_ 1022 0;
BA_ "GenMsgStartDelayTime" BO_ 1022 50;
BA_ "GenMsgCycleTime" BO_ 2589283686 960;
BA_ "GenMsgILSupport" BO_ 2589283686 1;
BA_ "GenMsgSendType" BO_ 2589283686 0;
BA_ "GenMsgCycleTime" BO_ 2589283393 1000;
BA_ "GenMsgILSupport" BO_ 2589283393 1;
BA_ "GenMsgSendType" BO_ 2589283393 0;
BA_ "GenMsgCycleTime" BO_ 2589283855 500;
BA_ "GenMsgILSupport" BO_ 2589283855 1;
BA_ "GenMsgSendType" BO_ 2589283855 0;
BA_ "GenMsgCycleTime" BO_ 2589283856 500;
BA_ "GenMsgILSupport" BO_ 2589283856 1;
BA_ "GenMsgSendType" BO_ 2589283856 0;
BA_ "GenMsgCycleTime" BO_ 2589283857 500;
BA_ "GenMsgILSupport" BO_ 2589283857 1;
BA_ "GenMsgSendType" BO_ 2589283857 0;
BA_ "GenMsgCycleTime" BO_ 2589283858 500;
BA_ "GenMsgILSupport" BO_ 2589283858 1;
BA_ "GenMsgSendType" BO_ 2589283858 0;
BA_ "GenSigSendType" SG_ 881 BMS_CMC_02_MUX 0;
BA_ "GenSigSwitchedByIgnition" SG_ 881 BMS_CMC_02_MUX 0;
BA_ "GenSigStartValue" SG_ 881 BMS_CMC_Zellspannung_081 4094;
BA_ "GenSigSwitchedByIgnition" SG_ 881 BMS_CMC_Zellspannung_081 0;
BA_ "Fehlerwert" SG_ 881 BMS_CMC_Zellspannung_081 4095;
BA_ "GenSigStartValue" SG_ 881 BMS_CMC_Zellspannung_082 4094;
BA_ "GenSigSwitchedByIgnition" SG_ 881 BMS_CMC_Zellspannung_082 0;
BA_ "Fehlerwert" SG_ 881 BMS_CMC_Zellspannung_082 4095;
BA_ "GenSigStartValue" SG_ 881 BMS_CMC_Zellspannung_083 4094;
BA_ "GenSigSwitchedByIgnition" SG_ 881 BMS_CMC_Zellspannung_083 0;
BA_ "Fehlerwert" SG_ 881 BMS_CMC_Zellspannung_083 4095;
BA_ "GenSigStartValue" SG_ 881 BMS_CMC_Zellspannung_084 4094;
BA_ "GenSigSwitchedByIgnition" SG_ 881 BMS_CMC_Zellspannung_084 0;
BA_ "Fehlerwert" SG_ 881 BMS_CMC_Zellspannung_084 4095;
BA_ "GenSigStartValue" SG_ 881 BMS_CMC_Zellspannung_085 4094;
BA_ "GenSigSwitchedByIgnition" SG_ 881 BMS_CMC_Zellspannung_085 0;
BA_ "Fehlerwert" SG_ 881 BMS_CMC_Zellspannung_085 4095;
BA_ "GenSigStartValue" SG_ 881 BMS_CMC_Zellspannung_086 4094;
BA_ "GenSigSwitchedByIgnition" SG_ 881 BMS_CMC_Zellspannung_086 0;
BA_ "Fehlerwert" SG_ 881 BMS_CMC_Zellspannung_086 4095;
BA_ "GenSigStartValue" SG_ 881 BMS_CMC_Zellspannung_087 4094;
BA_ "GenSigSwitchedByIgnition" SG_ 881 BMS_CMC_Zellspannung_087 0;
BA_ "Fehlerwert" SG_ 881 BMS_CMC_Zellspannung_087 4095;
BA_ "GenSigStartValue" SG_ 881 BMS_CMC_Zellspannung_088 4094;
BA_ "GenSigSwitchedByIgnition" SG_ 881 BMS_CMC_Zellspannung_088 0;
BA_ "Fehlerwert" SG_ 881 BMS_CMC_Zellspannung_088 4095;
BA_ "GenSigStartValue" SG_ 881 BMS_CMC_Zellspannung_089 4094;
BA_ "GenSigSwitchedByIgnition" SG_ 881 BMS_CMC_Zellspannung_089 0;
BA_ "Fehlerwert" SG_ 881 BMS_CMC_Zellspannung_089 4095;
BA_ "GenSigStartValue" SG_ 881 BMS_CMC_Zellspannung_090 4094;
BA_ "GenSigSwitchedByIgnition" SG_ 881 BMS_CMC_Zellspannung_090 0;
BA_ "Fehlerwert" SG_ 881 BMS_CMC_Zellspannung_090 4095;
BA_ "GenSigStartValue" SG_ 881 BMS_CMC_Zellspannung_091 4094;
BA_ "GenSigSwitchedByIgnition" SG_ 881 BMS_CMC_Zellspannung_091 0;
BA_ "Fehlerwert" SG_ 881 BMS_CMC_Zellspannung_091 4095;
BA_ "GenSigStartValue" SG_ 881 BMS_CMC_Zellspannung_092 4094;
BA_ "GenSigSwitchedByIgnition" SG_ 881 BMS_CMC_Zellspannung_092 0;
BA_ "Fehlerwert" SG_ 881 BMS_CMC_Zellspannung_092 4095;
BA_ "GenSigStartValue" SG_ 881 BMS_CMC_Zellspannung_093 4094;
BA_ "GenSigSwitchedByIgnition" SG_ 881 BMS_CMC_Zellspannung_093 0;
BA_ "Fehlerwert" SG_ 881 BMS_CMC_Zellspannung_093 4095;
BA_ "GenSigStartValue" SG_ 881 BMS_CMC_Zellspannung_094 4094;
BA_ "GenSigSwitchedByIgnition" SG_ 881 BMS_CMC_Zellspannung_094 0;
BA_ "Fehlerwert" SG_ 881 BMS_CMC_Zellspannung_094 4095;
BA_ "GenSigStartValue" SG_ 881 BMS_CMC_Zellspannung_095 4094;
BA_ "GenSigSwitchedByIgnition" SG_ 881 BMS_CMC_Zellspannung_095 0;
BA_ "Fehlerwert" SG_ 881 BMS_CMC_Zellspannung_095 4095;
BA_ "GenSigStartValue" SG_ 881 BMS_CMC_Zellspannung_096 4094;
BA_ "GenSigSwitchedByIgnition" SG_ 881 BMS_CMC_Zellspannung_096 0;
BA_ "Fehlerwert" SG_ 881 BMS_CMC_Zellspannung_096 4095;
BA_ "GenSigStartValue" SG_ 881 BMS_CMC_Zellspannung_097 4094;
BA_ "GenSigSwitchedByIgnition" SG_ 881 BMS_CMC_Zellspannung_097 0;
BA_ "Fehlerwert" SG_ 881 BMS_CMC_Zellspannung_097 4095;
BA_ "GenSigStartValue" SG_ 881 BMS_CMC_Zellspannung_098 4094;
BA_ "GenSigSwitchedByIgnition" SG_ 881 BMS_CMC_Zellspannung_098 0;
BA_ "Fehlerwert" SG_ 881 BMS_CMC_Zellspannung_098 4095;
BA_ "GenSigStartValue" SG_ 881 BMS_CMC_Zellspannung_099 4094;
BA_ "GenSigSwitchedByIgnition" SG_ 881 BMS_CMC_Zellspannung_099 0;
BA_ "Fehlerwert" SG_ 881 BMS_CMC_Zellspannung_099 4095;
BA_ "GenSigStartValue" SG_ 881 BMS_CMC_Zellspannung_100 4094;
BA_ "GenSigSwitchedByIgnition" SG_ 881 BMS_CMC_Zellspannung_100 0;
BA_ "Fehlerwert" SG_ 881 BMS_CMC_Zellspannung_100 4095;
BA_ "GenSigStartValue" SG_ 881 BMS_CMC_Zellspannung_101 4094;
BA_ "GenSigSwitchedByIgnition" SG_ 881 BMS_CMC_Zellspannung_101 0;
BA_ "Fehlerwert" SG_ 881 BMS_CMC_Zellspannung_101 4095;
BA_ "GenSigStartValue" SG_ 881 BMS_CMC_Zellspannung_102 4094;
BA_ "GenSigSwitchedByIgnition" SG_ 881 BMS_CMC_Zellspannung_102 0;
BA_ "Fehlerwert" SG_ 881 BMS_CMC_Zellspannung_102 4095;
BA_ "GenSigStartValue" SG_ 881 BMS_CMC_Zellspannung_103 4094;
BA_ "GenSigSwitchedByIgnition" SG_ 881 BMS_CMC_Zellspannung_103 0;
BA_ "Fehlerwert" SG_ 881 BMS_CMC_Zellspannung_103 4095;
BA_ "GenSigStartValue" SG_ 881 BMS_CMC_Zellspannung_104 4094;
BA_ "GenSigSwitchedByIgnition" SG_ 881 BMS_CMC_Zellspannung_104 0;
BA_ "Fehlerwert" SG_ 881 BMS_CMC_Zellspannung_104 4095;
BA_ "GenSigStartValue" SG_ 881 BMS_CMC_Zellspannung_105 4094;
BA_ "GenSigSwitchedByIgnition" SG_ 881 BMS_CMC_Zellspannung_105 0;
BA_ "Fehlerwert" SG_ 881 BMS_CMC_Zellspannung_105 4095;
BA_ "GenSigStartValue" SG_ 881 BMS_CMC_Zellspannung_106 4094;
BA_ "GenSigSwitchedByIgnition" SG_ 881 BMS_CMC_Zellspannung_106 0;
BA_ "Fehlerwert" SG_ 881 BMS_CMC_Zellspannung_106 4095;
BA_ "GenSigStartValue" SG_ 881 BMS_CMC_Zellspannung_107 4094;
BA_ "GenSigSwitchedByIgnition" SG_ 881 BMS_CMC_Zellspannung_107 0;
BA_ "Fehlerwert" SG_ 881 BMS_CMC_Zellspannung_107 4095;
BA_ "GenSigStartValue" SG_ 881 BMS_CMC_Zellspannung_108 4094;
BA_ "GenSigSwitchedByIgnition" SG_ 881 BMS_CMC_Zellspannung_108 0;
BA_ "Fehlerwert" SG_ 881 BMS_CMC_Zellspannung_108 4095;
BA_ "GenSigStartValue" SG_ 881 BMS_CMC_Zellspannung_109 4094;
BA_ "GenSigSwitchedByIgnition" SG_ 881 BMS_CMC_Zellspannung_109 0;
BA_ "Fehlerwert" SG_ 881 BMS_CMC_Zellspannung_109 4095;
BA_ "GenSigStartValue" SG_ 881 BMS_CMC_Zellspannung_110 4094;
BA_ "GenSigSwitchedByIgnition" SG_ 881 BMS_CMC_Zellspannung_110 0;
BA_ "Fehlerwert" SG_ 881 BMS_CMC_Zellspannung_110 4095;
BA_ "GenSigStartValue" SG_ 881 BMS_CMC_Zellspannung_111 4094;
BA_ "GenSigSwitchedByIgnition" SG_ 881 BMS_CMC_Zellspannung_111 0;
BA_ "Fehlerwert" SG_ 881 BMS_CMC_Zellspannung_111 4095;
BA_ "GenSigStartValue" SG_ 881 BMS_CMC_Zellspannung_112 4094;
BA_ "GenSigSwitchedByIgnition" SG_ 881 BMS_CMC_Zellspannung_112 0;
BA_ "Fehlerwert" SG_ 881 BMS_CMC_Zellspannung_112 4095;
BA_ "GenSigStartValue" SG_ 881 BMS_CMC_Zellspannung_113 4094;
BA_ "GenSigSwitchedByIgnition" SG_ 881 BMS_CMC_Zellspannung_113 0;
BA_ "Fehlerwert" SG_ 881 BMS_CMC_Zellspannung_113 4095;
BA_ "GenSigStartValue" SG_ 881 BMS_CMC_Zellspannung_114 4094;
BA_ "GenSigSwitchedByIgnition" SG_ 881 BMS_CMC_Zellspannung_114 0;
BA_ "Fehlerwert" SG_ 881 BMS_CMC_Zellspannung_114 4095;
BA_ "GenSigStartValue" SG_ 881 BMS_CMC_Zellspannung_115 4094;
BA_ "GenSigSwitchedByIgnition" SG_ 881 BMS_CMC_Zellspannung_115 0;
BA_ "Fehlerwert" SG_ 881 BMS_CMC_Zellspannung_115 4095;
BA_ "GenSigStartValue" SG_ 881 BMS_CMC_Zellspannung_116 4094;
BA_ "GenSigSwitchedByIgnition" SG_ 881 BMS_CMC_Zellspannung_116 0;
BA_ "Fehlerwert" SG_ 881 BMS_CMC_Zellspannung_116 4095;
BA_ "GenSigStartValue" SG_ 881 BMS_CMC_Zellspannung_117 4094;
BA_ "GenSigSwitchedByIgnition" SG_ 881 BMS_CMC_Zellspannung_117 0;
BA_ "Fehlerwert" SG_ 881 BMS_CMC_Zellspannung_117 4095;
BA_ "GenSigStartValue" SG_ 881 BMS_CMC_Zellspannung_118 4094;
BA_ "GenSigSwitchedByIgnition" SG_ 881 BMS_CMC_Zellspannung_118 0;
BA_ "Fehlerwert" SG_ 881 BMS_CMC_Zellspannung_118 4095;
BA_ "GenSigStartValue" SG_ 881 BMS_CMC_Zellspannung_119 4094;
BA_ "GenSigSwitchedByIgnition" SG_ 881 BMS_CMC_Zellspannung_119 0;
BA_ "Fehlerwert" SG_ 881 BMS_CMC_Zellspannung_119 4095;
BA_ "GenSigStartValue" SG_ 881 BMS_CMC_Zellspannung_120 4094;
BA_ "GenSigSwitchedByIgnition" SG_ 881 BMS_CMC_Zellspannung_120 0;
BA_ "Fehlerwert" SG_ 881 BMS_CMC_Zellspannung_120 4095;
BA_ "GenSigStartValue" SG_ 881 BMS_CMC_Zellspannung_121 4094;
BA_ "GenSigSwitchedByIgnition" SG_ 881 BMS_CMC_Zellspannung_121 0;
BA_ "Fehlerwert" SG_ 881 BMS_CMC_Zellspannung_121 4095;
BA_ "GenSigStartValue" SG_ 881 BMS_CMC_Zellspannung_122 4094;
BA_ "GenSigSwitchedByIgnition" SG_ 881 BMS_CMC_Zellspannung_122 0;
BA_ "Fehlerwert" SG_ 881 BMS_CMC_Zellspannung_122 4095;
BA_ "GenSigStartValue" SG_ 881 BMS_CMC_Zellspannung_123 4094;
BA_ "GenSigSwitchedByIgnition" SG_ 881 BMS_CMC_Zellspannung_123 0;
BA_ "Fehlerwert" SG_ 881 BMS_CMC_Zellspannung_123 4095;
BA_ "GenSigStartValue" SG_ 881 BMS_CMC_Zellspannung_124 4094;
BA_ "GenSigSwitchedByIgnition" SG_ 881 BMS_CMC_Zellspannung_124 0;
BA_ "Fehlerwert" SG_ 881 BMS_CMC_Zellspannung_124 4095;
BA_ "GenSigStartValue" SG_ 881 BMS_CMC_Zellspannung_125 4094;
BA_ "GenSigSwitchedByIgnition" SG_ 881 BMS_CMC_Zellspannung_125 0;
BA_ "Fehlerwert" SG_ 881 BMS_CMC_Zellspannung_125 4095;
BA_ "GenSigStartValue" SG_ 881 BMS_CMC_Zellspannung_126 4094;
BA_ "GenSigSwitchedByIgnition" SG_ 881 BMS_CMC_Zellspannung_126 0;
BA_ "Fehlerwert" SG_ 881 BMS_CMC_Zellspannung_126 4095;
BA_ "GenSigStartValue" SG_ 881 BMS_CMC_Zellspannung_127 4094;
BA_ "GenSigSwitchedByIgnition" SG_ 881 BMS_CMC_Zellspannung_127 0;
BA_ "Fehlerwert" SG_ 881 BMS_CMC_Zellspannung_127 4095;
BA_ "GenSigStartValue" SG_ 881 BMS_CMC_Zellspannung_128 4094;
BA_ "GenSigSwitchedByIgnition" SG_ 881 BMS_CMC_Zellspannung_128 0;
BA_ "Fehlerwert" SG_ 881 BMS_CMC_Zellspannung_128 4095;
BA_ "GenSigStartValue" SG_ 881 BMS_CMC_Zellspannung_129 4094;
BA_ "GenSigSwitchedByIgnition" SG_ 881 BMS_CMC_Zellspannung_129 0;
BA_ "Fehlerwert" SG_ 881 BMS_CMC_Zellspannung_129 4095;
BA_ "GenSigStartValue" SG_ 881 BMS_CMC_Zellspannung_130 4094;
BA_ "GenSigSwitchedByIgnition" SG_ 881 BMS_CMC_Zellspannung_130 0;
BA_ "Fehlerwert" SG_ 881 BMS_CMC_Zellspannung_130 4095;
BA_ "GenSigStartValue" SG_ 881 BMS_CMC_Zellspannung_131 4094;
BA_ "GenSigSwitchedByIgnition" SG_ 881 BMS_CMC_Zellspannung_131 0;
BA_ "Fehlerwert" SG_ 881 BMS_CMC_Zellspannung_131 4095;
BA_ "GenSigStartValue" SG_ 881 BMS_CMC_Zellspannung_132 4094;
BA_ "GenSigSwitchedByIgnition" SG_ 881 BMS_CMC_Zellspannung_132 0;
BA_ "Fehlerwert" SG_ 881 BMS_CMC_Zellspannung_132 4095;
BA_ "GenSigStartValue" SG_ 881 BMS_CMC_Zellspannung_133 4094;
BA_ "GenSigSwitchedByIgnition" SG_ 881 BMS_CMC_Zellspannung_133 0;
BA_ "Fehlerwert" SG_ 881 BMS_CMC_Zellspannung_133 4095;
BA_ "GenSigStartValue" SG_ 881 BMS_CMC_Zellspannung_134 4094;
BA_ "GenSigSwitchedByIgnition" SG_ 881 BMS_CMC_Zellspannung_134 0;
BA_ "Fehlerwert" SG_ 881 BMS_CMC_Zellspannung_134 4095;
BA_ "GenSigStartValue" SG_ 881 BMS_CMC_Zellspannung_135 4094;
BA_ "GenSigSwitchedByIgnition" SG_ 881 BMS_CMC_Zellspannung_135 0;
BA_ "Fehlerwert" SG_ 881 BMS_CMC_Zellspannung_135 4095;
BA_ "GenSigStartValue" SG_ 881 BMS_CMC_Zellspannung_136 4094;
BA_ "GenSigSwitchedByIgnition" SG_ 881 BMS_CMC_Zellspannung_136 0;
BA_ "Fehlerwert" SG_ 881 BMS_CMC_Zellspannung_136 4095;
BA_ "GenSigStartValue" SG_ 881 BMS_CMC_Zellspannung_137 4094;
BA_ "GenSigSwitchedByIgnition" SG_ 881 BMS_CMC_Zellspannung_137 0;
BA_ "Fehlerwert" SG_ 881 BMS_CMC_Zellspannung_137 4095;
BA_ "GenSigStartValue" SG_ 881 BMS_CMC_Zellspannung_138 4094;
BA_ "GenSigSwitchedByIgnition" SG_ 881 BMS_CMC_Zellspannung_138 0;
BA_ "Fehlerwert" SG_ 881 BMS_CMC_Zellspannung_138 4095;
BA_ "GenSigStartValue" SG_ 881 BMS_CMC_Zellspannung_139 4094;
BA_ "GenSigSwitchedByIgnition" SG_ 881 BMS_CMC_Zellspannung_139 0;
BA_ "Fehlerwert" SG_ 881 BMS_CMC_Zellspannung_139 4095;
BA_ "GenSigStartValue" SG_ 881 BMS_CMC_Zellspannung_140 4094;
BA_ "GenSigSwitchedByIgnition" SG_ 881 BMS_CMC_Zellspannung_140 0;
BA_ "Fehlerwert" SG_ 881 BMS_CMC_Zellspannung_140 4095;
BA_ "GenSigStartValue" SG_ 881 BMS_CMC_Zellspannung_141 4094;
BA_ "GenSigSwitchedByIgnition" SG_ 881 BMS_CMC_Zellspannung_141 0;
BA_ "Fehlerwert" SG_ 881 BMS_CMC_Zellspannung_141 4095;
BA_ "GenSigStartValue" SG_ 881 BMS_CMC_Zellspannung_142 4094;
BA_ "GenSigSwitchedByIgnition" SG_ 881 BMS_CMC_Zellspannung_142 0;
BA_ "Fehlerwert" SG_ 881 BMS_CMC_Zellspannung_142 4095;
BA_ "GenSigStartValue" SG_ 881 BMS_CMC_Zellspannung_143 4094;
BA_ "GenSigSwitchedByIgnition" SG_ 881 BMS_CMC_Zellspannung_143 0;
BA_ "Fehlerwert" SG_ 881 BMS_CMC_Zellspannung_143 4095;
BA_ "GenSigStartValue" SG_ 881 BMS_CMC_Zellspannung_144 4094;
BA_ "GenSigSwitchedByIgnition" SG_ 881 BMS_CMC_Zellspannung_144 0;
BA_ "Fehlerwert" SG_ 881 BMS_CMC_Zellspannung_144 4095;
BA_ "GenSigStartValue" SG_ 881 BMS_CMC_Zellspannung_145 4094;
BA_ "GenSigSwitchedByIgnition" SG_ 881 BMS_CMC_Zellspannung_145 0;
BA_ "Fehlerwert" SG_ 881 BMS_CMC_Zellspannung_145 4095;
BA_ "GenSigStartValue" SG_ 881 BMS_CMC_Zellspannung_146 4094;
BA_ "GenSigSwitchedByIgnition" SG_ 881 BMS_CMC_Zellspannung_146 0;
BA_ "Fehlerwert" SG_ 881 BMS_CMC_Zellspannung_146 4095;
BA_ "GenSigStartValue" SG_ 881 BMS_CMC_Zellspannung_147 4094;
BA_ "GenSigSwitchedByIgnition" SG_ 881 BMS_CMC_Zellspannung_147 0;
BA_ "Fehlerwert" SG_ 881 BMS_CMC_Zellspannung_147 4095;
BA_ "GenSigStartValue" SG_ 881 BMS_CMC_Zellspannung_148 4094;
BA_ "GenSigSwitchedByIgnition" SG_ 881 BMS_CMC_Zellspannung_148 0;
BA_ "Fehlerwert" SG_ 881 BMS_CMC_Zellspannung_148 4095;
BA_ "GenSigStartValue" SG_ 881 BMS_CMC_Zellspannung_149 4094;
BA_ "GenSigSwitchedByIgnition" SG_ 881 BMS_CMC_Zellspannung_149 0;
BA_ "Fehlerwert" SG_ 881 BMS_CMC_Zellspannung_149 4095;
BA_ "GenSigStartValue" SG_ 881 BMS_CMC_Zellspannung_150 4094;
BA_ "GenSigSwitchedByIgnition" SG_ 881 BMS_CMC_Zellspannung_150 0;
BA_ "Fehlerwert" SG_ 881 BMS_CMC_Zellspannung_150 4095;
BA_ "GenSigStartValue" SG_ 881 BMS_CMC_Zellspannung_151 4094;
BA_ "GenSigSwitchedByIgnition" SG_ 881 BMS_CMC_Zellspannung_151 0;
BA_ "Fehlerwert" SG_ 881 BMS_CMC_Zellspannung_151 4095;
BA_ "GenSigStartValue" SG_ 881 BMS_CMC_Zellspannung_152 4094;
BA_ "GenSigSwitchedByIgnition" SG_ 881 BMS_CMC_Zellspannung_152 0;
BA_ "Fehlerwert" SG_ 881 BMS_CMC_Zellspannung_152 4095;
BA_ "GenSigStartValue" SG_ 881 BMS_CMC_Zellspannung_153 4094;
BA_ "GenSigSwitchedByIgnition" SG_ 881 BMS_CMC_Zellspannung_153 0;
BA_ "Fehlerwert" SG_ 881 BMS_CMC_Zellspannung_153 4095;
BA_ "GenSigStartValue" SG_ 881 BMS_CMC_Zellspannung_154 4094;
BA_ "GenSigSwitchedByIgnition" SG_ 881 BMS_CMC_Zellspannung_154 0;
BA_ "Fehlerwert" SG_ 881 BMS_CMC_Zellspannung_154 4095;
BA_ "GenSigStartValue" SG_ 881 BMS_CMC_Zellspannung_155 4094;
BA_ "GenSigSwitchedByIgnition" SG_ 881 BMS_CMC_Zellspannung_155 0;
BA_ "Fehlerwert" SG_ 881 BMS_CMC_Zellspannung_155 4095;
BA_ "GenSigStartValue" SG_ 881 BMS_CMC_Zellspannung_156 4094;
BA_ "GenSigSwitchedByIgnition" SG_ 881 BMS_CMC_Zellspannung_156 0;
BA_ "Fehlerwert" SG_ 881 BMS_CMC_Zellspannung_156 4095;
BA_ "GenSigStartValue" SG_ 881 BMS_CMC_Zellspannung_157 4094;
BA_ "GenSigSwitchedByIgnition" SG_ 881 BMS_CMC_Zellspannung_157 0;
BA_ "Fehlerwert" SG_ 881 BMS_CMC_Zellspannung_157 4095;
BA_ "GenSigStartValue" SG_ 881 BMS_CMC_Zellspannung_158 4094;
BA_ "GenSigSwitchedByIgnition" SG_ 881 BMS_CMC_Zellspannung_158 0;
BA_ "Fehlerwert" SG_ 881 BMS_CMC_Zellspannung_158 4095;
BA_ "GenSigStartValue" SG_ 881 BMS_CMC_Zellspannung_159 4094;
BA_ "GenSigSwitchedByIgnition" SG_ 881 BMS_CMC_Zellspannung_159 0;
BA_ "Fehlerwert" SG_ 881 BMS_CMC_Zellspannung_159 4095;
BA_ "GenSigStartValue" SG_ 881 BMS_CMC_Zellspannung_160 4094;
BA_ "GenSigSwitchedByIgnition" SG_ 881 BMS_CMC_Zellspannung_160 0;
BA_ "Fehlerwert" SG_ 881 BMS_CMC_Zellspannung_160 4095;
BA_ "GenSigSendType" SG_ 2463978713 BMS_CMC_03_MUX 0;
BA_ "GenSigSwitchedByIgnition" SG_ 2463978713 BMS_CMC_03_MUX 0;
BA_ "GenSigStartValue" SG_ 2463978713 BMS_CMC_Temperatur_001 254;
BA_ "GenSigSwitchedByIgnition" SG_ 2463978713 BMS_CMC_Temperatur_001 0;
BA_ "Fehlerwert" SG_ 2463978713 BMS_CMC_Temperatur_001 255;
BA_ "GenSigStartValue" SG_ 2463978713 BMS_CMC_Temperatur_002 254;
BA_ "GenSigSwitchedByIgnition" SG_ 2463978713 BMS_CMC_Temperatur_002 0;
BA_ "Fehlerwert" SG_ 2463978713 BMS_CMC_Temperatur_002 255;
BA_ "GenSigStartValue" SG_ 2463978713 BMS_CMC_Temperatur_003 254;
BA_ "GenSigSwitchedByIgnition" SG_ 2463978713 BMS_CMC_Temperatur_003 0;
BA_ "Fehlerwert" SG_ 2463978713 BMS_CMC_Temperatur_003 255;
BA_ "GenSigStartValue" SG_ 2463978713 BMS_CMC_Temperatur_004 254;
BA_ "GenSigSwitchedByIgnition" SG_ 2463978713 BMS_CMC_Temperatur_004 0;
BA_ "Fehlerwert" SG_ 2463978713 BMS_CMC_Temperatur_004 255;
BA_ "GenSigStartValue" SG_ 2463978713 BMS_CMC_Temperatur_005 254;
BA_ "GenSigSwitchedByIgnition" SG_ 2463978713 BMS_CMC_Temperatur_005 0;
BA_ "Fehlerwert" SG_ 2463978713 BMS_CMC_Temperatur_005 255;
BA_ "GenSigStartValue" SG_ 2463978713 BMS_CMC_Temperatur_006 254;
BA_ "GenSigSwitchedByIgnition" SG_ 2463978713 BMS_CMC_Temperatur_006 0;
BA_ "Fehlerwert" SG_ 2463978713 BMS_CMC_Temperatur_006 255;
BA_ "GenSigStartValue" SG_ 2463978713 BMS_CMC_Temperatur_007 254;
BA_ "GenSigSwitchedByIgnition" SG_ 2463978713 BMS_CMC_Temperatur_007 0;
BA_ "Fehlerwert" SG_ 2463978713 BMS_CMC_Temperatur_007 255;
BA_ "GenSigStartValue" SG_ 2463978713 BMS_CMC_Temperatur_008 254;
BA_ "GenSigSwitchedByIgnition" SG_ 2463978713 BMS_CMC_Temperatur_008 0;
BA_ "Fehlerwert" SG_ 2463978713 BMS_CMC_Temperatur_008 255;
BA_ "GenSigStartValue" SG_ 2463978713 BMS_CMC_Temperatur_009 254;
BA_ "GenSigSwitchedByIgnition" SG_ 2463978713 BMS_CMC_Temperatur_009 0;
BA_ "Fehlerwert" SG_ 2463978713 BMS_CMC_Temperatur_009 255;
BA_ "GenSigStartValue" SG_ 2463978713 BMS_CMC_Temperatur_010 254;
BA_ "GenSigSwitchedByIgnition" SG_ 2463978713 BMS_CMC_Temperatur_010 0;
BA_ "Fehlerwert" SG_ 2463978713 BMS_CMC_Temperatur_010 255;
BA_ "GenSigStartValue" SG_ 2463978713 BMS_CMC_Temperatur_011 254;
BA_ "GenSigSwitchedByIgnition" SG_ 2463978713 BMS_CMC_Temperatur_011 0;
BA_ "Fehlerwert" SG_ 2463978713 BMS_CMC_Temperatur_011 255;
BA_ "GenSigStartValue" SG_ 2463978713 BMS_CMC_Temperatur_012 254;
BA_ "GenSigSwitchedByIgnition" SG_ 2463978713 BMS_CMC_Temperatur_012 0;
BA_ "Fehlerwert" SG_ 2463978713 BMS_CMC_Temperatur_012 255;
BA_ "GenSigStartValue" SG_ 2463978713 BMS_CMC_Temperatur_013 254;
BA_ "GenSigSwitchedByIgnition" SG_ 2463978713 BMS_CMC_Temperatur_013 0;
BA_ "Fehlerwert" SG_ 2463978713 BMS_CMC_Temperatur_013 255;
BA_ "GenSigStartValue" SG_ 2463978713 BMS_CMC_Temperatur_014 254;
BA_ "GenSigSwitchedByIgnition" SG_ 2463978713 BMS_CMC_Temperatur_014 0;
BA_ "Fehlerwert" SG_ 2463978713 BMS_CMC_Temperatur_014 255;
BA_ "GenSigStartValue" SG_ 2463978713 BMS_CMC_Temperatur_015 254;
BA_ "GenSigSwitchedByIgnition" SG_ 2463978713 BMS_CMC_Temperatur_015 0;
BA_ "Fehlerwert" SG_ 2463978713 BMS_CMC_Temperatur_015 255;
BA_ "GenSigStartValue" SG_ 2463978713 BMS_CMC_Temperatur_016 254;
BA_ "GenSigSwitchedByIgnition" SG_ 2463978713 BMS_CMC_Temperatur_016 0;
BA_ "Fehlerwert" SG_ 2463978713 BMS_CMC_Temperatur_016 255;
BA_ "GenSigStartValue" SG_ 2463978713 BMS_CMC_Temperatur_017 254;
BA_ "GenSigSwitchedByIgnition" SG_ 2463978713 BMS_CMC_Temperatur_017 0;
BA_ "Fehlerwert" SG_ 2463978713 BMS_CMC_Temperatur_017 255;
BA_ "GenSigStartValue" SG_ 2463978713 BMS_CMC_Temperatur_018 254;
BA_ "GenSigSwitchedByIgnition" SG_ 2463978713 BMS_CMC_Temperatur_018 0;
BA_ "Fehlerwert" SG_ 2463978713 BMS_CMC_Temperatur_018 255;
BA_ "GenSigStartValue" SG_ 2463978713 BMS_CMC_Temperatur_019 254;
BA_ "GenSigSwitchedByIgnition" SG_ 2463978713 BMS_CMC_Temperatur_019 0;
BA_ "Fehlerwert" SG_ 2463978713 BMS_CMC_Temperatur_019 255;
BA_ "GenSigStartValue" SG_ 2463978713 BMS_CMC_Temperatur_020 254;
BA_ "GenSigSwitchedByIgnition" SG_ 2463978713 BMS_CMC_Temperatur_020 0;
BA_ "Fehlerwert" SG_ 2463978713 BMS_CMC_Temperatur_020 255;
BA_ "GenSigStartValue" SG_ 2463978713 BMS_CMC_Temperatur_021 254;
BA_ "GenSigSwitchedByIgnition" SG_ 2463978713 BMS_CMC_Temperatur_021 0;
BA_ "Fehlerwert" SG_ 2463978713 BMS_CMC_Temperatur_021 255;
BA_ "GenSigStartValue" SG_ 2463978713 BMS_CMC_Temperatur_022 254;
BA_ "GenSigSwitchedByIgnition" SG_ 2463978713 BMS_CMC_Temperatur_022 0;
BA_ "Fehlerwert" SG_ 2463978713 BMS_CMC_Temperatur_022 255;
BA_ "GenSigStartValue" SG_ 2463978713 BMS_CMC_Temperatur_023 254;
BA_ "GenSigSwitchedByIgnition" SG_ 2463978713 BMS_CMC_Temperatur_023 0;
BA_ "Fehlerwert" SG_ 2463978713 BMS_CMC_Temperatur_023 255;
BA_ "GenSigStartValue" SG_ 2463978713 BMS_CMC_Temperatur_024 254;
BA_ "GenSigSwitchedByIgnition" SG_ 2463978713 BMS_CMC_Temperatur_024 0;
BA_ "Fehlerwert" SG_ 2463978713 BMS_CMC_Temperatur_024 255;
BA_ "GenSigStartValue" SG_ 2463978713 BMS_CMC_Temperatur_025 254;
BA_ "GenSigSwitchedByIgnition" SG_ 2463978713 BMS_CMC_Temperatur_025 0;
BA_ "Fehlerwert" SG_ 2463978713 BMS_CMC_Temperatur_025 255;
BA_ "GenSigStartValue" SG_ 2463978713 BMS_CMC_Temperatur_026 254;
BA_ "GenSigSwitchedByIgnition" SG_ 2463978713 BMS_CMC_Temperatur_026 0;
BA_ "Fehlerwert" SG_ 2463978713 BMS_CMC_Temperatur_026 255;
BA_ "GenSigStartValue" SG_ 2463978713 BMS_CMC_Temperatur_027 254;
BA_ "GenSigSwitchedByIgnition" SG_ 2463978713 BMS_CMC_Temperatur_027 0;
BA_ "Fehlerwert" SG_ 2463978713 BMS_CMC_Temperatur_027 255;
BA_ "GenSigStartValue" SG_ 2463978713 BMS_CMC_Temperatur_028 254;
BA_ "GenSigSwitchedByIgnition" SG_ 2463978713 BMS_CMC_Temperatur_028 0;
BA_ "Fehlerwert" SG_ 2463978713 BMS_CMC_Temperatur_028 255;
BA_ "GenSigStartValue" SG_ 2463978713 BMS_CMC_Temperatur_029 254;
BA_ "GenSigSwitchedByIgnition" SG_ 2463978713 BMS_CMC_Temperatur_029 0;
BA_ "Fehlerwert" SG_ 2463978713 BMS_CMC_Temperatur_029 255;
BA_ "GenSigStartValue" SG_ 2463978713 BMS_CMC_Temperatur_030 254;
BA_ "GenSigSwitchedByIgnition" SG_ 2463978713 BMS_CMC_Temperatur_030 0;
BA_ "Fehlerwert" SG_ 2463978713 BMS_CMC_Temperatur_030 255;
BA_ "GenSigStartValue" SG_ 2463978713 BMS_CMC_Temperatur_031 254;
BA_ "GenSigSwitchedByIgnition" SG_ 2463978713 BMS_CMC_Temperatur_031 0;
BA_ "Fehlerwert" SG_ 2463978713 BMS_CMC_Temperatur_031 255;
BA_ "GenSigStartValue" SG_ 2463978713 BMS_CMC_Temperatur_032 254;
BA_ "GenSigSwitchedByIgnition" SG_ 2463978713 BMS_CMC_Temperatur_032 0;
BA_ "Fehlerwert" SG_ 2463978713 BMS_CMC_Temperatur_032 255;
BA_ "GenSigStartValue" SG_ 2463978713 BMS_CMC_Temperatur_033 254;
BA_ "GenSigSwitchedByIgnition" SG_ 2463978713 BMS_CMC_Temperatur_033 0;
BA_ "Fehlerwert" SG_ 2463978713 BMS_CMC_Temperatur_033 255;
BA_ "GenSigStartValue" SG_ 2463978713 BMS_CMC_Temperatur_034 254;
BA_ "GenSigSwitchedByIgnition" SG_ 2463978713 BMS_CMC_Temperatur_034 0;
BA_ "Fehlerwert" SG_ 2463978713 BMS_CMC_Temperatur_034 255;
BA_ "GenSigStartValue" SG_ 2463978713 BMS_CMC_Temperatur_035 254;
BA_ "GenSigSwitchedByIgnition" SG_ 2463978713 BMS_CMC_Temperatur_035 0;
BA_ "Fehlerwert" SG_ 2463978713 BMS_CMC_Temperatur_035 255;
BA_ "GenSigStartValue" SG_ 2463978713 BMS_CMC_Temperatur_036 254;
BA_ "GenSigSwitchedByIgnition" SG_ 2463978713 BMS_CMC_Temperatur_036 0;
BA_ "Fehlerwert" SG_ 2463978713 BMS_CMC_Temperatur_036 255;
BA_ "GenSigStartValue" SG_ 2463978713 BMS_CMC_Temperatur_037 254;
BA_ "GenSigSwitchedByIgnition" SG_ 2463978713 BMS_CMC_Temperatur_037 0;
BA_ "Fehlerwert" SG_ 2463978713 BMS_CMC_Temperatur_037 255;
BA_ "GenSigStartValue" SG_ 2463978713 BMS_CMC_Temperatur_038 254;
BA_ "GenSigSwitchedByIgnition" SG_ 2463978713 BMS_CMC_Temperatur_038 0;
BA_ "Fehlerwert" SG_ 2463978713 BMS_CMC_Temperatur_038 255;
BA_ "GenSigStartValue" SG_ 2463978713 BMS_CMC_Temperatur_039 254;
BA_ "GenSigSwitchedByIgnition" SG_ 2463978713 BMS_CMC_Temperatur_039 0;
BA_ "Fehlerwert" SG_ 2463978713 BMS_CMC_Temperatur_039 255;
BA_ "GenSigStartValue" SG_ 2463978713 BMS_CMC_Temperatur_040 254;
BA_ "GenSigSwitchedByIgnition" SG_ 2463978713 BMS_CMC_Temperatur_040 0;
BA_ "Fehlerwert" SG_ 2463978713 BMS_CMC_Temperatur_040 255;
BA_ "GenSigStartValue" SG_ 2463978713 BMS_CMC_Temperatur_041 254;
BA_ "GenSigSwitchedByIgnition" SG_ 2463978713 BMS_CMC_Temperatur_041 0;
BA_ "Fehlerwert" SG_ 2463978713 BMS_CMC_Temperatur_041 255;
BA_ "GenSigStartValue" SG_ 2463978713 BMS_CMC_Temperatur_042 254;
BA_ "GenSigSwitchedByIgnition" SG_ 2463978713 BMS_CMC_Temperatur_042 0;
BA_ "Fehlerwert" SG_ 2463978713 BMS_CMC_Temperatur_042 255;
BA_ "GenSigStartValue" SG_ 2463978713 BMS_CMC_Temperatur_043 254;
BA_ "GenSigSwitchedByIgnition" SG_ 2463978713 BMS_CMC_Temperatur_043 0;
BA_ "Fehlerwert" SG_ 2463978713 BMS_CMC_Temperatur_043 255;
BA_ "GenSigStartValue" SG_ 2463978713 BMS_CMC_Temperatur_044 254;
BA_ "GenSigSwitchedByIgnition" SG_ 2463978713 BMS_CMC_Temperatur_044 0;
BA_ "Fehlerwert" SG_ 2463978713 BMS_CMC_Temperatur_044 255;
BA_ "GenSigStartValue" SG_ 2463978713 BMS_CMC_Temperatur_045 254;
BA_ "GenSigSwitchedByIgnition" SG_ 2463978713 BMS_CMC_Temperatur_045 0;
BA_ "Fehlerwert" SG_ 2463978713 BMS_CMC_Temperatur_045 255;
BA_ "GenSigStartValue" SG_ 2463978713 BMS_CMC_Temperatur_046 254;
BA_ "GenSigSwitchedByIgnition" SG_ 2463978713 BMS_CMC_Temperatur_046 0;
BA_ "Fehlerwert" SG_ 2463978713 BMS_CMC_Temperatur_046 255;
BA_ "GenSigStartValue" SG_ 2463978713 BMS_CMC_Temperatur_047 254;
BA_ "GenSigSwitchedByIgnition" SG_ 2463978713 BMS_CMC_Temperatur_047 0;
BA_ "Fehlerwert" SG_ 2463978713 BMS_CMC_Temperatur_047 255;
BA_ "GenSigStartValue" SG_ 2463978713 BMS_CMC_Temperatur_048 254;
BA_ "GenSigSwitchedByIgnition" SG_ 2463978713 BMS_CMC_Temperatur_048 0;
BA_ "Fehlerwert" SG_ 2463978713 BMS_CMC_Temperatur_048 255;
BA_ "GenSigStartValue" SG_ 2463978713 BMS_CMC_Temperatur_049 254;
BA_ "GenSigSwitchedByIgnition" SG_ 2463978713 BMS_CMC_Temperatur_049 0;
BA_ "Fehlerwert" SG_ 2463978713 BMS_CMC_Temperatur_049 255;
BA_ "GenSigStartValue" SG_ 2463978713 BMS_CMC_Temperatur_050 254;
BA_ "GenSigSwitchedByIgnition" SG_ 2463978713 BMS_CMC_Temperatur_050 0;
BA_ "Fehlerwert" SG_ 2463978713 BMS_CMC_Temperatur_050 255;
BA_ "GenSigStartValue" SG_ 2463978713 BMS_CMC_Temperatur_051 254;
BA_ "GenSigSwitchedByIgnition" SG_ 2463978713 BMS_CMC_Temperatur_051 0;
BA_ "Fehlerwert" SG_ 2463978713 BMS_CMC_Temperatur_051 255;
BA_ "GenSigStartValue" SG_ 2463978713 BMS_CMC_Temperatur_052 254;
BA_ "GenSigSwitchedByIgnition" SG_ 2463978713 BMS_CMC_Temperatur_052 0;
BA_ "Fehlerwert" SG_ 2463978713 BMS_CMC_Temperatur_052 255;
BA_ "GenSigStartValue" SG_ 2463978713 BMS_CMC_Temperatur_053 254;
BA_ "GenSigSwitchedByIgnition" SG_ 2463978713 BMS_CMC_Temperatur_053 0;
BA_ "Fehlerwert" SG_ 2463978713 BMS_CMC_Temperatur_053 255;
BA_ "GenSigStartValue" SG_ 2463978713 BMS_CMC_Temperatur_054 254;
BA_ "GenSigSwitchedByIgnition" SG_ 2463978713 BMS_CMC_Temperatur_054 0;
BA_ "Fehlerwert" SG_ 2463978713 BMS_CMC_Temperatur_054 255;
BA_ "GenSigStartValue" SG_ 2463978713 BMS_CMC_Temperatur_055 254;
BA_ "GenSigSwitchedByIgnition" SG_ 2463978713 BMS_CMC_Temperatur_055 0;
BA_ "Fehlerwert" SG_ 2463978713 BMS_CMC_Temperatur_055 255;
BA_ "GenSigStartValue" SG_ 2463978713 BMS_CMC_Temperatur_056 254;
BA_ "GenSigSwitchedByIgnition" SG_ 2463978713 BMS_CMC_Temperatur_056 0;
BA_ "Fehlerwert" SG_ 2463978713 BMS_CMC_Temperatur_056 255;
BA_ "GenSigSendType" SG_ 1400 BMS_DC_01_BZ 0;
BA_ "GenSigFuncType" SG_ 1400 BMS_DC_01_BZ 1;
BA_ "GenSigSendType" SG_ 1400 BMS_DC_01_CRC 0;
BA_ "GenSigFuncType" SG_ 1400 BMS_DC_01_CRC 2;
BA_ "GenSigSendType" SG_ 1400 BMS_DCLS_MaxLadeStrom 0;
BA_ "GenSigStartValue" SG_ 1400 BMS_DCLS_MaxLadeStrom 510;
BA_ "GenSigSwitchedByIgnition" SG_ 1400 BMS_DCLS_MaxLadeStrom 0;
BA_ "Fehlerwert" SG_ 1400 BMS_DCLS_MaxLadeStrom 511;
BA_ "GenSigSendType" SG_ 1400 BMS_DCLS_Spannung 5;
BA_ "GenSigStartValue" SG_ 1400 BMS_DCLS_Spannung 1022;
BA_ "GenSigSwitchedByIgnition" SG_ 1400 BMS_DCLS_Spannung 0;
BA_ "Fehlerwert" SG_ 1400 BMS_DCLS_Spannung 1023;
BA_ "GenSigSendType" SG_ 1400 BMS_Status_DCLS 5;
BA_ "GenSigSwitchedByIgnition" SG_ 1400 BMS_Status_DCLS 0;
BA_ "GenSigSendType" SG_ 397 BMS_MV_01_BZ 0;
BA_ "GenSigFuncType" SG_ 397 BMS_MV_01_BZ 1;
BA_ "GenSigSwitchedByIgnition" SG_ 397 BMS_MV_01_BZ 0;
BA_ "GenSigSendType" SG_ 397 BMS_MV_01_CRC 0;
BA_ "GenSigFuncType" SG_ 397 BMS_MV_01_CRC 2;
BA_ "GenSigSwitchedByIgnition" SG_ 397 BMS_MV_01_CRC 0;
BA_ "GenSigSendType" SG_ 397 BMS_MV_IstSpannung 0;
BA_ "GenSigStartValue" SG_ 397 BMS_MV_IstSpannung 254;
BA_ "GenSigSwitchedByIgnition" SG_ 397 BMS_MV_IstSpannung 0;
BA_ "Fehlerwert" SG_ 397 BMS_MV_IstSpannung 255;
BA_ "GenSigSendType" SG_ 397 BMS_MV_IstStrom 0;
BA_ "GenSigStartValue" SG_ 397 BMS_MV_IstStrom 4094;
BA_ "GenSigSwitchedByIgnition" SG_ 397 BMS_MV_IstStrom 0;
BA_ "Fehlerwert" SG_ 397 BMS_MV_IstStrom 4095;
BA_ "GenSigSendType" SG_ 397 BMS_MV_SOC_HiRes 0;
BA_ "GenSigStartValue" SG_ 397 BMS_MV_SOC_HiRes 2046;
BA_ "GenSigSwitchedByIgnition" SG_ 397 BMS_MV_SOC_HiRes 0;
BA_ "Fehlerwert" SG_ 397 BMS_MV_SOC_HiRes 2047;
BA_ "GenSigSendType" SG_ 419 BMS_MV_02_BZ 0;
BA_ "GenSigFuncType" SG_ 419 BMS_MV_02_BZ 1;
BA_ "GenSigSwitchedByIgnition" SG_ 419 BMS_MV_02_BZ 0;
BA_ "GenSigSendType" SG_ 419 BMS_MV_02_CRC 0;
BA_ "GenSigFuncType" SG_ 419 BMS_MV_02_CRC 2;
BA_ "GenSigSwitchedByIgnition" SG_ 419 BMS_MV_02_CRC 0;
BA_ "GenSigSendType" SG_ 419 BMS_MV_MaxDyn_EntladeStrom 0;
BA_ "GenSigStartValue" SG_ 419 BMS_MV_MaxDyn_EntladeStrom 2046;
BA_ "GenSigSwitchedByIgnition" SG_ 419 BMS_MV_MaxDyn_EntladeStrom 0;
BA_ "Fehlerwert" SG_ 419 BMS_MV_MaxDyn_EntladeStrom 2047;
BA_ "GenSigSendType" SG_ 419 BMS_MV_MaxDyn_LadeStrom 0;
BA_ "GenSigStartValue" SG_ 419 BMS_MV_MaxDyn_LadeStrom 2046;
BA_ "GenSigSwitchedByIgnition" SG_ 419 BMS_MV_MaxDyn_LadeStrom 0;
BA_ "Fehlerwert" SG_ 419 BMS_MV_MaxDyn_LadeStrom 2047;
BA_ "GenSigSendType" SG_ 419 BMS_MV_Min_EntladeSpannung 0;
BA_ "GenSigStartValue" SG_ 419 BMS_MV_Min_EntladeSpannung 254;
BA_ "GenSigSwitchedByIgnition" SG_ 419 BMS_MV_Min_EntladeSpannung 0;
BA_ "Fehlerwert" SG_ 419 BMS_MV_Min_EntladeSpannung 255;
BA_ "GenSigSendType" SG_ 419 BMS_MV_MinDyn_LadeSpannung 0;
BA_ "GenSigStartValue" SG_ 419 BMS_MV_MinDyn_LadeSpannung 254;
BA_ "GenSigSwitchedByIgnition" SG_ 419 BMS_MV_MinDyn_LadeSpannung 0;
BA_ "GenSigSendType" SG_ 419 BMS_MV_MinDynEntladeSpannung 0;
BA_ "GenSigStartValue" SG_ 419 BMS_MV_MinDynEntladeSpannung 254;
BA_ "GenSigSwitchedByIgnition" SG_ 419 BMS_MV_MinDynEntladeSpannung 0;
BA_ "GenSigSendType" SG_ 871 BMS_MV_03_BZ 0;
BA_ "GenSigFuncType" SG_ 871 BMS_MV_03_BZ 1;
BA_ "GenSigSwitchedByIgnition" SG_ 871 BMS_MV_03_BZ 0;
BA_ "GenSigSendType" SG_ 871 BMS_MV_03_CRC 0;
BA_ "GenSigFuncType" SG_ 871 BMS_MV_03_CRC 2;
BA_ "GenSigSwitchedByIgnition" SG_ 871 BMS_MV_03_CRC 0;
BA_ "GenSigSendType" SG_ 871 BMS_MV_Leistungsreduzierung 0;
BA_ "GenSigSwitchedByIgnition" SG_ 871 BMS_MV_Leistungsreduzierung 0;
BA_ "GenSigSendType" SG_ 871 BMS_MV_Max_LadeSpannung 0;
BA_ "GenSigStartValue" SG_ 871 BMS_MV_Max_LadeSpannung 254;
BA_ "GenSigSwitchedByIgnition" SG_ 871 BMS_MV_Max_LadeSpannung 0;
BA_ "Fehlerwert" SG_ 871 BMS_MV_Max_LadeSpannung 255;
BA_ "GenSigSendType" SG_ 871 BMS_MV_MaxPred_EntladeStrom 0;
BA_ "GenSigStartValue" SG_ 871 BMS_MV_MaxPred_EntladeStrom 2046;
BA_ "GenSigSwitchedByIgnition" SG_ 871 BMS_MV_MaxPred_EntladeStrom 0;
BA_ "Fehlerwert" SG_ 871 BMS_MV_MaxPred_EntladeStrom 2047;
BA_ "GenSigSendType" SG_ 871 BMS_MV_MaxPred_LadeStrom 0;
BA_ "GenSigStartValue" SG_ 871 BMS_MV_MaxPred_LadeStrom 2046;
BA_ "GenSigSwitchedByIgnition" SG_ 871 BMS_MV_MaxPred_LadeStrom 0;
BA_ "Fehlerwert" SG_ 871 BMS_MV_MaxPred_LadeStrom 2047;
BA_ "GenSigSendType" SG_ 871 BMS_MV_MinPred_EntladeSpannung 0;
BA_ "GenSigStartValue" SG_ 871 BMS_MV_MinPred_EntladeSpannung 254;
BA_ "GenSigSwitchedByIgnition" SG_ 871 BMS_MV_MinPred_EntladeSpannung 0;
BA_ "GenSigSendType" SG_ 871 BMS_MV_MinPred_LadeSpannung 0;
BA_ "GenSigStartValue" SG_ 871 BMS_MV_MinPred_LadeSpannung 254;
BA_ "GenSigSwitchedByIgnition" SG_ 871 BMS_MV_MinPred_LadeSpannung 0;
BA_ "GenSigSendType" SG_ 1443 BMS_MV_04_BZ 0;
BA_ "GenSigFuncType" SG_ 1443 BMS_MV_04_BZ 1;
BA_ "GenSigSwitchedByIgnition" SG_ 1443 BMS_MV_04_BZ 0;
BA_ "GenSigSendType" SG_ 1443 BMS_MV_04_CRC 0;
BA_ "GenSigFuncType" SG_ 1443 BMS_MV_04_CRC 2;
BA_ "GenSigSwitchedByIgnition" SG_ 1443 BMS_MV_04_CRC 0;
BA_ "GenSigSendType" SG_ 1443 BMS_MV_FehlerStatus 3;
BA_ "GenSigStartValue" SG_ 1443 BMS_MV_FehlerStatus 7;
BA_ "GenSigSwitchedByIgnition" SG_ 1443 BMS_MV_FehlerStatus 0;
BA_ "GenSigSendType" SG_ 1443 BMS_MV_IstModus 1;
BA_ "GenSigStartValue" SG_ 1443 BMS_MV_IstModus 7;
BA_ "GenSigSwitchedByIgnition" SG_ 1443 BMS_MV_IstModus 0;
BA_ "GenSigSendType" SG_ 1443 BMS_MV_OBD_Lampe_Anf 0;
BA_ "GenSigSwitchedByIgnition" SG_ 1443 BMS_MV_OBD_Lampe_Anf 0;
BA_ "GenSigSendType" SG_ 2589283412 BMS_MV_IstRuecklaufTemperatur 0;
BA_ "GenSigStartValue" SG_ 2589283412 BMS_MV_IstRuecklaufTemperatur 254;
BA_ "GenSigSwitchedByIgnition" SG_ 2589283412 BMS_MV_IstRuecklaufTemperatur 0;
BA_ "Fehlerwert" SG_ 2589283412 BMS_MV_IstRuecklaufTemperatur 255;
BA_ "GenSigSendType" SG_ 2589283412 BMS_MV_IstVorlaufTemperatur 0;
BA_ "GenSigStartValue" SG_ 2589283412 BMS_MV_IstVorlaufTemperatur 254;
BA_ "GenSigSwitchedByIgnition" SG_ 2589283412 BMS_MV_IstVorlaufTemperatur 0;
BA_ "Fehlerwert" SG_ 2589283412 BMS_MV_IstVorlaufTemperatur 255;
BA_ "GenSigSendType" SG_ 2589283412 BMS_MV_Soll_PWM_Pumpe 0;
BA_ "GenSigStartValue" SG_ 2589283412 BMS_MV_Soll_PWM_Pumpe 15;
BA_ "GenSigSwitchedByIgnition" SG_ 2589283412 BMS_MV_Soll_PWM_Pumpe 0;
BA_ "GenSigSendType" SG_ 2589283412 BMS_MV_SollVolumenstrom 0;
BA_ "GenSigStartValue" SG_ 2589283412 BMS_MV_SollVolumenstrom 62;
BA_ "GenSigSwitchedByIgnition" SG_ 2589283412 BMS_MV_SollVolumenstrom 0;
BA_ "Fehlerwert" SG_ 2589283412 BMS_MV_SollVolumenstrom 63;
BA_ "GenSigSendType" SG_ 2589283412 BMS_MV_SollVorlauftemperatur 0;
BA_ "GenSigStartValue" SG_ 2589283412 BMS_MV_SollVorlauftemperatur 254;
BA_ "GenSigSwitchedByIgnition" SG_ 2589283412 BMS_MV_SollVorlauftemperatur 0;
BA_ "Fehlerwert" SG_ 2589283412 BMS_MV_SollVorlauftemperatur 255;
BA_ "GenSigSendType" SG_ 2589283412 BMS_MV_Speichertechnologie 0;
BA_ "GenSigSwitchedByIgnition" SG_ 2589283412 BMS_MV_Speichertechnologie 0;
BA_ "GenSigSendType" SG_ 2589283412 BMS_MV_Temp_Epsilon 0;
BA_ "GenSigSwitchedByIgnition" SG_ 2589283412 BMS_MV_Temp_Epsilon 0;
BA_ "GenSigSendType" SG_ 2589283412 BMS_MV_Temperatur 0;
BA_ "GenSigStartValue" SG_ 2589283412 BMS_MV_Temperatur 254;
BA_ "GenSigSwitchedByIgnition" SG_ 2589283412 BMS_MV_Temperatur 0;
BA_ "Fehlerwert" SG_ 2589283412 BMS_MV_Temperatur 255;
BA_ "GenSigSendType" SG_ 2589283412 BMS_MV_Temperierung_Anf 0;
BA_ "GenSigStartValue" SG_ 2589283412 BMS_MV_Temperierung_Anf 3;
BA_ "GenSigSwitchedByIgnition" SG_ 2589283412 BMS_MV_Temperierung_Anf 0;
BA_ "GenSigSendType" SG_ 2589283608 BMS_MV_Energieinhalt 0;
BA_ "GenSigStartValue" SG_ 2589283608 BMS_MV_Energieinhalt 2046;
BA_ "GenSigSwitchedByIgnition" SG_ 2589283608 BMS_MV_Energieinhalt 0;
BA_ "Fehlerwert" SG_ 2589283608 BMS_MV_Energieinhalt 2047;
BA_ "GenSigSendType" SG_ 2589283608 BMS_MV_MaxEnergieinhalt 0;
BA_ "GenSigStartValue" SG_ 2589283608 BMS_MV_MaxEnergieinhalt 2046;
BA_ "GenSigSwitchedByIgnition" SG_ 2589283608 BMS_MV_MaxEnergieinhalt 0;
BA_ "Fehlerwert" SG_ 2589283608 BMS_MV_MaxEnergieinhalt 2047;
BA_ "GenSigSendType" SG_ 2589283606 BMS_MV_max_Grenz_SOC 0;
BA_ "GenSigStartValue" SG_ 2589283606 BMS_MV_max_Grenz_SOC 31;
BA_ "GenSigSwitchedByIgnition" SG_ 2589283606 BMS_MV_max_Grenz_SOC 0;
BA_ "GenSigSendType" SG_ 2589283606 BMS_MV_min_Grenz_SOC 0;
BA_ "GenSigStartValue" SG_ 2589283606 BMS_MV_min_Grenz_SOC 31;
BA_ "GenSigSwitchedByIgnition" SG_ 2589283606 BMS_MV_min_Grenz_SOC 0;
BA_ "GenSigSendType" SG_ 2589283606 BMS_MV_SOC_Kaltstart 0;
BA_ "GenSigStartValue" SG_ 2589283606 BMS_MV_SOC_Kaltstart 2046;
BA_ "GenSigSwitchedByIgnition" SG_ 2589283606 BMS_MV_SOC_Kaltstart 0;
BA_ "Fehlerwert" SG_ 2589283606 BMS_MV_SOC_Kaltstart 2047;
BA_ "GenSigSendType" SG_ 1021 BMS_MV_Pred_Entladeperformance 0;
BA_ "GenSigStartValue" SG_ 1021 BMS_MV_Pred_Entladeperformance 126;
BA_ "GenSigSwitchedByIgnition" SG_ 1021 BMS_MV_Pred_Entladeperformance 0;
BA_ "Fehlerwert" SG_ 1021 BMS_MV_Pred_Entladeperformance 127;
BA_ "GenSigSendType" SG_ 1021 BMS_MV_Pred_Ladeperformance 0;
BA_ "GenSigStartValue" SG_ 1021 BMS_MV_Pred_Ladeperformance 126;
BA_ "GenSigSwitchedByIgnition" SG_ 1021 BMS_MV_Pred_Ladeperformance 0;
BA_ "Fehlerwert" SG_ 1021 BMS_MV_Pred_Ladeperformance 127;
BA_ "GenSigSendType" SG_ 499 BMS_NV_01_BZ 0;
BA_ "GenSigFuncType" SG_ 499 BMS_NV_01_BZ 1;
BA_ "GenSigSwitchedByIgnition" SG_ 499 BMS_NV_01_BZ 0;
BA_ "GenSigSendType" SG_ 499 BMS_NV_01_CRC 0;
BA_ "GenSigFuncType" SG_ 499 BMS_NV_01_CRC 2;
BA_ "GenSigSwitchedByIgnition" SG_ 499 BMS_NV_01_CRC 0;
BA_ "GenSigSendType" SG_ 499 BMS_NV_BatterieAb 3;
BA_ "GenSigSwitchedByIgnition" SG_ 499 BMS_NV_BatterieAb 0;
BA_ "GenSigSendType" SG_ 499 BMS_NV_FMAus_Info 3;
BA_ "GenSigStartValue" SG_ 499 BMS_NV_FMAus_Info 1;
BA_ "GenSigSwitchedByIgnition" SG_ 499 BMS_NV_FMAus_Info 0;
BA_ "GenSigSendType" SG_ 499 BMS_NV_IstModus 3;
BA_ "GenSigStartValue" SG_ 499 BMS_NV_IstModus 3;
BA_ "GenSigSwitchedByIgnition" SG_ 499 BMS_NV_IstModus 0;
BA_ "Fehlerwert" SG_ 499 BMS_NV_IstModus 2;
BA_ "GenSigSendType" SG_ 499 BMS_NV_IstSpannung 0;
BA_ "GenSigStartValue" SG_ 499 BMS_NV_IstSpannung 16382;
BA_ "GenSigSwitchedByIgnition" SG_ 499 BMS_NV_IstSpannung 0;
BA_ "Fehlerwert" SG_ 499 BMS_NV_IstSpannung 16383;
BA_ "GenSigSendType" SG_ 499 BMS_NV_IstStrom 0;
BA_ "GenSigStartValue" SG_ 499 BMS_NV_IstStrom 262142;
BA_ "GenSigSwitchedByIgnition" SG_ 499 BMS_NV_IstStrom 0;
BA_ "Fehlerwert" SG_ 499 BMS_NV_IstStrom 262143;
BA_ "GenSigSendType" SG_ 499 BMS_NV_StSt_Nutzbare_Ladung 0;
BA_ "GenSigStartValue" SG_ 499 BMS_NV_StSt_Nutzbare_Ladung 254;
BA_ "GenSigSwitchedByIgnition" SG_ 499 BMS_NV_StSt_Nutzbare_Ladung 0;
BA_ "Fehlerwert" SG_ 499 BMS_NV_StSt_Nutzbare_Ladung 255;
BA_ "GenSigSendType" SG_ 499 BMS_NV_TE_Status 0;
BA_ "GenSigSwitchedByIgnition" SG_ 499 BMS_NV_TE_Status 0;
BA_ "GenSigSendType" SG_ 504 BMS_NV_Fehlerstatus 3;
BA_ "GenSigStartValue" SG_ 504 BMS_NV_Fehlerstatus 7;
BA_ "GenSigSwitchedByIgnition" SG_ 504 BMS_NV_Fehlerstatus 0;
BA_ "GenSigSendType" SG_ 504 BMS_NV_IMaxStart 0;
BA_ "GenSigStartValue" SG_ 504 BMS_NV_IMaxStart 254;
BA_ "GenSigSwitchedByIgnition" SG_ 504 BMS_NV_IMaxStart 0;
BA_ "Fehlerwert" SG_ 504 BMS_NV_IMaxStart 255;
BA_ "GenSigSendType" SG_ 504 BMS_NV_Qe_LI_Inhalt 0;
BA_ "GenSigStartValue" SG_ 504 BMS_NV_Qe_LI_Inhalt 4094;
BA_ "GenSigSwitchedByIgnition" SG_ 504 BMS_NV_Qe_LI_Inhalt 0;
BA_ "Fehlerwert" SG_ 504 BMS_NV_Qe_LI_Inhalt 4095;
BA_ "GenSigSendType" SG_ 504 BMS_NV_Ri_Batterie 0;
BA_ "GenSigStartValue" SG_ 504 BMS_NV_Ri_Batterie 254;
BA_ "GenSigSwitchedByIgnition" SG_ 504 BMS_NV_Ri_Batterie 0;
BA_ "Fehlerwert" SG_ 504 BMS_NV_Ri_Batterie 255;
BA_ "GenSigSendType" SG_ 504 BMS_NV_SOC 0;
BA_ "GenSigStartValue" SG_ 504 BMS_NV_SOC 254;
BA_ "GenSigSwitchedByIgnition" SG_ 504 BMS_NV_SOC 0;
BA_ "Fehlerwert" SG_ 504 BMS_NV_SOC 255;
BA_ "GenSigSendType" SG_ 504 BMS_NV_UMinStart 0;
BA_ "GenSigStartValue" SG_ 504 BMS_NV_UMinStart 254;
BA_ "GenSigSwitchedByIgnition" SG_ 504 BMS_NV_UMinStart 0;
BA_ "Fehlerwert" SG_ 504 BMS_NV_UMinStart 255;
BA_ "GenSigSendType" SG_ 874 BMS_NV_Diagnose_Anf 0;
BA_ "GenSigStartValue" SG_ 874 BMS_NV_Diagnose_Anf 7;
BA_ "GenSigSwitchedByIgnition" SG_ 874 BMS_NV_Diagnose_Anf 0;
BA_ "GenSigSendType" SG_ 874 BMS_NV_Kapazitaet_akt 0;
BA_ "GenSigStartValue" SG_ 874 BMS_NV_Kapazitaet_akt 510;
BA_ "GenSigSwitchedByIgnition" SG_ 874 BMS_NV_Kapazitaet_akt 0;
BA_ "Fehlerwert" SG_ 874 BMS_NV_Kapazitaet_akt 511;
BA_ "GenSigSendType" SG_ 874 BMS_NV_Max_EntladeStrom 0;
BA_ "GenSigStartValue" SG_ 874 BMS_NV_Max_EntladeStrom 1022;
BA_ "GenSigSwitchedByIgnition" SG_ 874 BMS_NV_Max_EntladeStrom 0;
BA_ "Fehlerwert" SG_ 874 BMS_NV_Max_EntladeStrom 1023;
BA_ "GenSigSendType" SG_ 874 BMS_NV_Max_LadeSpannung 0;
BA_ "GenSigStartValue" SG_ 874 BMS_NV_Max_LadeSpannung 62;
BA_ "GenSigSwitchedByIgnition" SG_ 874 BMS_NV_Max_LadeSpannung 0;
BA_ "Fehlerwert" SG_ 874 BMS_NV_Max_LadeSpannung 63;
BA_ "GenSigSendType" SG_ 874 BMS_NV_Max_LadeStrom 0;
BA_ "GenSigStartValue" SG_ 874 BMS_NV_Max_LadeStrom 1022;
BA_ "GenSigSwitchedByIgnition" SG_ 874 BMS_NV_Max_LadeStrom 0;
BA_ "Fehlerwert" SG_ 874 BMS_NV_Max_LadeStrom 1023;
BA_ "GenSigSendType" SG_ 874 BMS_NV_Min_EntladeSpannung 0;
BA_ "GenSigStartValue" SG_ 874 BMS_NV_Min_EntladeSpannung 62;
BA_ "GenSigSwitchedByIgnition" SG_ 874 BMS_NV_Min_EntladeSpannung 0;
BA_ "Fehlerwert" SG_ 874 BMS_NV_Min_EntladeSpannung 63;
BA_ "GenSigSendType" SG_ 874 BMS_NV_Temperatur 0;
BA_ "GenSigStartValue" SG_ 874 BMS_NV_Temperatur 254;
BA_ "GenSigSwitchedByIgnition" SG_ 874 BMS_NV_Temperatur 0;
BA_ "Fehlerwert" SG_ 874 BMS_NV_Temperatur 255;
BA_ "GenSigSendType" SG_ 2463978664 BMS_NV_Polspannung 0;
BA_ "GenSigStartValue" SG_ 2463978664 BMS_NV_Polspannung 510;
BA_ "GenSigSwitchedByIgnition" SG_ 2463978664 BMS_NV_Polspannung 0;
BA_ "Fehlerwert" SG_ 2463978664 BMS_NV_Polspannung 511;
BA_ "GenSigSendType" SG_ 2463978720 BMS_NV_05_BZ 0;
BA_ "GenSigFuncType" SG_ 2463978720 BMS_NV_05_BZ 1;
BA_ "GenSigSwitchedByIgnition" SG_ 2463978720 BMS_NV_05_BZ 0;
BA_ "GenSigSendType" SG_ 2463978720 BMS_NV_05_CRC 0;
BA_ "GenSigFuncType" SG_ 2463978720 BMS_NV_05_CRC 2;
BA_ "GenSigSwitchedByIgnition" SG_ 2463978720 BMS_NV_05_CRC 0;
BA_ "GenSigSendType" SG_ 2463978720 BMS_NV_IstDyn_EntladeStrom 0;
BA_ "GenSigStartValue" SG_ 2463978720 BMS_NV_IstDyn_EntladeStrom 2046;
BA_ "GenSigSwitchedByIgnition" SG_ 2463978720 BMS_NV_IstDyn_EntladeStrom 0;
BA_ "Fehlerwert" SG_ 2463978720 BMS_NV_IstDyn_EntladeStrom 2047;
BA_ "GenSigSendType" SG_ 2463978720 BMS_NV_IstPred_EntladeStrom 0;
BA_ "GenSigStartValue" SG_ 2463978720 BMS_NV_IstPred_EntladeStrom 2046;
BA_ "GenSigSwitchedByIgnition" SG_ 2463978720 BMS_NV_IstPred_EntladeStrom 0;
BA_ "Fehlerwert" SG_ 2463978720 BMS_NV_IstPred_EntladeStrom 2047;
BA_ "GenSigSendType" SG_ 2463978720 BMS_NV_SollDyn_EntladeSpannung 0;
BA_ "GenSigStartValue" SG_ 2463978720 BMS_NV_SollDyn_EntladeSpannung 254;
BA_ "GenSigSwitchedByIgnition" SG_ 2463978720 BMS_NV_SollDyn_EntladeSpannung 0;
BA_ "Fehlerwert" SG_ 2463978720 BMS_NV_SollDyn_EntladeSpannung 255;
BA_ "GenSigSendType" SG_ 2463978720 BMS_NV_SollPred_EntladeSpannung 0;
BA_ "GenSigStartValue" SG_ 2463978720 BMS_NV_SollPred_EntladeSpannung 254;
BA_ "GenSigSwitchedByIgnition" SG_ 2463978720 BMS_NV_SollPred_EntladeSpannung 0;
BA_ "Fehlerwert" SG_ 2463978720 BMS_NV_SollPred_EntladeSpannung 255;
BA_ "GenSigSendType" SG_ 179 Bremse_EV_01_BZ 0;
BA_ "GenSigFuncType" SG_ 179 Bremse_EV_01_BZ 1;
BA_ "GenSigSwitchedByIgnition" SG_ 179 Bremse_EV_01_BZ 0;
BA_ "GenSigSendType" SG_ 179 Bremse_EV_01_CRC 0;
BA_ "GenSigFuncType" SG_ 179 Bremse_EV_01_CRC 2;
BA_ "GenSigSwitchedByIgnition" SG_ 179 Bremse_EV_01_CRC 0;
BA_ "GenSigSendType" SG_ 179 EBKV_Activate_Fallback_ESP 0;
BA_ "GenSigSwitchedByIgnition" SG_ 179 EBKV_Activate_Fallback_ESP 0;
BA_ "GenSigSendType" SG_ 179 EBKV_Anforderung_HMS 0;
BA_ "GenSigSwitchedByIgnition" SG_ 179 EBKV_Anforderung_HMS 0;
BA_ "GenSigSendType" SG_ 179 EBKV_Aussteuerdruck 0;
BA_ "GenSigStartValue" SG_ 179 EBKV_Aussteuerdruck 254;
BA_ "GenSigSwitchedByIgnition" SG_ 179 EBKV_Aussteuerdruck 0;
BA_ "Fehlerwert" SG_ 179 EBKV_Aussteuerdruck 255;
BA_ "GenSigSendType" SG_ 179 EBKV_Bremspedalweg 0;
BA_ "GenSigSwitchedByIgnition" SG_ 179 EBKV_Bremspedalweg 0;
BA_ "Fehlerwert" SG_ 179 EBKV_Bremspedalweg 255;
BA_ "GenSigSendType" SG_ 179 EBKV_ECD_Fehler 0;
BA_ "GenSigSwitchedByIgnition" SG_ 179 EBKV_ECD_Fehler 0;
BA_ "Fehlerwert" SG_ 179 EBKV_ECD_Fehler 1;
BA_ "GenSigSendType" SG_ 179 EBKV_ECD_nicht_verfuegbar 0;
BA_ "GenSigSwitchedByIgnition" SG_ 179 EBKV_ECD_nicht_verfuegbar 0;
BA_ "GenSigSendType" SG_ 179 EBKV_Fahrer_bremst 0;
BA_ "GenSigSwitchedByIgnition" SG_ 179 EBKV_Fahrer_bremst 0;
BA_ "GenSigSendType" SG_ 179 EBKV_Fallback_Freigabe 0;
BA_ "GenSigSwitchedByIgnition" SG_ 179 EBKV_Fallback_Freigabe 0;
BA_ "GenSigSendType" SG_ 179 EBKV_Generatorsollmoment 0;
BA_ "GenSigStartValue" SG_ 179 EBKV_Generatorsollmoment 4094;
BA_ "GenSigSwitchedByIgnition" SG_ 179 EBKV_Generatorsollmoment 0;
BA_ "Fehlerwert" SG_ 179 EBKV_Generatorsollmoment 4095;
BA_ "GenSigSendType" SG_ 179 EBKV_M_Br_Fahrerwunsch 0;
BA_ "GenSigStartValue" SG_ 179 EBKV_M_Br_Fahrerwunsch 4094;
BA_ "GenSigSwitchedByIgnition" SG_ 179 EBKV_M_Br_Fahrerwunsch 0;
BA_ "Fehlerwert" SG_ 179 EBKV_M_Br_Fahrerwunsch 4095;
BA_ "GenSigSendType" SG_ 179 EBKV_QBit_Fahrer_bremst 0;
BA_ "GenSigStartValue" SG_ 179 EBKV_QBit_Fahrer_bremst 1;
BA_ "GenSigSwitchedByIgnition" SG_ 179 EBKV_QBit_Fahrer_bremst 0;
BA_ "GenSigSendType" SG_ 179 EBKV_Status 0;
BA_ "GenSigSwitchedByIgnition" SG_ 179 EBKV_Status 0;
BA_ "Fehlerwert" SG_ 179 EBKV_Status 7;
BA_ "GenSigFuncType" SG_ 2617236992 CCP_BMS_CRO_01_Data 9;
BA_ "GenSigSwitchedByIgnition" SG_ 2617236992 CCP_BMS_CRO_01_Data 0;
BA_ "GenSigFuncType" SG_ 2617236993 CCP_BMS_DTO_01_Data 9;
BA_ "GenSigSwitchedByIgnition" SG_ 2617236993 CCP_BMS_DTO_01_Data 0;
BA_ "GenSigFuncType" SG_ 2617130752 CCP_DCDC_HV_02_CRO_01_Data 9;
BA_ "GenSigSwitchedByIgnition" SG_ 2617130752 CCP_DCDC_HV_02_CRO_01_Data 0;
BA_ "GenSigFuncType" SG_ 2617130753 CCP_DCDC_HV_02_DTO_01_Data 9;
BA_ "GenSigSwitchedByIgnition" SG_ 2617130753 CCP_DCDC_HV_02_DTO_01_Data 0;
BA_ "GenSigFuncType" SG_ 2617194240 CCP_Ladegeraet_2_CRO_01_Data 9;
BA_ "GenSigSwitchedByIgnition" SG_ 2617194240 CCP_Ladegeraet_2_CRO_01_Data 0;
BA_ "GenSigFuncType" SG_ 2617194241 CCP_Ladegeraet_2_DTO_01_Data 9;
BA_ "GenSigSwitchedByIgnition" SG_ 2617194241 CCP_Ladegeraet_2_DTO_01_Data 0;
BA_ "GenSigFuncType" SG_ 2617124352 CCP_Ladegeraet_CRO_01_Data 9;
BA_ "GenSigSwitchedByIgnition" SG_ 2617124352 CCP_Ladegeraet_CRO_01_Data 0;
BA_ "GenSigFuncType" SG_ 2617124353 CCP_Ladegeraet_DTO_01_Data 9;
BA_ "GenSigSwitchedByIgnition" SG_ 2617124353 CCP_Ladegeraet_DTO_01_Data 0;
BA_ "GenSigSendType" SG_ 901 CHA_Fahrer_Umschaltung 3;
BA_ "GenSigSwitchedByIgnition" SG_ 901 CHA_Fahrer_Umschaltung 0;
BA_ "GenSigSendType" SG_ 901 CHA_Fahrer_Umschaltung_BMA 3;
BA_ "GenSigSwitchedByIgnition" SG_ 901 CHA_Fahrer_Umschaltung_BMA 0;
BA_ "GenSigSendType" SG_ 901 CHA_Ziel_FahrPr_ACC 3;
BA_ "GenSigSwitchedByIgnition" SG_ 901 CHA_Ziel_FahrPr_ACC 0;
BA_ "GenSigSendType" SG_ 901 CHA_Ziel_FahrPr_AFS 3;
BA_ "GenSigSwitchedByIgnition" SG_ 901 CHA_Ziel_FahrPr_AFS 0;
BA_ "GenSigSendType" SG_ 901 CHA_Ziel_FahrPr_AGA 3;
BA_ "GenSigSwitchedByIgnition" SG_ 901 CHA_Ziel_FahrPr_AGA 0;
BA_ "GenSigSendType" SG_ 901 CHA_Ziel_FahrPr_ALR 3;
BA_ "GenSigSwitchedByIgnition" SG_ 901 CHA_Ziel_FahrPr_ALR 0;
BA_ "GenSigSendType" SG_ 901 CHA_Ziel_FahrPr_DR 3;
BA_ "GenSigSwitchedByIgnition" SG_ 901 CHA_Ziel_FahrPr_DR 0;
BA_ "GenSigSendType" SG_ 901 CHA_Ziel_FahrPr_EPS 3;
BA_ "GenSigSwitchedByIgnition" SG_ 901 CHA_Ziel_FahrPr_EPS 0;
BA_ "GenSigSendType" SG_ 901 CHA_Ziel_FahrPr_ESP 3;
BA_ "GenSigSwitchedByIgnition" SG_ 901 CHA_Ziel_FahrPr_ESP 0;
BA_ "GenSigSendType" SG_ 901 CHA_Ziel_FahrPr_Freilauf 3;
BA_ "GenSigSwitchedByIgnition" SG_ 901 CHA_Ziel_FahrPr_Freilauf 0;
BA_ "GenSigSendType" SG_ 901 CHA_Ziel_FahrPr_GE 3;
BA_ "GenSigSwitchedByIgnition" SG_ 901 CHA_Ziel_FahrPr_GE 0;
BA_ "GenSigSendType" SG_ 901 CHA_Ziel_FahrPr_MO 3;
BA_ "GenSigSwitchedByIgnition" SG_ 901 CHA_Ziel_FahrPr_MO 0;
BA_ "GenSigSendType" SG_ 901 CHA_Ziel_FahrPr_MO_BZS 3;
BA_ "GenSigSwitchedByIgnition" SG_ 901 CHA_Ziel_FahrPr_MO_BZS 0;
BA_ "GenSigSendType" SG_ 901 CHA_Ziel_FahrPr_MO_StSt 3;
BA_ "GenSigSwitchedByIgnition" SG_ 901 CHA_Ziel_FahrPr_MO_StSt 0;
BA_ "GenSigSendType" SG_ 901 CHA_Ziel_FahrPr_PreCrash 3;
BA_ "GenSigSwitchedByIgnition" SG_ 901 CHA_Ziel_FahrPr_PreCrash 0;
BA_ "GenSigSendType" SG_ 901 CHA_Ziel_FahrPr_SAK 3;
BA_ "GenSigSwitchedByIgnition" SG_ 901 CHA_Ziel_FahrPr_SAK 0;
BA_ "GenSigSendType" SG_ 901 CHA_Ziel_FahrPr_VAQ 3;
BA_ "GenSigSwitchedByIgnition" SG_ 901 CHA_Ziel_FahrPr_VAQ 0;
BA_ "GenSigSendType" SG_ 1022 CHA_Current_Mode_BMA 3;
BA_ "GenSigSwitchedByIgnition" SG_ 1022 CHA_Current_Mode_BMA 0;
BA_ "GenSigSendType" SG_ 1022 CHA_Fahrer_Umschaltung 3;
BA_ "GenSigSwitchedByIgnition" SG_ 1022 CHA_Fahrer_Umschaltung 0;
BA_ "GenSigSendType" SG_ 1022 CHA_Fahrer_Umschaltung_BMA 3;
BA_ "GenSigSwitchedByIgnition" SG_ 1022 CHA_Fahrer_Umschaltung_BMA 0;
BA_ "GenSigSendType" SG_ 1022 CHA_Ziel_FahrPr_AGK 3;
BA_ "GenSigSwitchedByIgnition" SG_ 1022 CHA_Ziel_FahrPr_AGK 0;
BA_ "GenSigSendType" SG_ 1022 CHA_Ziel_FahrPr_BMS 3;
BA_ "GenSigSwitchedByIgnition" SG_ 1022 CHA_Ziel_FahrPr_BMS 0;
BA_ "GenSigSendType" SG_ 1022 CHA_Ziel_FahrPr_EDS 3;
BA_ "GenSigSwitchedByIgnition" SG_ 1022 CHA_Ziel_FahrPr_EDS 0;
BA_ "GenSigSendType" SG_ 1022 CHA_Ziel_FahrPr_HHC 3;
BA_ "GenSigSwitchedByIgnition" SG_ 1022 CHA_Ziel_FahrPr_HHC 0;
BA_ "GenSigSendType" SG_ 1022 CHA_Ziel_FahrPr_MO_Freilauf 3;
BA_ "GenSigSwitchedByIgnition" SG_ 1022 CHA_Ziel_FahrPr_MO_Freilauf 0;
BA_ "GenSigSendType" SG_ 1022 CHA_Ziel_FahrPr_PACC 3;
BA_ "GenSigSwitchedByIgnition" SG_ 1022 CHA_Ziel_FahrPr_PACC 0;
BA_ "GenSigSendType" SG_ 1022 CHA_Ziel_FahrPr_PDC 3;
BA_ "GenSigSwitchedByIgnition" SG_ 1022 CHA_Ziel_FahrPr_PDC 0;
BA_ "GenSigSendType" SG_ 1022 CHA_Ziel_FahrPr_Reku_ZwGas 3;
BA_ "GenSigSwitchedByIgnition" SG_ 1022 CHA_Ziel_FahrPr_Reku_ZwGas 0;
BA_ "GenSigSendType" SG_ 2589283686 DC_MV_CALID_CVN_MUX 0;
BA_ "GenSigSwitchedByIgnition" SG_ 2589283686 DC_MV_CALID_CVN_MUX 0;
BA_ "GenSigStartValue" SG_ 2589283686 DC_MV_CALID_Index_01 48;
BA_ "GenSigSwitchedByIgnition" SG_ 2589283686 DC_MV_CALID_Index_01 0;
BA_ "GenSigStartValue" SG_ 2589283686 DC_MV_CALID_Index_02 48;
BA_ "GenSigSwitchedByIgnition" SG_ 2589283686 DC_MV_CALID_Index_02 0;
BA_ "GenSigStartValue" SG_ 2589283686 DC_MV_CALID_Index_03 48;
BA_ "GenSigSwitchedByIgnition" SG_ 2589283686 DC_MV_CALID_Index_03 0;
BA_ "GenSigStartValue" SG_ 2589283686 DC_MV_CALID_Index_04 48;
BA_ "GenSigSwitchedByIgnition" SG_ 2589283686 DC_MV_CALID_Index_04 0;
BA_ "GenSigStartValue" SG_ 2589283686 DC_MV_CALID_Index_05 48;
BA_ "GenSigSwitchedByIgnition" SG_ 2589283686 DC_MV_CALID_Index_05 0;
BA_ "GenSigStartValue" SG_ 2589283686 DC_MV_CALID_Index_06 48;
BA_ "GenSigSwitchedByIgnition" SG_ 2589283686 DC_MV_CALID_Index_06 0;
BA_ "GenSigStartValue" SG_ 2589283686 DC_MV_CALID_Index_07 48;
BA_ "GenSigSwitchedByIgnition" SG_ 2589283686 DC_MV_CALID_Index_07 0;
BA_ "GenSigStartValue" SG_ 2589283686 DC_MV_CALID_Index_08 48;
BA_ "GenSigSwitchedByIgnition" SG_ 2589283686 DC_MV_CALID_Index_08 0;
BA_ "GenSigStartValue" SG_ 2589283686 DC_MV_CALID_Index_09 48;
BA_ "GenSigSwitchedByIgnition" SG_ 2589283686 DC_MV_CALID_Index_09 0;
BA_ "GenSigStartValue" SG_ 2589283686 DC_MV_CALID_Index_10 48;
BA_ "GenSigSwitchedByIgnition" SG_ 2589283686 DC_MV_CALID_Index_10 0;
BA_ "GenSigStartValue" SG_ 2589283686 DC_MV_CALID_Index_11 48;
BA_ "GenSigSwitchedByIgnition" SG_ 2589283686 DC_MV_CALID_Index_11 0;
BA_ "GenSigStartValue" SG_ 2589283686 DC_MV_CALID_Index_12 48;
BA_ "GenSigSwitchedByIgnition" SG_ 2589283686 DC_MV_CALID_Index_12 0;
BA_ "GenSigStartValue" SG_ 2589283686 DC_MV_CALID_Index_13 48;
BA_ "GenSigSwitchedByIgnition" SG_ 2589283686 DC_MV_CALID_Index_13 0;
BA_ "GenSigStartValue" SG_ 2589283686 DC_MV_CALID_Index_14 48;
BA_ "GenSigSwitchedByIgnition" SG_ 2589283686 DC_MV_CALID_Index_14 0;
BA_ "GenSigStartValue" SG_ 2589283686 DC_MV_CALID_Index_15 48;
BA_ "GenSigSwitchedByIgnition" SG_ 2589283686 DC_MV_CALID_Index_15 0;
BA_ "GenSigStartValue" SG_ 2589283686 DC_MV_CALID_Index_16 48;
BA_ "GenSigSwitchedByIgnition" SG_ 2589283686 DC_MV_CALID_Index_16 0;
BA_ "GenSigSwitchedByIgnition" SG_ 2589283686 DC_MV_CVN_Byte_1 0;
BA_ "GenSigSwitchedByIgnition" SG_ 2589283686 DC_MV_CVN_Byte_2 0;
BA_ "GenSigSwitchedByIgnition" SG_ 2589283686 DC_MV_CVN_Byte_3 0;
BA_ "GenSigSwitchedByIgnition" SG_ 2589283686 DC_MV_CVN_Byte_4 0;
BA_ "GenSigSendType" SG_ 2589283686 DC_MV_CVN_VLD 0;
BA_ "GenSigSwitchedByIgnition" SG_ 2589283686 DC_MV_CVN_VLD 0;
BA_ "GenSigSendType" SG_ 2589283393 DC_MV_Komponentenfehler_01 0;
BA_ "GenSigSwitchedByIgnition" SG_ 2589283393 DC_MV_Komponentenfehler_01 0;
BA_ "GenSigSendType" SG_ 2589283393 DC_MV_Komponentenfehler_02 0;
BA_ "GenSigSwitchedByIgnition" SG_ 2589283393 DC_MV_Komponentenfehler_02 0;
BA_ "GenSigSendType" SG_ 2589283393 DC_MV_Komponentenfehler_03 0;
BA_ "GenSigSwitchedByIgnition" SG_ 2589283393 DC_MV_Komponentenfehler_03 0;
BA_ "GenSigSendType" SG_ 2589283393 DC_MV_Komponentenfehler_04 0;
BA_ "GenSigSwitchedByIgnition" SG_ 2589283393 DC_MV_Komponentenfehler_04 0;
BA_ "GenSigSendType" SG_ 2589283393 DC_MV_Komponentenfehler_05 0;
BA_ "GenSigSwitchedByIgnition" SG_ 2589283393 DC_MV_Komponentenfehler_05 0;
BA_ "GenSigSendType" SG_ 2589283393 DC_MV_Komponentenfehler_06 0;
BA_ "GenSigSwitchedByIgnition" SG_ 2589283393 DC_MV_Komponentenfehler_06 0;
BA_ "GenSigSendType" SG_ 2589283393 DC_MV_Komponentenfehler_07 0;
BA_ "GenSigSwitchedByIgnition" SG_ 2589283393 DC_MV_Komponentenfehler_07 0;
BA_ "GenSigSendType" SG_ 2589283393 DC_MV_Komponentenfehler_08 0;
BA_ "GenSigSwitchedByIgnition" SG_ 2589283393 DC_MV_Komponentenfehler_08 0;
BA_ "GenSigSendType" SG_ 2589283393 DC_MV_Komponentenfehler_09 0;
BA_ "GenSigSwitchedByIgnition" SG_ 2589283393 DC_MV_Komponentenfehler_09 0;
BA_ "GenSigSendType" SG_ 2589283393 DC_MV_Komponentenfehler_10 0;
BA_ "GenSigSwitchedByIgnition" SG_ 2589283393 DC_MV_Komponentenfehler_10 0;
BA_ "GenSigSendType" SG_ 2589283393 DC_MV_Komponentenfehler_11 0;
BA_ "GenSigSwitchedByIgnition" SG_ 2589283393 DC_MV_Komponentenfehler_11 0;
BA_ "GenSigSendType" SG_ 2589283393 DC_MV_Komponentenfehler_12 0;
BA_ "GenSigSwitchedByIgnition" SG_ 2589283393 DC_MV_Komponentenfehler_12 0;
BA_ "GenSigSendType" SG_ 2589283393 DC_MV_Komponentenfehler_13 0;
BA_ "GenSigSwitchedByIgnition" SG_ 2589283393 DC_MV_Komponentenfehler_13 0;
BA_ "GenSigSendType" SG_ 2589283393 DC_MV_Komponentenfehler_14 0;
BA_ "GenSigSwitchedByIgnition" SG_ 2589283393 DC_MV_Komponentenfehler_14 0;
BA_ "GenSigSendType" SG_ 2589283393 DC_MV_Komponentenfehler_15 0;
BA_ "GenSigSwitchedByIgnition" SG_ 2589283393 DC_MV_Komponentenfehler_15 0;
BA_ "GenSigSendType" SG_ 2589283393 DC_MV_Komponentenfehler_16 0;
BA_ "GenSigSwitchedByIgnition" SG_ 2589283393 DC_MV_Komponentenfehler_16 0;
BA_ "GenSigSendType" SG_ 2589283393 DC_MV_Komponentenfehler_17 0;
BA_ "GenSigSwitchedByIgnition" SG_ 2589283393 DC_MV_Komponentenfehler_17 0;
BA_ "GenSigSendType" SG_ 2589283393 DC_MV_Komponentenfehler_18 0;
BA_ "GenSigSwitchedByIgnition" SG_ 2589283393 DC_MV_Komponentenfehler_18 0;
BA_ "GenSigSendType" SG_ 2589283393 DC_MV_Komponentenfehler_19 0;
BA_ "GenSigSwitchedByIgnition" SG_ 2589283393 DC_MV_Komponentenfehler_19 0;
BA_ "GenSigSendType" SG_ 2589283393 DC_MV_Komponentenfehler_20 0;
BA_ "GenSigSwitchedByIgnition" SG_ 2589283393 DC_MV_Komponentenfehler_20 0;
BA_ "GenSigSendType" SG_ 2589283393 DC_MV_Komponentenfehler_21 0;
BA_ "GenSigSwitchedByIgnition" SG_ 2589283393 DC_MV_Komponentenfehler_21 0;
BA_ "GenSigSendType" SG_ 2589283393 DC_MV_Komponentenfehler_22 0;
BA_ "GenSigSwitchedByIgnition" SG_ 2589283393 DC_MV_Komponentenfehler_22 0;
BA_ "GenSigSendType" SG_ 2589283393 DC_MV_Komponentenfehler_23 0;
BA_ "GenSigSwitchedByIgnition" SG_ 2589283393 DC_MV_Komponentenfehler_23 0;
BA_ "GenSigSendType" SG_ 2589283393 DC_MV_Komponentenfehler_24 0;
BA_ "GenSigSwitchedByIgnition" SG_ 2589283393 DC_MV_Komponentenfehler_24 0;
BA_ "GenSigSendType" SG_ 2589283393 DC_MV_Komponentenfehler_25 0;
BA_ "GenSigSwitchedByIgnition" SG_ 2589283393 DC_MV_Komponentenfehler_25 0;
BA_ "GenSigSendType" SG_ 2589283393 DC_MV_Komponentenfehler_26 0;
BA_ "GenSigSwitchedByIgnition" SG_ 2589283393 DC_MV_Komponentenfehler_26 0;
BA_ "GenSigSendType" SG_ 2589283393 DC_MV_Komponentenfehler_27 0;
BA_ "GenSigSwitchedByIgnition" SG_ 2589283393 DC_MV_Komponentenfehler_27 0;
BA_ "GenSigSendType" SG_ 2589283393 DC_MV_Komponentenfehler_28 0;
BA_ "GenSigSwitchedByIgnition" SG_ 2589283393 DC_MV_Komponentenfehler_28 0;
BA_ "GenSigSendType" SG_ 2589283393 DC_MV_Komponentenfehler_29 0;
BA_ "GenSigSwitchedByIgnition" SG_ 2589283393 DC_MV_Komponentenfehler_29 0;
BA_ "GenSigSendType" SG_ 2589283393 DC_MV_Komponentenfehler_30 0;
BA_ "GenSigSwitchedByIgnition" SG_ 2589283393 DC_MV_Komponentenfehler_30 0;
BA_ "GenSigSendType" SG_ 2589283393 DC_MV_Komponentenfehler_31 0;
BA_ "GenSigSwitchedByIgnition" SG_ 2589283393 DC_MV_Komponentenfehler_31 0;
BA_ "GenSigSendType" SG_ 2589283393 DC_MV_Komponentenfehler_VLD 0;
BA_ "GenSigSwitchedByIgnition" SG_ 2589283393 DC_MV_Komponentenfehler_VLD 0;
BA_ "GenSigSendType" SG_ 2589283855 DC_MV_Komponentenfehler_32 0;
BA_ "GenSigSwitchedByIgnition" SG_ 2589283855 DC_MV_Komponentenfehler_32 0;
BA_ "GenSigSendType" SG_ 2589283855 DC_MV_Komponentenfehler_33 0;
BA_ "GenSigSwitchedByIgnition" SG_ 2589283855 DC_MV_Komponentenfehler_33 0;
BA_ "GenSigSendType" SG_ 2589283855 DC_MV_Komponentenfehler_34 0;
BA_ "GenSigSwitchedByIgnition" SG_ 2589283855 DC_MV_Komponentenfehler_34 0;
BA_ "GenSigSendType" SG_ 2589283855 DC_MV_Komponentenfehler_35 0;
BA_ "GenSigSwitchedByIgnition" SG_ 2589283855 DC_MV_Komponentenfehler_35 0;
BA_ "GenSigSendType" SG_ 2589283855 DC_MV_Komponentenfehler_36 0;
BA_ "GenSigSwitchedByIgnition" SG_ 2589283855 DC_MV_Komponentenfehler_36 0;
BA_ "GenSigSendType" SG_ 2589283855 DC_MV_Komponentenfehler_37 0;
BA_ "GenSigSwitchedByIgnition" SG_ 2589283855 DC_MV_Komponentenfehler_37 0;
BA_ "GenSigSendType" SG_ 2589283855 DC_MV_Komponentenfehler_38 0;
BA_ "GenSigSwitchedByIgnition" SG_ 2589283855 DC_MV_Komponentenfehler_38 0;
BA_ "GenSigSendType" SG_ 2589283855 DC_MV_Komponentenfehler_39 0;
BA_ "GenSigSwitchedByIgnition" SG_ 2589283855 DC_MV_Komponentenfehler_39 0;
BA_ "GenSigSendType" SG_ 2589283855 DC_MV_Komponentenfehler_40 0;
BA_ "GenSigSwitchedByIgnition" SG_ 2589283855 DC_MV_Komponentenfehler_40 0;
BA_ "GenSigSendType" SG_ 2589283855 DC_MV_Komponentenfehler_41 0;
BA_ "GenSigSwitchedByIgnition" SG_ 2589283855 DC_MV_Komponentenfehler_41 0;
BA_ "GenSigSendType" SG_ 2589283855 DC_MV_Komponentenfehler_42 0;
BA_ "GenSigSwitchedByIgnition" SG_ 2589283855 DC_MV_Komponentenfehler_42 0;
BA_ "GenSigSendType" SG_ 2589283855 DC_MV_Komponentenfehler_43 0;
BA_ "GenSigSwitchedByIgnition" SG_ 2589283855 DC_MV_Komponentenfehler_43 0;
BA_ "GenSigSendType" SG_ 2589283855 DC_MV_Komponentenfehler_44 0;
BA_ "GenSigSwitchedByIgnition" SG_ 2589283855 DC_MV_Komponentenfehler_44 0;
BA_ "GenSigSendType" SG_ 2589283855 DC_MV_Komponentenfehler_45 0;
BA_ "GenSigSwitchedByIgnition" SG_ 2589283855 DC_MV_Komponentenfehler_45 0;
BA_ "GenSigSendType" SG_ 2589283855 DC_MV_Komponentenfehler_46 0;
BA_ "GenSigSwitchedByIgnition" SG_ 2589283855 DC_MV_Komponentenfehler_46 0;
BA_ "GenSigSendType" SG_ 2589283855 DC_MV_Komponentenfehler_47 0;
BA_ "GenSigSwitchedByIgnition" SG_ 2589283855 DC_MV_Komponentenfehler_47 0;
BA_ "GenSigSendType" SG_ 2589283855 DC_MV_Komponentenfehler_48 0;
BA_ "GenSigSwitchedByIgnition" SG_ 2589283855 DC_MV_Komponentenfehler_48 0;
BA_ "GenSigSendType" SG_ 2589283855 DC_MV_Komponentenfehler_49 0;
BA_ "GenSigSwitchedByIgnition" SG_ 2589283855 DC_MV_Komponentenfehler_49 0;
BA_ "GenSigSendType" SG_ 2589283855 DC_MV_Komponentenfehler_50 0;
BA_ "GenSigSwitchedByIgnition" SG_ 2589283855 DC_MV_Komponentenfehler_50 0;
BA_ "GenSigSendType" SG_ 2589283855 DC_MV_Komponentenfehler_51 0;
BA_ "GenSigSwitchedByIgnition" SG_ 2589283855 DC_MV_Komponentenfehler_51 0;
BA_ "GenSigSendType" SG_ 2589283855 DC_MV_Komponentenfehler_52 0;
BA_ "GenSigSwitchedByIgnition" SG_ 2589283855 DC_MV_Komponentenfehler_52 0;
BA_ "GenSigSendType" SG_ 2589283855 DC_MV_Komponentenfehler_53 0;
BA_ "GenSigSwitchedByIgnition" SG_ 2589283855 DC_MV_Komponentenfehler_53 0;
BA_ "GenSigSendType" SG_ 2589283855 DC_MV_Komponentenfehler_54 0;
BA_ "GenSigSwitchedByIgnition" SG_ 2589283855 DC_MV_Komponentenfehler_54 0;
BA_ "GenSigSendType" SG_ 2589283855 DC_MV_Komponentenfehler_55 0;
BA_ "GenSigSwitchedByIgnition" SG_ 2589283855 DC_MV_Komponentenfehler_55 0;
BA_ "GenSigSendType" SG_ 2589283855 DC_MV_Komponentenfehler_56 0;
BA_ "GenSigSwitchedByIgnition" SG_ 2589283855 DC_MV_Komponentenfehler_56 0;
BA_ "GenSigSendType" SG_ 2589283855 DC_MV_Komponentenfehler_57 0;
BA_ "GenSigSwitchedByIgnition" SG_ 2589283855 DC_MV_Komponentenfehler_57 0;
BA_ "GenSigSendType" SG_ 2589283855 DC_MV_Komponentenfehler_58 0;
BA_ "GenSigSwitchedByIgnition" SG_ 2589283855 DC_MV_Komponentenfehler_58 0;
BA_ "GenSigSendType" SG_ 2589283855 DC_MV_Komponentenfehler_59 0;
BA_ "GenSigSwitchedByIgnition" SG_ 2589283855 DC_MV_Komponentenfehler_59 0;
BA_ "GenSigSendType" SG_ 2589283855 DC_MV_Komponentenfehler_60 0;
BA_ "GenSigSwitchedByIgnition" SG_ 2589283855 DC_MV_Komponentenfehler_60 0;
BA_ "GenSigSendType" SG_ 2589283855 DC_MV_Komponentenfehler_61 0;
BA_ "GenSigSwitchedByIgnition" SG_ 2589283855 DC_MV_Komponentenfehler_61 0;
BA_ "GenSigSendType" SG_ 2589283855 DC_MV_Komponentenfehler_62 0;
BA_ "GenSigSwitchedByIgnition" SG_ 2589283855 DC_MV_Komponentenfehler_62 0;
BA_ "GenSigSendType" SG_ 2589283856 DC_MV_Komponentenfehler_63 0;
BA_ "GenSigSwitchedByIgnition" SG_ 2589283856 DC_MV_Komponentenfehler_63 0;
BA_ "GenSigSendType" SG_ 2589283856 DC_MV_Komponentenfehler_64 0;
BA_ "GenSigSwitchedByIgnition" SG_ 2589283856 DC_MV_Komponentenfehler_64 0;
BA_ "GenSigSendType" SG_ 2589283856 DC_MV_Komponentenfehler_65 0;
BA_ "GenSigSwitchedByIgnition" SG_ 2589283856 DC_MV_Komponentenfehler_65 0;
BA_ "GenSigSendType" SG_ 2589283856 DC_MV_Komponentenfehler_66 0;
BA_ "GenSigSwitchedByIgnition" SG_ 2589283856 DC_MV_Komponentenfehler_66 0;
BA_ "GenSigSendType" SG_ 2589283856 DC_MV_Komponentenfehler_67 0;
BA_ "GenSigSwitchedByIgnition" SG_ 2589283856 DC_MV_Komponentenfehler_67 0;
BA_ "GenSigSendType" SG_ 2589283856 DC_MV_Komponentenfehler_68 0;
BA_ "GenSigSwitchedByIgnition" SG_ 2589283856 DC_MV_Komponentenfehler_68 0;
BA_ "GenSigSendType" SG_ 2589283856 DC_MV_Komponentenfehler_69 0;
BA_ "GenSigSwitchedByIgnition" SG_ 2589283856 DC_MV_Komponentenfehler_69 0;
BA_ "GenSigSendType" SG_ 2589283856 DC_MV_Komponentenfehler_70 0;
BA_ "GenSigSwitchedByIgnition" SG_ 2589283856 DC_MV_Komponentenfehler_70 0;
BA_ "GenSigSendType" SG_ 2589283856 DC_MV_Komponentenfehler_71 0;
BA_ "GenSigSwitchedByIgnition" SG_ 2589283856 DC_MV_Komponentenfehler_71 0;
BA_ "GenSigSendType" SG_ 2589283856 DC_MV_Komponentenfehler_72 0;
BA_ "GenSigSwitchedByIgnition" SG_ 2589283856 DC_MV_Komponentenfehler_72 0;
BA_ "GenSigSendType" SG_ 2589283856 DC_MV_Komponentenfehler_73 0;
BA_ "GenSigSwitchedByIgnition" SG_ 2589283856 DC_MV_Komponentenfehler_73 0;
BA_ "GenSigSendType" SG_ 2589283856 DC_MV_Komponentenfehler_74 0;
BA_ "GenSigSwitchedByIgnition" SG_ 2589283856 DC_MV_Komponentenfehler_74 0;
BA_ "GenSigSendType" SG_ 2589283856 DC_MV_Komponentenfehler_75 0;
BA_ "GenSigSwitchedByIgnition" SG_ 2589283856 DC_MV_Komponentenfehler_75 0;
BA_ "GenSigSendType" SG_ 2589283856 DC_MV_Komponentenfehler_76 0;
BA_ "GenSigSwitchedByIgnition" SG_ 2589283856 DC_MV_Komponentenfehler_76 0;
BA_ "GenSigSendType" SG_ 2589283856 DC_MV_Komponentenfehler_77 0;
BA_ "GenSigSwitchedByIgnition" SG_ 2589283856 DC_MV_Komponentenfehler_77 0;
BA_ "GenSigSendType" SG_ 2589283856 DC_MV_Komponentenfehler_78 0;
BA_ "GenSigSwitchedByIgnition" SG_ 2589283856 DC_MV_Komponentenfehler_78 0;
BA_ "GenSigSendType" SG_ 2589283856 DC_MV_Komponentenfehler_79 0;
BA_ "GenSigSwitchedByIgnition" SG_ 2589283856 DC_MV_Komponentenfehler_79 0;
BA_ "GenSigSendType" SG_ 2589283856 DC_MV_Komponentenfehler_80 0;
BA_ "GenSigSwitchedByIgnition" SG_ 2589283856 DC_MV_Komponentenfehler_80 0;
BA_ "GenSigSendType" SG_ 2589283856 DC_MV_Komponentenfehler_81 0;
BA_ "GenSigSwitchedByIgnition" SG_ 2589283856 DC_MV_Komponentenfehler_81 0;
BA_ "GenSigSendType" SG_ 2589283856 DC_MV_Komponentenfehler_82 0;
BA_ "GenSigSwitchedByIgnition" SG_ 2589283856 DC_MV_Komponentenfehler_82 0;
BA_ "GenSigSendType" SG_ 2589283856 DC_MV_Komponentenfehler_83 0;
BA_ "GenSigSwitchedByIgnition" SG_ 2589283856 DC_MV_Komponentenfehler_83 0;
BA_ "GenSigSendType" SG_ 2589283856 DC_MV_Komponentenfehler_84 0;
BA_ "GenSigSwitchedByIgnition" SG_ 2589283856 DC_MV_Komponentenfehler_84 0;
BA_ "GenSigSendType" SG_ 2589283856 DC_MV_Komponentenfehler_85 0;
BA_ "GenSigSwitchedByIgnition" SG_ 2589283856 DC_MV_Komponentenfehler_85 0;
BA_ "GenSigSendType" SG_ 2589283856 DC_MV_Komponentenfehler_86 0;
BA_ "GenSigSwitchedByIgnition" SG_ 2589283856 DC_MV_Komponentenfehler_86 0;
BA_ "GenSigSendType" SG_ 2589283856 DC_MV_Komponentenfehler_87 0;
BA_ "GenSigSwitchedByIgnition" SG_ 2589283856 DC_MV_Komponentenfehler_87 0;
BA_ "GenSigSendType" SG_ 2589283856 DC_MV_Komponentenfehler_88 0;
BA_ "GenSigSwitchedByIgnition" SG_ 2589283856 DC_MV_Komponentenfehler_88 0;
BA_ "GenSigSendType" SG_ 2589283856 DC_MV_Komponentenfehler_89 0;
BA_ "GenSigSwitchedByIgnition" SG_ 2589283856 DC_MV_Komponentenfehler_89 0;
BA_ "GenSigSendType" SG_ 2589283856 DC_MV_Komponentenfehler_90 0;
BA_ "GenSigSwitchedByIgnition" SG_ 2589283856 DC_MV_Komponentenfehler_90 0;
BA_ "GenSigSendType" SG_ 2589283856 DC_MV_Komponentenfehler_91 0;
BA_ "GenSigSwitchedByIgnition" SG_ 2589283856 DC_MV_Komponentenfehler_91 0;
BA_ "GenSigSendType" SG_ 2589283856 DC_MV_Komponentenfehler_92 0;
BA_ "GenSigSwitchedByIgnition" SG_ 2589283856 DC_MV_Komponentenfehler_92 0;
BA_ "GenSigSendType" SG_ 2589283856 DC_MV_Komponentenfehler_93 0;
BA_ "GenSigSwitchedByIgnition" SG_ 2589283856 DC_MV_Komponentenfehler_93 0;
BA_ "GenSigSendType" SG_ 2589283857 DC_MV_Komponentenfehler_100 0;
BA_ "GenSigSwitchedByIgnition" SG_ 2589283857 DC_MV_Komponentenfehler_100 0;
BA_ "GenSigSendType" SG_ 2589283857 DC_MV_Komponentenfehler_101 0;
BA_ "GenSigSwitchedByIgnition" SG_ 2589283857 DC_MV_Komponentenfehler_101 0;
BA_ "GenSigSendType" SG_ 2589283857 DC_MV_Komponentenfehler_102 0;
BA_ "GenSigSwitchedByIgnition" SG_ 2589283857 DC_MV_Komponentenfehler_102 0;
BA_ "GenSigSendType" SG_ 2589283857 DC_MV_Komponentenfehler_103 0;
BA_ "GenSigSwitchedByIgnition" SG_ 2589283857 DC_MV_Komponentenfehler_103 0;
BA_ "GenSigSendType" SG_ 2589283857 DC_MV_Komponentenfehler_104 0;
BA_ "GenSigSwitchedByIgnition" SG_ 2589283857 DC_MV_Komponentenfehler_104 0;
BA_ "GenSigSendType" SG_ 2589283857 DC_MV_Komponentenfehler_105 0;
BA_ "GenSigSwitchedByIgnition" SG_ 2589283857 DC_MV_Komponentenfehler_105 0;
BA_ "GenSigSendType" SG_ 2589283857 DC_MV_Komponentenfehler_106 0;
BA_ "GenSigSwitchedByIgnition" SG_ 2589283857 DC_MV_Komponentenfehler_106 0;
BA_ "GenSigSendType" SG_ 2589283857 DC_MV_Komponentenfehler_107 0;
BA_ "GenSigSwitchedByIgnition" SG_ 2589283857 DC_MV_Komponentenfehler_107 0;
BA_ "GenSigSendType" SG_ 2589283857 DC_MV_Komponentenfehler_108 0;
BA_ "GenSigSwitchedByIgnition" SG_ 2589283857 DC_MV_Komponentenfehler_108 0;
BA_ "GenSigSendType" SG_ 2589283857 DC_MV_Komponentenfehler_109 0;
BA_ "GenSigSwitchedByIgnition" SG_ 2589283857 DC_MV_Komponentenfehler_109 0;
BA_ "GenSigSendType" SG_ 2589283857 DC_MV_Komponentenfehler_110 0;
BA_ "GenSigSwitchedByIgnition" SG_ 2589283857 DC_MV_Komponentenfehler_110 0;
BA_ "GenSigSendType" SG_ 2589283857 DC_MV_Komponentenfehler_111 0;
BA_ "GenSigSwitchedByIgnition" SG_ 2589283857 DC_MV_Komponentenfehler_111 0;
BA_ "GenSigSendType" SG_ 2589283857 DC_MV_Komponentenfehler_112 0;
BA_ "GenSigSwitchedByIgnition" SG_ 2589283857 DC_MV_Komponentenfehler_112 0;
BA_ "GenSigSendType" SG_ 2589283857 DC_MV_Komponentenfehler_113 0;
BA_ "GenSigSwitchedByIgnition" SG_ 2589283857 DC_MV_Komponentenfehler_113 0;
BA_ "GenSigSendType" SG_ 2589283857 DC_MV_Komponentenfehler_114 0;
BA_ "GenSigSwitchedByIgnition" SG_ 2589283857 DC_MV_Komponentenfehler_114 0;
BA_ "GenSigSendType" SG_ 2589283857 DC_MV_Komponentenfehler_115 0;
BA_ "GenSigSwitchedByIgnition" SG_ 2589283857 DC_MV_Komponentenfehler_115 0;
BA_ "GenSigSendType" SG_ 2589283857 DC_MV_Komponentenfehler_116 0;
BA_ "GenSigSwitchedByIgnition" SG_ 2589283857 DC_MV_Komponentenfehler_116 0;
BA_ "GenSigSendType" SG_ 2589283857 DC_MV_Komponentenfehler_117 0;
BA_ "GenSigSwitchedByIgnition" SG_ 2589283857 DC_MV_Komponentenfehler_117 0;
BA_ "GenSigSendType" SG_ 2589283857 DC_MV_Komponentenfehler_118 0;
BA_ "GenSigSwitchedByIgnition" SG_ 2589283857 DC_MV_Komponentenfehler_118 0;
BA_ "GenSigSendType" SG_ 2589283857 DC_MV_Komponentenfehler_119 0;
BA_ "GenSigSwitchedByIgnition" SG_ 2589283857 DC_MV_Komponentenfehler_119 0;
BA_ "GenSigSendType" SG_ 2589283857 DC_MV_Komponentenfehler_120 0;
BA_ "GenSigSwitchedByIgnition" SG_ 2589283857 DC_MV_Komponentenfehler_120 0;
BA_ "GenSigSendType" SG_ 2589283857 DC_MV_Komponentenfehler_121 0;
BA_ "GenSigSwitchedByIgnition" SG_ 2589283857 DC_MV_Komponentenfehler_121 0;
BA_ "GenSigSendType" SG_ 2589283857 DC_MV_Komponentenfehler_122 0;
BA_ "GenSigSwitchedByIgnition" SG_ 2589283857 DC_MV_Komponentenfehler_122 0;
BA_ "GenSigSendType" SG_ 2589283857 DC_MV_Komponentenfehler_123 0;
BA_ "GenSigSwitchedByIgnition" SG_ 2589283857 DC_MV_Komponentenfehler_123 0;
BA_ "GenSigSendType" SG_ 2589283857 DC_MV_Komponentenfehler_124 0;
BA_ "GenSigSwitchedByIgnition" SG_ 2589283857 DC_MV_Komponentenfehler_124 0;
BA_ "GenSigSendType" SG_ 2589283857 DC_MV_Komponentenfehler_94 0;
BA_ "GenSigSwitchedByIgnition" SG_ 2589283857 DC_MV_Komponentenfehler_94 0;
BA_ "GenSigSendType" SG_ 2589283857 DC_MV_Komponentenfehler_95 0;
BA_ "GenSigSwitchedByIgnition" SG_ 2589283857 DC_MV_Komponentenfehler_95 0;
BA_ "GenSigSendType" SG_ 2589283857 DC_MV_Komponentenfehler_96 0;
BA_ "GenSigSwitchedByIgnition" SG_ 2589283857 DC_MV_Komponentenfehler_96 0;
BA_ "GenSigSendType" SG_ 2589283857 DC_MV_Komponentenfehler_97 0;
BA_ "GenSigSwitchedByIgnition" SG_ 2589283857 DC_MV_Komponentenfehler_97 0;
BA_ "GenSigSendType" SG_ 2589283857 DC_MV_Komponentenfehler_98 0;
BA_ "GenSigSwitchedByIgnition" SG_ 2589283857 DC_MV_Komponentenfehler_98 0;
BA_ "GenSigSendType" SG_ 2589283857 DC_MV_Komponentenfehler_99 0;
BA_ "GenSigSwitchedByIgnition" SG_ 2589283857 DC_MV_Komponentenfehler_99 0;
BA_ "GenSigSendType" SG_ 2589283858 DC_MV_Komponentenfehler_125 0;
BA_ "GenSigSwitchedByIgnition" SG_ 2589283858 DC_MV_Komponentenfehler_125 0;
BA_ "GenSigSendType" SG_ 2589283858 DC_MV_Komponentenfehler_126 0;
BA_ "GenSigSwitchedByIgnition" SG_ 2589283858 DC_MV_Komponentenfehler_126 0;
BA_ "GenSigSendType" SG_ 2589283858 DC_MV_Komponentenfehler_127 0;
BA_ "GenSigSwitchedByIgnition" SG_ 2589283858 DC_MV_Komponentenfehler_127 0;
BA_ "GenSigSendType" SG_ 2589283858 DC_MV_Komponentenfehler_128 0;
BA_ "GenSigSwitchedByIgnition" SG_ 2589283858 DC_MV_Komponentenfehler_128 0;
BA_ "GenSigSendType" SG_ 2589283858 DC_MV_Komponentenfehler_129 0;
BA_ "GenSigSwitchedByIgnition" SG_ 2589283858 DC_MV_Komponentenfehler_129 0;
BA_ "GenSigSendType" SG_ 2589283858 DC_MV_Komponentenfehler_130 0;
BA_ "GenSigSwitchedByIgnition" SG_ 2589283858 DC_MV_Komponentenfehler_130 0;
BA_ "GenSigSendType" SG_ 2589283858 DC_MV_Komponentenfehler_131 0;
BA_ "GenSigSwitchedByIgnition" SG_ 2589283858 DC_MV_Komponentenfehler_131 0;
BA_ "GenSigSendType" SG_ 2589283858 DC_MV_Komponentenfehler_132 0;
BA_ "GenSigSwitchedByIgnition" SG_ 2589283858 DC_MV_Komponentenfehler_132 0;
BA_ "GenSigSendType" SG_ 2589283858 DC_MV_Komponentenfehler_133 0;
BA_ "GenSigSwitchedByIgnition" SG_ 2589283858 DC_MV_Komponentenfehler_133 0;
BA_ "GenSigSendType" SG_ 2589283858 DC_MV_Komponentenfehler_134 0;
BA_ "GenSigSwitchedByIgnition" SG_ 2589283858 DC_MV_Komponentenfehler_134 0;
BA_ "GenSigSendType" SG_ 2589283858 DC_MV_Komponentenfehler_135 0;
BA_ "GenSigSwitchedByIgnition" SG_ 2589283858 DC_MV_Komponentenfehler_135 0;
BA_ "GenSigSendType" SG_ 2589283858 DC_MV_Komponentenfehler_136 0;
BA_ "GenSigSwitchedByIgnition" SG_ 2589283858 DC_MV_Komponentenfehler_136 0;
BA_ "GenSigSendType" SG_ 2589283858 DC_MV_Komponentenfehler_137 0;
BA_ "GenSigSwitchedByIgnition" SG_ 2589283858 DC_MV_Komponentenfehler_137 0;
BA_ "GenSigSendType" SG_ 2589283858 DC_MV_Komponentenfehler_138 0;
BA_ "GenSigSwitchedByIgnition" SG_ 2589283858 DC_MV_Komponentenfehler_138 0;
BA_ "GenSigSendType" SG_ 2589283858 DC_MV_Komponentenfehler_139 0;
BA_ "GenSigSwitchedByIgnition" SG_ 2589283858 DC_MV_Komponentenfehler_139 0;
BA_ "GenSigSendType" SG_ 2589283858 DC_MV_Komponentenfehler_140 0;
BA_ "GenSigSwitchedByIgnition" SG_ 2589283858 DC_MV_Komponentenfehler_140 0;
BA_ "GenSigSendType" SG_ 2589283858 DC_MV_Komponentenfehler_141 0;
BA_ "GenSigSwitchedByIgnition" SG_ 2589283858 DC_MV_Komponentenfehler_141 0;
BA_ "GenSigSendType" SG_ 2589283858 DC_MV_Komponentenfehler_142 0;
BA_ "GenSigSwitchedByIgnition" SG_ 2589283858 DC_MV_Komponentenfehler_142 0;
BA_ "GenSigSendType" SG_ 2589283858 DC_MV_Komponentenfehler_143 0;
BA_ "GenSigSwitchedByIgnition" SG_ 2589283858 DC_MV_Komponentenfehler_143 0;
BA_ "GenSigSendType" SG_ 2589283858 DC_MV_Komponentenfehler_144 0;
BA_ "GenSigSwitchedByIgnition" SG_ 2589283858 DC_MV_Komponentenfehler_144 0;
BA_ "GenSigSendType" SG_ 2589283858 DC_MV_Komponentenfehler_145 0;
BA_ "GenSigSwitchedByIgnition" SG_ 2589283858 DC_MV_Komponentenfehler_145 0;
